VERSION "HNNBNNNYNNNNNNNNNNNNNNNNNNNNNNNNNNNNNNNNNN/4/%%%/4/'%**4NNN///"

NS_ :

BS_:

BU_: BAP_Tester CGS Gateway Gateway_PAG HUD Kombi Kombi_LB Kombi_PAG Waehlhebel_SB

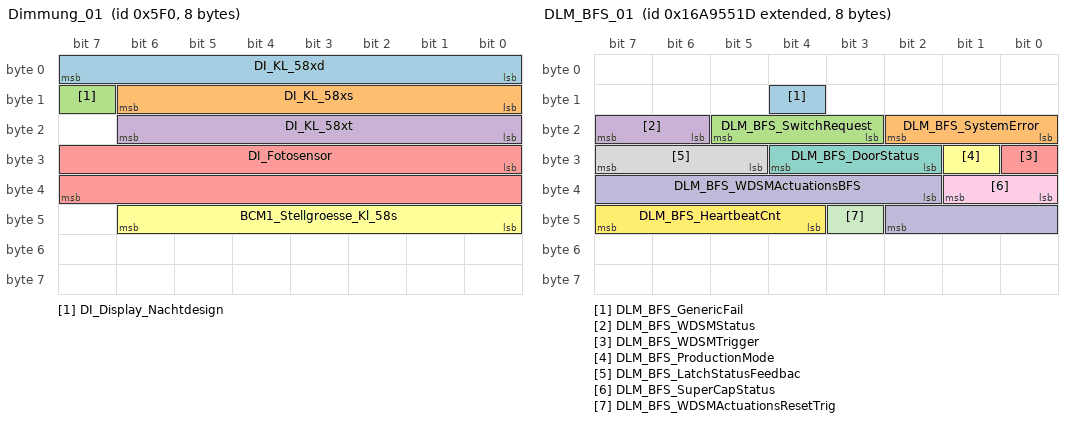
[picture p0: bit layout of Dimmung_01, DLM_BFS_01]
BO_ 1520 Dimmung_01: 8 Gateway
 SG_ DI_KL_58xd : 0|8@1+ (1,0) [0|253] ""  CGS,Kombi,Kombi_LB,Kombi_PAG,Waehlhebel_SB
 SG_ DI_KL_58xs : 8|7@1+ (1,0) [0|100] "Unit_PerCent"  Kombi,Kombi_LB,Kombi_PAG
 SG_ DI_Display_Nachtdesign : 15|1@1+ (1.0,0.0) [0.0|1] ""  HUD,Kombi,Kombi_LB
 SG_ DI_KL_58xt : 16|7@1+ (1,0) [0|100] "Unit_PerCent"  CGS,Kombi,Kombi_LB,Kombi_PAG,Waehlhebel_SB
 SG_ DI_Fotosensor : 24|16@1+ (1,0) [0|65535] ""  Kombi,Kombi_LB,Kombi_PAG
 SG_ BCM1_Stellgroesse_Kl_58s : 40|7@1+ (1,0) [0|100] ""  Vector__XXX

BO_ 2527679773 DLM_BFS_01: 8 Gateway
 SG_ DLM_BFS_GenericFail : 12|1@1+ (1.0,0.0) [0.0|1] ""  Kombi_LB
 SG_ DLM_BFS_SystemError : 16|3@1+ (1.0,0.0) [0.0|7] ""  Kombi_LB
 SG_ DLM_BFS_SwitchRequest : 19|3@1+ (1.0,0.0) [0.0|7] ""  Kombi_LB
 SG_ DLM_BFS_WDSMStatus : 22|2@1+ (1.0,0.0) [0.0|3] ""  Kombi_LB
 SG_ DLM_BFS_WDSMTrigger : 24|1@1+ (1.0,0.0) [0.0|1] ""  Kombi_LB
 SG_ DLM_BFS_ProductionMode : 25|1@1+ (1.0,0.0) [0.0|1] ""  Kombi_LB
 SG_ DLM_BFS_DoorStatus : 26|3@1+ (1.0,0.0) [0.0|7] ""  Kombi_LB
 SG_ DLM_BFS_LatchStatusFeedbac : 29|3@1+ (1.0,0.0) [0.0|7] ""  Kombi_LB
 SG_ DLM_BFS_SuperCapStatus : 32|2@1+ (1.0,0.0) [0.0|3] ""  Kombi_LB
 SG_ DLM_BFS_WDSMActuationsBFS : 34|9@1+ (1,0) [0|510] ""  Vector__XXX
 SG_ DLM_BFS_WDSMActuationsResetTrig : 43|1@1+ (1.0,0.0) [0.0|1] ""  Vector__XXX
 SG_ DLM_BFS_HeartbeatCnt : 44|4@1+ (1,0) [1|15] "Unit_None"  Vector__XXX

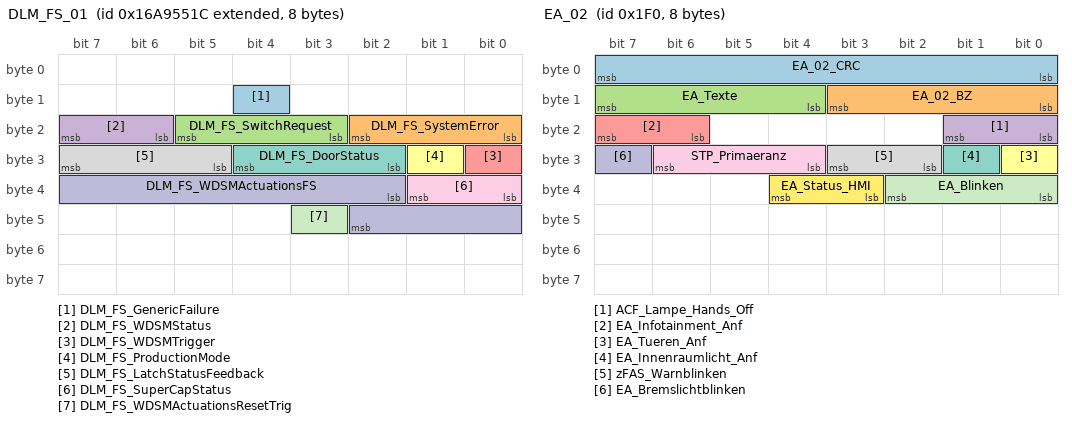
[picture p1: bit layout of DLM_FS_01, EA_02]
BO_ 2527679772 DLM_FS_01: 8 Gateway
 SG_ DLM_FS_GenericFailure : 12|1@1+ (1.0,0.0) [0.0|1] ""  Kombi_LB
 SG_ DLM_FS_SystemError : 16|3@1+ (1.0,0.0) [0.0|7] ""  Kombi_LB
 SG_ DLM_FS_SwitchRequest : 19|3@1+ (1.0,0.0) [0.0|7] ""  Kombi_LB
 SG_ DLM_FS_WDSMStatus : 22|2@1+ (1.0,0.0) [0.0|3] ""  Kombi_LB
 SG_ DLM_FS_WDSMTrigger : 24|1@1+ (1.0,0.0) [0.0|1] ""  Kombi_LB
 SG_ DLM_FS_ProductionMode : 25|1@1+ (1.0,0.0) [0.0|1] ""  Kombi_LB
 SG_ DLM_FS_DoorStatus : 26|3@1+ (1.0,0.0) [0.0|7] ""  Kombi_LB
 SG_ DLM_FS_LatchStatusFeedback : 29|3@1+ (1.0,0.0) [0.0|7] ""  Kombi_LB
 SG_ DLM_FS_SuperCapStatus : 32|2@1+ (1.0,0.0) [0.0|3] ""  Kombi_LB
 SG_ DLM_FS_WDSMActuationsFS : 34|9@1+ (1,0) [0|510] ""  Vector__XXX
 SG_ DLM_FS_WDSMActuationsResetTrig : 43|1@1+ (1.0,0.0) [0.0|1] ""  Vector__XXX

BO_ 496 EA_02: 8 Gateway
 SG_ EA_02_CRC : 0|8@1+ (1,0) [0|255] ""  Kombi,Kombi_LB,Kombi_PAG
 SG_ EA_02_BZ : 8|4@1+ (1,0) [0|15] ""  Kombi,Kombi_LB,Kombi_PAG
 SG_ EA_Texte : 12|4@1+ (1.0,0.0) [0.0|15] ""  HUD,Kombi,Kombi_LB,Kombi_PAG
 SG_ ACF_Lampe_Hands_Off : 16|2@1+ (1.0,0.0) [0.0|3] ""  HUD,Kombi,Kombi_LB,Kombi_PAG
 SG_ EA_Infotainment_Anf : 22|2@1+ (1.0,0.0) [0.0|3] ""  Vector__XXX
 SG_ EA_Tueren_Anf : 24|1@1+ (1.0,0.0) [0.0|1] ""  Vector__XXX
 SG_ EA_Innenraumlicht_Anf : 25|1@1+ (1.0,0.0) [0.0|1] ""  Vector__XXX
 SG_ zFAS_Warnblinken : 26|2@1+ (1.0,0.0) [0.0|3] ""  Vector__XXX
 SG_ STP_Primaeranz : 28|3@1+ (1.0,0.0) [0.0|7] ""  HUD,Kombi,Kombi_LB,Kombi_PAG
 SG_ EA_Bremslichtblinken : 31|1@1+ (1.0,0.0) [0.0|1] ""  Vector__XXX
 SG_ EA_Blinken : 32|3@1+ (1.0,0.0) [0.0|7] ""  Vector__XXX
 SG_ EA_Status_HMI : 35|2@1+ (1.0,0.0) [0.0|3] ""  Kombi

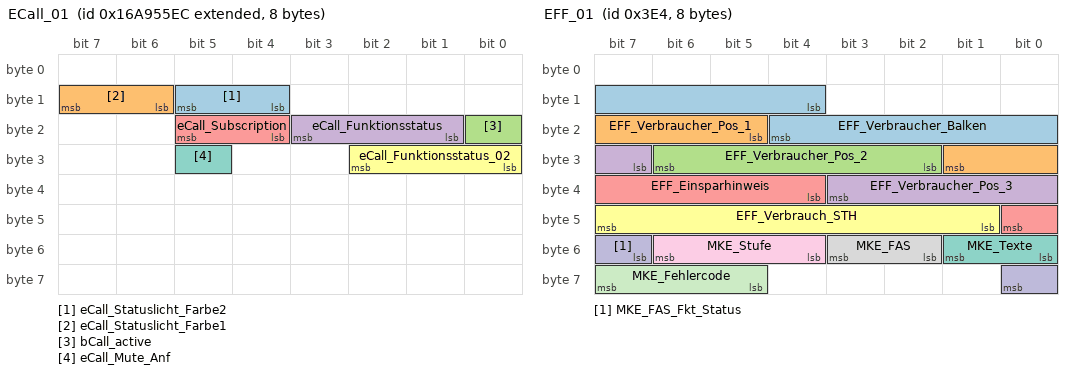
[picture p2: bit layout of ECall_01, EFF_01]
BO_ 2527679980 ECall_01: 8 Gateway
 SG_ eCall_Statuslicht_Farbe2 : 12|2@1+ (1.0,0.0) [0.0|3] ""  Vector__XXX
 SG_ eCall_Statuslicht_Farbe1 : 14|2@1+ (1.0,0.0) [0.0|3] ""  Vector__XXX
 SG_ bCall_active : 16|1@1+ (1.0,0.0) [0.0|1] ""  Vector__XXX
 SG_ eCall_Funktionsstatus : 17|3@1+ (1.0,0.0) [0.0|7] ""  Kombi,Kombi_LB,Kombi_PAG
 SG_ eCall_Subscription : 20|2@1+ (1.0,0.0) [0.0|3] ""  Kombi,Kombi_LB,Kombi_PAG
 SG_ eCall_Funktionsstatus_02 : 24|3@1+ (1.0,0.0) [0.0|7] ""  Kombi_PAG
 SG_ eCall_Mute_Anf : 29|1@1+ (1.0,0.0) [0.0|1] ""  Kombi,Kombi_LB

BO_ 996 EFF_01: 8 Gateway
 SG_ EFF_Verbraucher_Balken : 12|9@1+ (0.01,0) [0.00|5.09] "Unit_LiterPerHour"  Vector__XXX
 SG_ EFF_Verbraucher_Pos_1 : 21|5@1+ (1.0,0.0) [0.0|31] ""  Vector__XXX
 SG_ EFF_Verbraucher_Pos_2 : 26|5@1+ (1.0,0.0) [0.0|31] ""  Vector__XXX
 SG_ EFF_Verbraucher_Pos_3 : 31|5@1+ (1.0,0.0) [0.0|31] ""  Vector__XXX
 SG_ EFF_Einsparhinweis : 36|5@1+ (1.0,0.0) [0.0|31] ""  Vector__XXX
 SG_ EFF_Verbrauch_STH : 41|7@1+ (0.01,0) [0.00|1.26] "Unit_LiterPerHour"  Kombi,Kombi_LB,Kombi_PAG
 SG_ MKE_Texte : 48|2@1+ (1.0,0.0) [0.0|3] ""  Kombi,Kombi_LB,Kombi_PAG
 SG_ MKE_FAS : 50|2@1+ (1.0,0.0) [0.0|3] ""  Vector__XXX
 SG_ MKE_Stufe : 52|3@1+ (1.0,0.0) [0.0|7] ""  Vector__XXX
 SG_ MKE_FAS_Fkt_Status : 55|2@1+ (1.0,0.0) [0.0|3] ""  Vector__XXX
 SG_ MKE_Fehlercode : 61|3@1+ (1.0,0.0) [0.0|7] ""  Kombi,Kombi_LB,Kombi_PAG

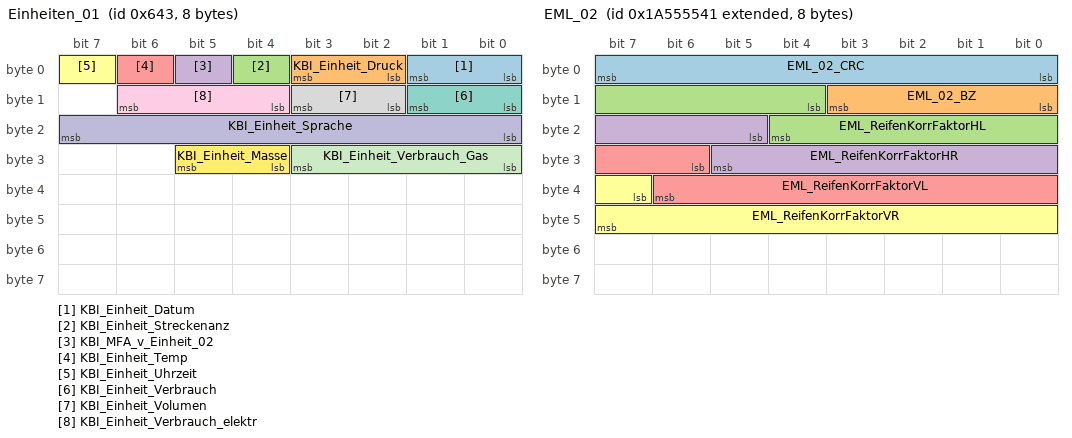
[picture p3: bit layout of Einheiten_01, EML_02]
BO_ 1603 Einheiten_01: 8 Kombi
 SG_ KBI_Einheit_Datum : 0|2@1+ (1.0,0.0) [0.0|3] ""  Gateway,Gateway_PAG
 SG_ KBI_Einheit_Druck : 2|2@1+ (1.0,0.0) [0.0|3] ""  Gateway,Gateway_PAG
 SG_ KBI_Einheit_Streckenanz : 4|1@1+ (1.0,0.0) [0.0|1] ""  Gateway,Gateway_PAG,HUD
 SG_ KBI_MFA_v_Einheit_02 : 5|1@1+ (1.0,0.0) [0.0|1] ""  Gateway,Gateway_PAG
 SG_ KBI_Einheit_Temp : 6|1@1+ (1.0,0.0) [0.0|1] ""  Gateway,Gateway_PAG,HUD
 SG_ KBI_Einheit_Uhrzeit : 7|1@1+ (1.0,0.0) [0.0|1] ""  Gateway,Gateway_PAG
 SG_ KBI_Einheit_Verbrauch : 8|2@1+ (1.0,0.0) [0.0|3] ""  Gateway,Gateway_PAG
 SG_ KBI_Einheit_Volumen : 10|2@1+ (1.0,0.0) [0.0|3] ""  Gateway,Gateway_PAG
 SG_ KBI_Einheit_Verbrauch_elektr : 12|3@1+ (1.0,0.0) [0.0|7] ""  Gateway,Gateway_PAG
 SG_ KBI_Einheit_Sprache : 16|8@1+ (1,0) [0|255] ""  Gateway,Gateway_PAG,HUD
 SG_ KBI_Einheit_Verbrauch_Gas : 24|4@1+ (1.0,0.0) [0.0|15] ""  Gateway,Gateway_PAG
 SG_ KBI_Einheit_Masse : 28|2@1+ (1.0,0.0) [0.0|3] ""  Gateway,Gateway_PAG

BO_ 1622 ELV_01: 8 Gateway
 SG_ ELV_01_CRC : 0|8@1+ (1,0) [0|255] ""  Vector__XXX
 SG_ ELV_01_BZ : 8|4@1+ (1,0) [0|15] ""  Vector__XXX
 SG_ ELV_Anf_Klemme_S : 12|1@1+ (1.0,0.0) [0.0|1] ""  Vector__XXX
 SG_ ELV_Anf_Klemme_15 : 13|1@1+ (1.0,0.0) [0.0|1] ""  Vector__XXX
 SG_ ELV_Anf_Klemme_50 : 14|1@1+ (1.0,0.0) [0.0|1] ""  Vector__XXX
 SG_ ELV_01_Sendestatus : 15|1@1+ (1.0,0.0) [0.0|1] ""  Vector__XXX
 SG_ ELV_Verriegelt : 16|1@1+ (1.0,0.0) [0.0|1] ""  Vector__XXX
 SG_ ELV_Entriegelt : 17|1@1+ (1.0,0.0) [0.0|1] ""  Vector__XXX
 SG_ ELV_ZAT_betaetigt : 18|1@1+ (1.0,0.0) [0.0|1] ""  Vector__XXX
 SG_ ELV_Lebenszustand : 19|1@1+ (1.0,0.0) [0.0|1] ""  Vector__XXX
 SG_ ELV_Anlernmodus : 20|1@1+ (1.0,0.0) [0.0|1] ""  Vector__XXX
 SG_ ELV_Klemmenfreigabe : 22|1@1+ (1.0,0.0) [0.0|1] ""  Vector__XXX
 SG_ ELV_Abbruch_Anf_Klemmenfreigabe : 23|1@1+ (1.0,0.0) [0.0|1] ""  Vector__XXX
 SG_ ELV_LED_Rot : 24|1@1+ (1.0,0.0) [0.0|1] ""  Kombi,Kombi_LB,Kombi_PAG
 SG_ ELV_LED_Gelb : 25|1@1+ (1.0,0.0) [0.0|1] ""  Vector__XXX
 SG_ ELV_Txt_Panikabschaltung : 27|1@1+ (1.0,0.0) [0.0|1] ""  Vector__XXX
 SG_ ELV_Txt_Lkg_Bewegen : 28|1@1+ (1.0,0.0) [0.0|1] ""  Kombi,Kombi_LB,Kombi_PAG
 SG_ ELV_Txt_Werkstatt : 29|1@1+ (1.0,0.0) [0.0|1] ""  Kombi,Kombi_LB,Kombi_PAG
 SG_ ELV_Txt_Defekt : 30|1@1+ (1.0,0.0) [0.0|1] ""  Kombi,Kombi_LB,Kombi_PAG
 SG_ ELV_Txt_P_Gang : 31|1@1+ (1.0,0.0) [0.0|1] ""  Vector__XXX
 SG_ ELV_Txt_PN_Gang : 32|1@1+ (1.0,0.0) [0.0|1] ""  Vector__XXX
 SG_ ELV_Txt_Kupplung : 33|1@1+ (1.0,0.0) [0.0|1] ""  Vector__XXX
 SG_ ELV_Txt_Bremse : 34|1@1+ (1.0,0.0) [0.0|1] ""  Vector__XXX
 SG_ ELV_P_verriegelt : 35|1@1+ (1.0,0.0) [0.0|1] ""  Vector__XXX

BO_ 2589283649 EML_02: 8 Gateway
 SG_ EML_02_CRC : 0|8@1+ (1,0) [0|255] ""  Vector__XXX
 SG_ EML_02_BZ : 8|4@1+ (1,0) [0|15] ""  Vector__XXX
 SG_ EML_ReifenKorrFaktorHL : 12|9@1+ (0.00048828125,0.85) [0.85000000000|1.09853515625] ""  Kombi,Kombi_LB,Kombi_PAG
 SG_ EML_ReifenKorrFaktorHR : 21|9@1+ (0.00048828125,0.85) [0.85000000000|1.09853515625] ""  Kombi,Kombi_LB,Kombi_PAG
 SG_ EML_ReifenKorrFaktorVL : 30|9@1+ (0.00048828125,0.85) [0.85000000000|1.09853515625] ""  Kombi,Kombi_LB,Kombi_PAG
 SG_ EML_ReifenKorrFaktorVR : 39|9@1+ (0.00048828125,0.85) [0.85000000000|1.09853515625] ""  Kombi,Kombi_LB,Kombi_PAG

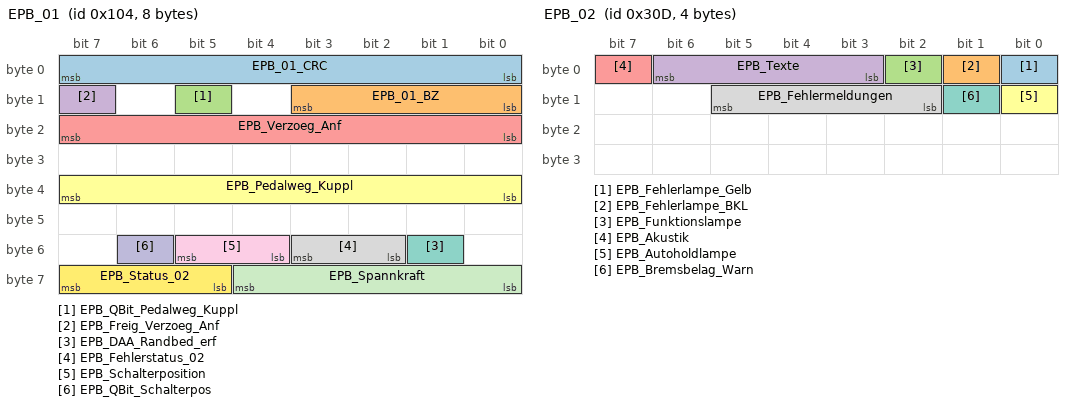
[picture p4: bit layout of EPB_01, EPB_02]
BO_ 260 EPB_01: 8 Gateway
 SG_ EPB_01_CRC : 0|8@1+ (1,0) [0|255] ""  Vector__XXX
 SG_ EPB_01_BZ : 8|4@1+ (1,0) [0|15] ""  Vector__XXX
 SG_ EPB_QBit_Pedalweg_Kuppl : 13|1@1+ (1.0,0.0) [0.0|1] ""  Vector__XXX
 SG_ EPB_Freig_Verzoeg_Anf : 15|1@1+ (1.0,0.0) [0.0|1] ""  Vector__XXX
 SG_ EPB_Verzoeg_Anf : 16|8@1+ (0.048,-7.968) [-7.968|4.224] "Unit_MeterPerSeconSquar"  Vector__XXX
 SG_ EPB_Pedalweg_Kuppl : 32|8@1+ (0.4,0) [8.0|92.0] "Unit_PerCent"  Vector__XXX
 SG_ EPB_DAA_Randbed_erf : 49|1@1+ (1.0,0.0) [0.0|1] ""  Vector__XXX
 SG_ EPB_Fehlerstatus_02 : 50|2@1+ (1.0,0.0) [0.0|3] ""  Kombi,Kombi_LB,Kombi_PAG
 SG_ EPB_Schalterposition : 52|2@1+ (1.0,0.0) [0.0|3] ""  Vector__XXX
 SG_ EPB_QBit_Schalterpos : 54|1@1+ (1.0,0.0) [0.0|1] ""  Vector__XXX
 SG_ EPB_Spannkraft : 56|5@1+ (1,0) [0|29] "Unit_KiloNewto"  Vector__XXX
 SG_ EPB_Status_02 : 61|3@1+ (1.0,0.0) [0.0|7] ""  Kombi,Kombi_LB,Kombi_PAG

BO_ 781 EPB_02: 4 Gateway
 SG_ EPB_Fehlerlampe_Gelb : 0|1@1+ (1.0,0.0) [0.0|1] ""  Vector__XXX
 SG_ EPB_Fehlerlampe_BKL : 1|1@1+ (1.0,0.0) [0.0|1] ""  Vector__XXX
 SG_ EPB_Funktionslampe : 2|1@1+ (1.0,0.0) [0.0|1] ""  Kombi,Kombi_LB,Kombi_PAG
 SG_ EPB_Texte : 3|4@1+ (1.0,0.0) [0.0|15] ""  Kombi,Kombi_LB,Kombi_PAG
 SG_ EPB_Akustik : 7|1@1+ (1.0,0.0) [0.0|1] ""  Vector__XXX
 SG_ EPB_Autoholdlampe : 8|1@1+ (1.0,0.0) [0.0|1] ""  Kombi,Kombi_LB,Kombi_PAG
 SG_ EPB_Bremsbelag_Warn : 9|1@1+ (1.0,0.0) [0.0|1] ""  Vector__XXX
 SG_ EPB_Fehlermeldungen : 10|4@1+ (1.0,0.0) [0.0|15] ""  Kombi,Kombi_LB,Kombi_PAG

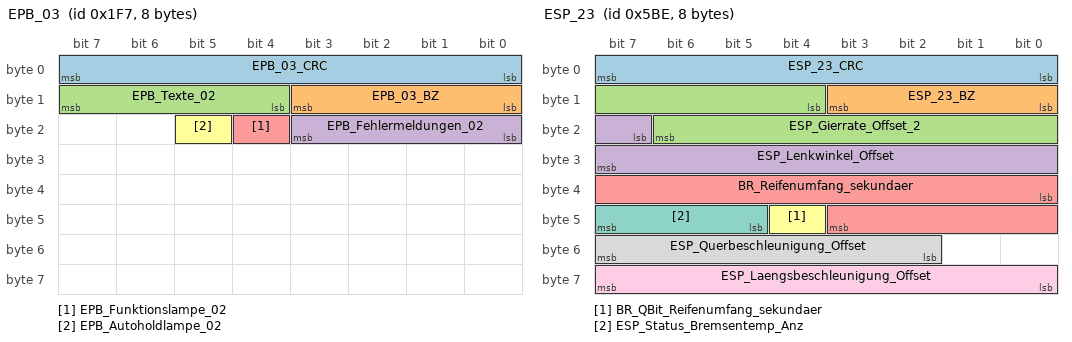
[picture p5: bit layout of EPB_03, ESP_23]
BO_ 503 EPB_03: 8 Gateway
 SG_ EPB_03_CRC : 0|8@1+ (1,0) [0|255] ""  Kombi,Kombi_LB,Kombi_PAG
 SG_ EPB_03_BZ : 8|4@1+ (1,0) [0|15] ""  Kombi,Kombi_LB,Kombi_PAG
 SG_ EPB_Texte_02 : 12|4@1+ (1.0,0.0) [0.0|15] ""  Kombi,Kombi_LB,Kombi_PAG
 SG_ EPB_Fehlermeldungen_02 : 16|4@1+ (1.0,0.0) [0.0|15] ""  Kombi,Kombi_LB,Kombi_PAG
 SG_ EPB_Funktionslampe_02 : 20|1@1+ (1.0,0.0) [0.0|1] ""  Kombi,Kombi_LB,Kombi_PAG
 SG_ EPB_Autoholdlampe_02 : 21|1@1+ (1.0,0.0) [0.0|1] ""  HUD,Kombi,Kombi_LB,Kombi_PAG

BO_ 262 ESP_05: 8 Gateway
 SG_ ESP_05_CRC : 0|8@1+ (1,0) [0|255] ""  Vector__XXX
 SG_ ESP_05_BZ : 8|4@1+ (1,0) [0|15] ""  Vector__XXX
 SG_ ESP_QBit_Bremsdruck : 12|1@1+ (1.0,0.0) [0.0|1] ""  Vector__XXX
 SG_ ESP_QBit_Fahrer_bremst : 13|1@1+ (1.0,0.0) [0.0|1] ""  Vector__XXX
 SG_ ESP_Schwelle_Unterdruck : 14|2@1+ (1.0,0.0) [0.0|3] ""  Vector__XXX
 SG_ ESP_Bremsdruck : 16|10@1+ (0.3,-30) [-30.0|276.6] "Unit_Bar"  Vector__XXX
 SG_ ESP_Fahrer_bremst : 26|1@1+ (1.0,0.0) [0.0|1] ""  Vector__XXX
 SG_ ESP_Lenkeingriff_ADS : 28|1@1+ (1.0,0.0) [0.0|1] ""  Vector__XXX
 SG_ ECD_Fehler : 32|1@1+ (1.0,0.0) [0.0|1] ""  Vector__XXX
 SG_ ECD_nicht_verfuegbar : 33|1@1+ (1.0,0.0) [0.0|1] ""  Vector__XXX
 SG_ ESP_Status_Bremsentemp : 34|1@1+ (1.0,0.0) [0.0|1] ""  Vector__XXX
 SG_ ESP_Autohold_Standby : 35|1@1+ (1.0,0.0) [0.0|1] ""  Vector__XXX
 SG_ ESP_HDC_Standby : 36|1@1+ (1.0,0.0) [0.0|1] ""  HUD,Kombi,Kombi_LB,Kombi_PAG
 SG_ ESP_HBA_aktiv : 37|1@1+ (1.0,0.0) [0.0|1] ""  Vector__XXX
 SG_ ESP_Prefill_ausgeloest : 38|1@1+ (1.0,0.0) [0.0|1] ""  Vector__XXX
 SG_ ESP_Rueckwaertsfahrt_erkannt : 39|1@1+ (1.0,0.0) [0.0|1] ""  Vector__XXX
 SG_ ESP_Status_Anfahrhilfe : 40|1@1+ (1.0,0.0) [0.0|1] ""  Vector__XXX
 SG_ ESP_HDC_aktiv : 41|1@1+ (1.0,0.0) [0.0|1] ""  HUD,Kombi,Kombi_LB,Kombi_PAG
 SG_ ESP_StartStopp_Info : 42|2@1+ (1.0,0.0) [0.0|3] ""  Vector__XXX
 SG_ ESP_Eingr_HL : 44|1@1+ (1.0,0.0) [0.0|1] ""  Kombi_LB
 SG_ ESP_Eingr_HR : 45|1@1+ (1.0,0.0) [0.0|1] ""  Kombi_LB
 SG_ ESP_Eingr_VL : 46|1@1+ (1.0,0.0) [0.0|1] ""  Kombi_LB
 SG_ ESP_Eingr_VR : 47|1@1+ (1.0,0.0) [0.0|1] ""  Kombi_LB
 SG_ ESP_BKV_Unterdruck : 48|8@1+ (4,0) [4|1012] "Unit_MilliBar"  Vector__XXX
 SG_ ESP_Autohold_aktiv : 56|1@1+ (1.0,0.0) [0.0|1] ""  Vector__XXX
 SG_ ESP_FStatus_Anfahrhilfe : 57|1@1+ (1.0,0.0) [0.0|1] ""  Vector__XXX
 SG_ ESP_Verz_EPB_aktiv : 58|1@1+ (1.0,0.0) [0.0|1] ""  Vector__XXX
 SG_ ESC_Bremslicht : 59|1@1+ (1.0,0.0) [0.0|1] ""  Vector__XXX
 SG_ ESP_Verzoeg_EPB_verf : 60|1@1+ (1.0,0.0) [0.0|1] ""  Vector__XXX
 SG_ ESP_Status_Bremsdruck : 61|1@1+ (1.0,0.0) [0.0|1] ""  Vector__XXX
 SG_ ESP_Anforderung_EPB : 62|2@1+ (1.0,0.0) [0.0|3] ""  Vector__XXX

BO_ 1629 ESP_20: 8 Gateway
 SG_ ESP_20_CRC : 0|8@1+ (1,0) [0|255] ""  Kombi_LB
 SG_ ESP_20_BZ : 8|4@1+ (1,0) [0|15] ""  Kombi_LB
 SG_ BR_Systemart : 12|2@1+ (1.0,0.0) [0.0|3] ""  Vector__XXX
 SG_ ESP_SpannungsAnf_02 : 14|2@1+ (1.0,0.0) [0.0|3] ""  Vector__XXX
 SG_ ESP_Zaehnezahl : 16|8@1+ (1,0) [0|255] ""  Kombi,Kombi_LB,Kombi_PAG
 SG_ ESP_Charisma_FahrPr : 24|4@1+ (1.0,0.0) [0.0|15] ""  Kombi_LB
 SG_ ESP_Charisma_Status : 28|2@1+ (1.0,0.0) [0.0|3] ""  Vector__XXX
 SG_ ESP_Wiederstart_Anz_01 : 30|1@1+ (1.0,0.0) [0.0|1] ""  Vector__XXX
 SG_ ESP_Wiederstart_Anz_02 : 31|1@1+ (1.0,0.0) [0.0|1] ""  Vector__XXX
 SG_ ESP_Wiederstart_Anz_03 : 32|1@1+ (1.0,0.0) [0.0|1] ""  Vector__XXX
 SG_ ESP_Wiederstart_Anz_04 : 33|1@1+ (1.0,0.0) [0.0|1] ""  Vector__XXX
 SG_ ESP_Stoppverbot_Anz_01 : 34|1@1+ (1.0,0.0) [0.0|1] ""  Vector__XXX
 SG_ ESP_Stoppverbot_Anz_02 : 35|1@1+ (1.0,0.0) [0.0|1] ""  Vector__XXX
 SG_ ESP_Stoppverbot_Anz_03 : 36|1@1+ (1.0,0.0) [0.0|1] ""  Vector__XXX
 SG_ ESP_Stoppverbot_Anz_04 : 37|1@1+ (1.0,0.0) [0.0|1] ""  Vector__XXX
 SG_ ESP_Stoppverbot_Anz_05 : 38|1@1+ (1.0,0.0) [0.0|1] ""  Kombi,Kombi_LB
 SG_ ESP_Stoppverbot_Anz_06 : 39|1@1+ (1.0,0.0) [0.0|1] ""  Vector__XXX
 SG_ ESP_Stoppverbot_Anz_07 : 40|1@1+ (1.0,0.0) [0.0|1] ""  Vector__XXX
 SG_ ESP_Stoppverbot_Anz_Std : 41|1@1+ (1.0,0.0) [0.0|1] ""  Vector__XXX
 SG_ ESP_Dachrelingsensor : 42|2@1+ (1.0,0.0) [0.0|3] ""  Vector__XXX
 SG_ ESP_Stoppverbot_Anz_08 : 44|1@1+ (1.0,0.0) [0.0|1] ""  Vector__XXX
 SG_ HDC_Charisma_FahrPr : 45|4@1+ (1.0,0.0) [0.0|15] ""  Vector__XXX
 SG_ HDC_Charisma_Status : 49|2@1+ (1.0,0.0) [0.0|3] ""  Vector__XXX
 SG_ BR_QBit_Reifenumfang : 51|1@1+ (1.0,0.0) [0.0|1] ""  Vector__XXX
 SG_ BR_Reifenumfang : 52|12@1+ (1,0) [0|4095] "Unit_MilliMeter"  Kombi_LB

BO_ 253 ESP_21: 8 Gateway
 SG_ ESP_21_CRC : 0|8@1+ (1,0) [0|255] ""  CGS,Kombi_PAG,Waehlhebel_SB
 SG_ ESP_21_BZ : 8|4@1+ (1,0) [0|15] ""  CGS,Kombi_PAG,Waehlhebel_SB
 SG_ BR_Eingriffsmoment : 12|10@1+ (1,-509) [-509|509] ""  Vector__XXX
 SG_ MSR_verfuegbar : 22|1@1+ (1.0,0.0) [0.0|1] ""  Vector__XXX
 SG_ ESP_Diagnose : 23|1@1+ (1.0,0.0) [0.0|1] ""  Kombi,Kombi_LB,Kombi_PAG
 SG_ ESC_v_Signal_Qualifier_High_Low : 24|3@1+ (1.0,0.0) [0.0|7] ""  CGS,Kombi_PAG
 SG_ ESP_Vorsteuerung : 28|1@1+ (1.0,0.0) [0.0|1] ""  Vector__XXX
 SG_ OBD_Schlechtweg : 30|1@1+ (1.0,0.0) [0.0|1] ""  Vector__XXX
 SG_ OBD_QBit_Schlechtweg : 31|1@1+ (1.0,0.0) [0.0|1] ""  Vector__XXX
 SG_ ESP_v_Signal : 32|16@1+ (0.01,0) [0.00|655.32] "Unit_KiloMeterPerHour"  CGS,Kombi,Kombi_LB,Kombi_PAG,Waehlhebel_SB
 SG_ ASR_Tastung_passiv : 48|1@1+ (1.0,0.0) [0.0|1] ""  Kombi_LB,Kombi_PAG
 SG_ ESP_Tastung_passiv : 49|1@1+ (1.0,0.0) [0.0|1] ""  Kombi_LB,Kombi_PAG
 SG_ ESP_Systemstatus : 50|1@1+ (1.0,0.0) [0.0|1] ""  Vector__XXX
 SG_ ASR_Schalteingriff : 51|2@1+ (1.0,0.0) [0.0|3] ""  Vector__XXX
 SG_ ESP_QBit_v_Signal : 55|1@1+ (1.0,0.0) [0.0|1] ""  CGS,Kombi,Kombi_LB,Kombi_PAG,Waehlhebel_SB
 SG_ ABS_Bremsung : 56|1@1+ (1.0,0.0) [0.0|1] ""  Vector__XXX
 SG_ ASR_Anf : 57|1@1+ (1.0,0.0) [0.0|1] ""  Kombi_LB
 SG_ MSR_Anf : 58|1@1+ (1.0,0.0) [0.0|1] ""  Vector__XXX
 SG_ EBV_Eingriff : 59|1@1+ (1.0,0.0) [0.0|1] ""  Vector__XXX
 SG_ EDS_Eingriff : 60|1@1+ (1.0,0.0) [0.0|1] ""  Vector__XXX
 SG_ ESP_Eingriff : 61|1@1+ (1.0,0.0) [0.0|1] ""  Vector__XXX
 SG_ ESP_ASP : 62|1@1+ (1.0,0.0) [0.0|1] ""  Vector__XXX
 SG_ ESC_Neutralschaltung : 63|1@1+ (1.0,0.0) [0.0|1] ""  Vector__XXX

BO_ 1470 ESP_23: 8 Gateway
 SG_ ESP_23_CRC : 0|8@1+ (1,0) [0|255] ""  Vector__XXX
 SG_ ESP_23_BZ : 8|4@1+ (1,0) [0|15] ""  Vector__XXX
 SG_ ESP_Gierrate_Offset_2 : 12|11@1+ (0.01,-10.23) [-10.23|10.22] "Unit_DegreOfArcPerSecon"  Vector__XXX
 SG_ ESP_Lenkwinkel_Offset : 23|9@1+ (0.1,-25.5) [-25.5|25.4] "Unit_DegreOfArc"  Vector__XXX
 SG_ BR_Reifenumfang_sekundaer : 32|12@1+ (1,0) [0|4095] "Unit_MilliMeter"  Kombi_LB
 SG_ BR_QBit_Reifenumfang_sekundaer : 44|1@1+ (1.0,0.0) [0.0|1] ""  Vector__XXX
 SG_ ESP_Status_Bremsentemp_Anz : 45|3@1+ (1.0,0.0) [0.0|7] ""  Vector__XXX
 SG_ ESP_Querbeschleunigung_Offset : 50|6@1+ (0.01,-0.3) [-0.30|0.31] "Unit_ForceOfGravi"  Vector__XXX
 SG_ ESP_Laengsbeschleunigung_Offset : 56|8@1+ (0.03125,-3.9375) [-3.93750|3.93750] "Unit_MeterPerSeconSquar"  Vector__XXX

BO_ 795 ESP_24: 8 Gateway
 SG_ ESP_24_CRC : 0|8@1+ (1,0) [0|255] ""  Kombi,Kombi_LB,Kombi_PAG
 SG_ ESP_24_BZ : 8|4@1+ (1,0) [0|15] ""  Kombi,Kombi_LB,Kombi_PAG
 SG_ ESP_Lampe : 12|1@1+ (1.0,0.0) [0.0|1] ""  Kombi,Kombi_LB,Kombi_PAG
 SG_ ABS_Lampe : 13|1@1+ (1.0,0.0) [0.0|1] ""  Kombi,Kombi_LB,Kombi_PAG
 SG_ BK_Lampe_02 : 14|2@1+ (1.0,0.0) [0.0|3] ""  Kombi,Kombi_LB,Kombi_PAG
 SG_ TC_Lampe : 16|1@1+ (1.0,0.0) [0.0|1] ""  Vector__XXX
 SG_ ESP_m_Raddrehz : 17|15@1+ (0.002,0) [0.000|65.278] "Unit_Hertz"  Kombi,Kombi_LB,Kombi_PAG
 SG_ ESP_Textanzeigen_03 : 32|5@1+ (1.0,0.0) [0.0|31] ""  Kombi,Kombi_LB,Kombi_PAG
 SG_ ESP_Meldungen : 37|3@1+ (1.0,0.0) [0.0|7] ""  Kombi,Kombi_LB,Kombi_PAG
 SG_ ESP_Wegimp_VA : 40|11@1+ (1,0) [0|2047] ""  Kombi,Kombi_LB,Kombi_PAG
 SG_ ESP_Fehlerstatus_Wegimp : 51|1@1+ (1.0,0.0) [0.0|1] ""  Kombi,Kombi_LB,Kombi_PAG
 SG_ ESP_Wegimp_Ueberlauf : 52|1@1+ (1.0,0.0) [0.0|1] ""  Kombi,Kombi_LB,Kombi_PAG
 SG_ ESP_QBit_Wegimp_VA : 53|1@1+ (1.0,0.0) [0.0|1] ""  Vector__XXX
 SG_ ESP_HDC_Geschw_Farbe : 54|1@1+ (1.0,0.0) [0.0|1] ""  HUD,Kombi,Kombi_LB,Kombi_PAG
 SG_ ESP_Off_Lampe : 55|1@1+ (1.0,0.0) [0.0|1] ""  Kombi,Kombi_LB,Kombi_PAG
 SG_ ESP_HDC_Regelgeschw : 56|7@1+ (0.32,0) [0.32|39.68] "Unit_KiloMeterPerHour"  HUD,Kombi,Kombi_LB,Kombi_PAG
 SG_ ESP_BKV_Warnung : 63|1@1+ (1.0,0.0) [0.0|1] ""  Kombi,Kombi_LB,Kombi_PAG

BO_ 508 ESP_32: 8 Gateway
 SG_ ESP_32_CRC : 0|8@1+ (1,0) [0|255] ""  Kombi_LB,Kombi_PAG
 SG_ ESP_32_BZ : 8|4@1+ (1,0) [0|15] ""  Kombi_LB,Kombi_PAG
 SG_ ESP_Status_Bremsentemp_02 : 12|2@1+ (1.0,0.0) [0.0|3] ""  Vector__XXX
 SG_ ESP_Aggregataktivitaet : 14|1@1+ (1.0,0.0) [0.0|1] ""  Vector__XXX
 SG_ ESP_Stillstandsflag : 15|1@1+ (1.0,0.0) [0.0|1] ""  Vector__XXX
 SG_ ESC_MBK_Meldungen : 16|2@1+ (1.0,0.0) [0.0|3] ""  Kombi,Kombi_LB
 SG_ ESP_EDS_Anzeige : 32|3@1+ (1.0,0.0) [0.0|7] ""  Kombi,Kombi_LB,Kombi_PAG
 SG_ RLE_Anzeigen : 35|3@1+ (1.0,0.0) [0.0|7] ""  Kombi,Kombi_LB,Kombi_PAG
 SG_ ESP_Wiederstart_Anz_Std : 38|1@1+ (1.0,0.0) [0.0|1] ""  Vector__XXX
 SG_ ESC_Anforderung_Airbrake : 39|1@1+ (1.0,0.0) [0.0|1] ""  Vector__XXX
 SG_ ESC_FBA_Meldungen : 40|2@1+ (1.0,0.0) [0.0|3] ""  Kombi,Kombi_LB,Kombi_PAG
 SG_ ESP_Rollover_Status_dyn : 42|2@1+ (1.0,0.0) [0.0|3] ""  Vector__XXX
 SG_ ESP_Rollover_Status_stat : 44|2@1+ (1.0,0.0) [0.0|3] ""  Vector__XXX
 SG_ ESP_AVH_LED : 46|3@1+ (1.0,0.0) [0.0|7] ""  Vector__XXX
 SG_ ESP_HDC_LED : 49|3@1+ (1.0,0.0) [0.0|7] ""  Kombi_LB,Kombi_PAG
 SG_ ESP_Off_LED : 52|3@1+ (1.0,0.0) [0.0|7] ""  Kombi_LB
 SG_ ESP_Notbremsanzeige : 55|1@1+ (1.0,0.0) [0.0|1] ""  Vector__XXX
 SG_ ESC_Motorstartverzoegerung : 56|1@1+ (1.0,0.0) [0.0|1] ""  Vector__XXX
 SG_ ESP_Offroad_Lampe : 57|1@1+ (1.0,0.0) [0.0|1] ""  Kombi,Kombi_LB,Kombi_PAG
 SG_ ESP_HDC_Textanzeigen : 58|5@1+ (1.0,0.0) [0.0|31] ""  Kombi,Kombi_LB,Kombi_PAG
 SG_ ESP_HOLD_verf : 63|1@1+ (1.0,0.0) [0.0|1] ""  Vector__XXX

BO_ 2589283470 ESP_35: 8 Gateway
 SG_ ESC_Kilometer : 0|20@1+ (1,0) [0|1048573] "Unit_KiloMeter"  Kombi,Kombi_LB,Kombi_PAG
 SG_ ESC_Kilometer_MUX M  : 20|1@1+ (1.0,0.0) [0.0|1] ""  Kombi,Kombi_LB,Kombi_PAG
 SG_ ESC_Signatur_Kilometer_GFA_01 m0  : 23|9@1+ (1.0,0.0) [0.0|511] ""  Kombi,Kombi_LB,Kombi_PAG
 SG_ ESC_Signatur_Kilometer_IKA_01 m1  : 23|9@1+ (1.0,0.0) [0.0|511] ""  Kombi,Kombi_LB,Kombi_PAG
 SG_ ESC_Signatur_Kilometer_GFA_02 m0  : 32|32@1+ (1.0,0.0) [0.0|4294967295] ""  Kombi,Kombi_LB,Kombi_PAG
 SG_ ESC_Signatur_Kilometer_IKA_02 m1  : 32|32@1+ (1.0,0.0) [0.0|4294967295] ""  Kombi,Kombi_LB,Kombi_PAG

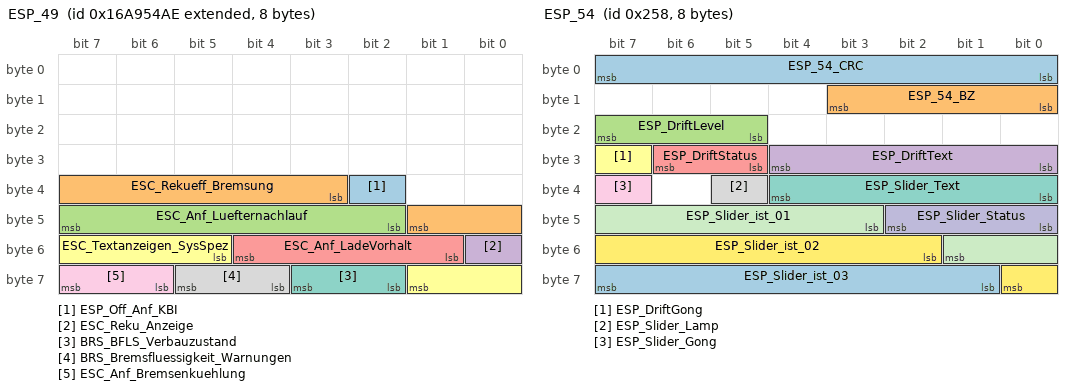
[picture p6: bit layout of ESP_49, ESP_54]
BO_ 2527679662 ESP_49: 8 Gateway
 SG_ ESP_Off_Anf_KBI : 34|1@1+ (1.0,0.0) [0.0|1] ""  Kombi
 SG_ ESC_Rekueff_Bremsung : 35|7@1+ (1,0) [0|100] "Unit_PerCent"  Vector__XXX
 SG_ ESC_Anf_Luefternachlauf : 42|6@1+ (15,0) [0|945] "Unit_Secon"  Vector__XXX
 SG_ ESC_Reku_Anzeige : 48|1@1+ (1.0,0.0) [0.0|1] ""  Kombi,Kombi_LB,Kombi_PAG
 SG_ ESC_Anf_LadeVorhalt : 49|4@1+ (1.0,0.0) [0.0|15] ""  Vector__XXX
 SG_ ESC_Textanzeigen_SysSpez : 53|5@1+ (1.0,0.0) [0.0|31] ""  Kombi,Kombi_LB,Kombi_PAG
 SG_ BRS_BFLS_Verbauzustand : 58|2@1+ (1.0,0.0) [0.0|3] ""  Kombi,Kombi_LB
 SG_ BRS_Bremsfluessigkeit_Warnungen : 60|2@1+ (1.0,0.0) [0.0|3] ""  Kombi,Kombi_LB
 SG_ ESC_Anf_Bremsenkuehlung : 62|2@1+ (1.0,0.0) [0.0|3] ""  Vector__XXX

BO_ 600 ESP_54: 8 Gateway
 SG_ ESP_54_CRC : 0|8@1+ (1,0) [0|255] ""  Kombi_LB
 SG_ ESP_54_BZ : 8|4@1+ (1,0) [0|15] ""  Kombi_LB
 SG_ ESP_DriftLevel : 21|3@1+ (1.0,0.0) [0.0|7] ""  Kombi_LB
 SG_ ESP_DriftText : 24|5@1+ (1.0,0.0) [0.0|31] ""  Kombi_LB
 SG_ ESP_DriftStatus : 29|2@1+ (1.0,0.0) [0.0|3] ""  Kombi_LB
 SG_ ESP_DriftGong : 31|1@1+ (1.0,0.0) [0.0|1] ""  Kombi_LB
 SG_ ESP_Slider_Text : 32|5@1+ (1.0,0.0) [0.0|31] ""  Kombi_LB
 SG_ ESP_Slider_Lamp : 37|1@1+ (1.0,0.0) [0.0|1] ""  Kombi_LB
 SG_ ESP_Slider_Gong : 39|1@1+ (1.0,0.0) [0.0|1] ""  Kombi_LB
 SG_ ESP_Slider_Status : 40|3@1+ (1.0,0.0) [0.0|7] ""  Kombi_LB
 SG_ ESP_Slider_ist_01 : 43|7@1+ (1,0) [0|126] ""  Kombi_LB
 SG_ ESP_Slider_ist_02 : 50|7@1+ (1,0) [0|126] ""  Kombi_LB
 SG_ ESP_Slider_ist_03 : 57|7@1+ (1,0) [0|126] ""  Kombi_LB

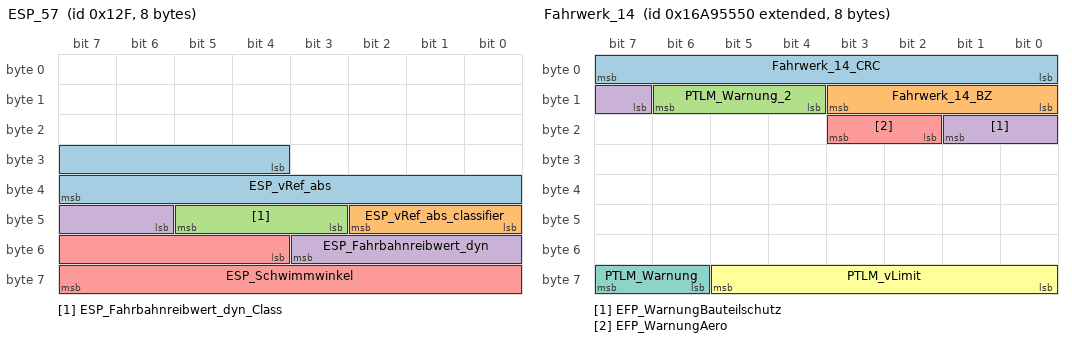
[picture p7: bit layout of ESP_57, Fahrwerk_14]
BO_ 303 ESP_57: 8 Gateway
 SG_ ESP_vRef_abs : 28|12@1+ (0.03125,0) [0.00000|127.78125] "Unit_MeterPerSecon"  Vector__XXX
 SG_ ESP_vRef_abs_classifier : 40|3@1+ (1.0,0.0) [0.0|7] ""  Vector__XXX
 SG_ ESP_Fahrbahnreibwert_dyn_Class : 43|3@1+ (1.0,0.0) [0.0|7] ""  Kombi_LB
 SG_ ESP_Fahrbahnreibwert_dyn : 46|6@1+ (0.03,0) [0.00|1.50] "Unit_None"  Kombi_LB
 SG_ ESP_Schwimmwinkel : 52|12@1+ (0.000872665,-1.78547259) [-1.785472590|1.786345255] "Unit_Radia"  Kombi_LB

BO_ 2527679824 Fahrwerk_14: 8 Gateway
 SG_ Fahrwerk_14_CRC : 0|8@1+ (1,0) [0|255] ""  Kombi,Kombi_PAG
 SG_ Fahrwerk_14_BZ : 8|4@1+ (1,0) [0|15] ""  Kombi,Kombi_PAG
 SG_ PTLM_Warnung_2 : 12|3@1+ (1.0,0.0) [0.0|7] ""  Kombi,Kombi_PAG
 SG_ EFP_WarnungBauteilschutz : 15|3@1+ (1.0,0.0) [0.0|7] ""  Kombi,Kombi_PAG
 SG_ EFP_WarnungAero : 18|2@1+ (1.0,0.0) [0.0|3] ""  Kombi_PAG
 SG_ PTLM_vLimit : 56|6@1+ (5,50) [50|355] "Unit_None"  Kombi,Kombi_PAG
 SG_ PTLM_Warnung : 62|2@1+ (1.0,0.0) [0.0|3] ""  Kombi,Kombi_PAG

BO_ 705 Fahrwerk_Anzeige_01: 8 Gateway
 SG_ Fahrwerk_Anzeige_01_CRC : 0|8@1+ (1,0) [0|255] ""  Kombi,Kombi_LB,Kombi_PAG
 SG_ Fahrwerk_Anzeige_01_BZ : 8|4@1+ (1,0) [0|15] ""  Kombi,Kombi_LB,Kombi_PAG
 SG_ EFP_Verbau_DR : 12|1@1+ (1.0,0.0) [0.0|1] ""  Kombi,Kombi_LB,Kombi_PAG
 SG_ EFP_Verbau_eAllrad : 13|1@1+ (1.0,0.0) [0.0|1] ""  Kombi,Kombi_LB,Kombi_PAG
 SG_ EFP_Verbau_LF : 14|1@1+ (1.0,0.0) [0.0|1] ""  Kombi,Kombi_LB,Kombi_PAG
 SG_ LF_Texte : 15|2@1+ (1.0,0.0) [0.0|3] ""  Kombi,Kombi_LB,Kombi_PAG
 SG_ EFP_Verbau_eAWS : 17|1@1+ (1.0,0.0) [0.0|1] ""  Kombi,Kombi_LB,Kombi_PAG
 SG_ eAWS_Warnmeldung_Prio1 : 18|1@1+ (1.0,0.0) [0.0|1] ""  Kombi,Kombi_PAG
 SG_ eAWS_Warnmeldung_Prio2 : 19|1@1+ (1.0,0.0) [0.0|1] ""  Kombi,Kombi_PAG
 SG_ LF_Texte_2 : 20|4@1+ (1.0,0.0) [0.0|15] ""  Kombi,Kombi_LB,Kombi_PAG
 SG_ EFP_Status_Taster_Lift : 24|2@1+ (1.0,0.0) [0.0|3] ""  Kombi_PAG
 SG_ EFP_Status_Taster_Fahrwerk : 26|2@1+ (1.0,0.0) [0.0|3] ""  Kombi_PAG
 SG_ FDR_Warnung_ALR : 28|2@1+ (1.0,0.0) [0.0|3] ""  Kombi,Kombi_LB,Kombi_PAG
 SG_ FDR_Warnung_TV : 30|2@1+ (1.0,0.0) [0.0|3] ""  Kombi,Kombi_LB
 SG_ EFP_Verbau_eABC : 32|1@1+ (1.0,0.0) [0.0|1] ""  Kombi,Kombi_LB
 SG_ LF_Warnung_Prio1_02 : 33|3@1+ (1.0,0.0) [0.0|7] ""  Kombi,Kombi_LB,Kombi_PAG
 SG_ LF_Warnung_Prio1 : 36|2@1+ (1.0,0.0) [0.0|3] ""  Vector__XXX
 SG_ LF_Warnung_Prio2 : 38|2@1+ (1.0,0.0) [0.0|3] ""  Kombi,Kombi_LB,Kombi_PAG
 SG_ eABC_Warnung_Prio2 : 40|2@1+ (1.0,0.0) [0.0|3] ""  Kombi
 SG_ eABC_Warnung_Prio1 : 42|3@1+ (1.0,0.0) [0.0|7] ""  Kombi
 SG_ eABC_Texte : 45|3@1+ (1.0,0.0) [0.0|7] ""  Kombi
 SG_ DR_Warnung : 48|2@1+ (1.0,0.0) [0.0|3] ""  Kombi,Kombi_LB,Kombi_PAG
 SG_ NR_LED_Offroadlevel : 50|2@1+ (1.0,0.0) [0.0|3] ""  Kombi
 SG_ NR_LED_Ladelevel : 52|2@1+ (1.0,0.0) [0.0|3] ""  Kombi
 SG_ NR_LED_Sync : 54|2@1+ (1.0,0.0) [0.0|3] ""  Kombi
 SG_ NR_LED_XtraLevel : 56|2@1+ (1.0,0.0) [0.0|3] ""  Kombi
 SG_ NR_LED_Strassenlevel : 58|2@1+ (1.0,0.0) [0.0|3] ""  Kombi
 SG_ EFP_Warnung_Naesse : 60|3@1+ (1.0,0.0) [0.0|7] ""  Kombi_PAG
 SG_ EFP_Warnung_Naesse_verf : 63|1@1+ (1.0,0.0) [0.0|1] ""  Kombi_PAG

BO_TX_BU_ 1520 :Gateway,Gateway_PAG;
BO_TX_BU_ 496 :Gateway,Gateway_PAG;
BO_TX_BU_ 2527679980 :Gateway,Gateway_PAG;
BO_TX_BU_ 996 :Gateway,Gateway_PAG;
BO_TX_BU_ 1603 :Kombi,Kombi_LB,Kombi_PAG;
BO_TX_BU_ 1622 :Gateway,Gateway_PAG;
BO_TX_BU_ 2589283649 :Gateway,Gateway_PAG;
BO_TX_BU_ 260 :Gateway,Gateway_PAG;
BO_TX_BU_ 781 :Gateway,Gateway_PAG;
BO_TX_BU_ 503 :Gateway,Gateway_PAG;
BO_TX_BU_ 262 :Gateway,Gateway_PAG;
BO_TX_BU_ 1629 :Gateway,Gateway_PAG;
BO_TX_BU_ 253 :Gateway,Gateway_PAG;
BO_TX_BU_ 1470 :Gateway,Gateway_PAG;
BO_TX_BU_ 795 :Gateway,Gateway_PAG;
BO_TX_BU_ 508 :Gateway,Gateway_PAG;
BO_TX_BU_ 2589283470 :Gateway,Gateway_PAG;
BO_TX_BU_ 2527679662 :Gateway,Gateway_PAG;
BO_TX_BU_ 2527679824 :Gateway,Gateway_PAG;
BO_TX_BU_ 705 :Gateway,Gateway_PAG;
CM_ BO_ 1520 "ab MQB nach abgestimmten FLH Dimmung";
CM_ BO_ 1603 "ab MQB mit 8 Byte";
CM_ BO_ 260 "ab MQB mit CRC-8";
CM_ BO_ 1629 "neu im MQB";
CM_ BO_ 253 "Neue Momente im MQB
Struktur ab MQB mit CRC8 entstanden aus ESP_01";
CM_ BO_ 1470 "MSS (AU724/5, LBxxx) Botschaft zur Offsetkompentation";
CM_ BO_ 795 "neu für MQB wg. Absicherung
Entstanden aus ESP_04";
CM_ BO_ 508 "CAN-Botschaft";

CM_ SG_ 1520 BCM1_Stellgroesse_Kl_58s "Rohwert Dimmpoti";
CM_ SG_ 1520 DI_Display_Nachtdesign "Für Displays sind oft  automatische Umschaltungen von Tag-/Nachtdesign vorgesehen.
Es gibt jedoch Zustände, an denen auch tagsüber das Abblendlicht eingeschaltet ist.
z.B. Dauerfahrlicht, Geschwindigkeitsabhängiges 'Licht-An-Bei-Autobahn', 'Regenlicht',";
CM_ SG_ 1520 DI_Fotosensor "Helligkeitswert Fotosensor
Für die Dimmung relevanter Wert zur Sensierung der Umgebungshelligkeit
Im Detail beschrieben im 'Funktionslastenheft Dimmung MQB'.";
CM_ SG_ 1520 DI_KL_58xd "Klemme 58xd Display- und Funktionsbeleuchtung
Mit der Klemme 58xd wird die Helligkeit der Display- und der Funktionsbeleuchtungen der Schalter gesteuert.
Im Detail beschrieben im 'Funktionslastenheft Dimmung MQB'.";
CM_ SG_ 1520 DI_KL_58xs "Suchbeleuchtung Schalter
EIN-AUS-Schaltalgorithmus der allgemeinen Schaltersuchbeleuchtung. 
Im Detail beschrieben im 'Funktionslastenheft Dimmung MQB'.
";
CM_ SG_ 1520 DI_KL_58xt "Timergesteuerte Suchbeleuchtung
Der EIN-AUS-Schaltalgorithmus für die vor- und nachlaufende Schaltersuchbeleuchtungen beim Ein- & Aussteigen; z.B.: Start/Stop-Taster.
Im Detail beschrieben im 'Funktionslastenheft Dimmung MQB'.";

CM_ SG_ 2527679773 DLM_BFS_DoorStatus "Door state from latch state sensoring reading, passenger side. Set to invalid when a fault to latch sensoring is detected";
CM_ SG_ 2527679773 DLM_BFS_GenericFail "It informs about SmartLatch error state, passenger side 
If DTCs are supported, this fault flag is basically informing that at least one DTC is set.";
CM_ SG_ 2527679773 DLM_BFS_HeartbeatCnt "This counter increments each 1s from 1 to 15 and then restart the counting. Value 0 is allowed only after electrical reset, passenger side Signal receivers can detect DLM communication issues thanks to this signal.";
CM_ SG_ 2527679773 DLM_BFS_LatchStatusFeedbac "Latch locking status feedback, passenger side";
CM_ SG_ 2527679773 DLM_BFS_ProductionMode "Set to 'Active' when production mode is Active, passenger side";
CM_ SG_ 2527679773 DLM_BFS_SuperCapStatus "It shall be set when a determined life time (first trial value: 15 years) has been elapsed. After that, supercap functionality is always guaranteed but with degraded performances, passenger side.
It is set to 'Discharged' when capacitors voltage is too l";
CM_ SG_ 2527679773 DLM_BFS_SwitchRequest "Indicates the internal unlatch request status from switch pression.
None (no unlatch request)
No Unlatch (unlatch requested but non foreseen by software)
Single Pull (when a unlatch with singel pull is performing)
Wait for second press (when a double ";
CM_ SG_ 2527679773 DLM_BFS_SystemError "It shall be set to:
No Fault (when no fault is detected)
Peripheral Fail(internal/external handle switch, CDL/DL/COM lines, WDSM Fail, Pydos fail)
SuperCap Supply (when super cap supply is switched on and CAN is running)
Internal Fault 
(microcontrol";
CM_ SG_ 2527679773 DLM_BFS_WDSMActuationsBFS "It carries the information of how many actuations (either from user or actuator test) have been made in the lifespan of the other (driver) side WDSM. In case of DLM replacement, this backup value will be read from the other DLM and written.";
CM_ SG_ 2527679773 DLM_BFS_WDSMActuationsResetTrig "Trigger sent by the replaced DLM in order to ask the other (driver) side DLM to send the backup value of WDSM actuations. Value is then internally restored";
CM_ SG_ 2527679773 DLM_BFS_WDSMStatus "Signal is set to 'Life Cycle Expired' when a prefixed time is elapsed from the WDSM installation with its basic setting.
It is set to 'Discharged' when capacitors voltage is too low.
'Life Cycle Expired' state has priority over 'Discharged'
WDSM replac";
CM_ SG_ 2527679773 DLM_BFS_WDSMTrigger "Signal is set to 1 when basic setting for WDSM installation date storing is called. Signal returns to 0 after a key cycle, passenger side";

CM_ SG_ 2527679772 DLM_FS_DoorStatus "Door state from latch state sensoring reading, driver side. Set to invalid when a fault to latch sensoring is detected";
CM_ SG_ 2527679772 DLM_FS_GenericFailure "It informs about SmartLatch error state, driver side 
If DTCs are supported, this fault flag is basically informing that at least one DTC is set.";
CM_ SG_ 2527679772 DLM_FS_LatchStatusFeedback "Latch locking status feedback, driver side";
CM_ SG_ 2527679772 DLM_FS_ProductionMode "Set to 'Active' when production mode is Active, driver side";
CM_ SG_ 2527679772 DLM_FS_SuperCapStatus "It shall be set when a determined life time (first trial value: 15 years) has been elapsed. After that, supercap functionality is always guaranteed but with degraded performances, driver side.
It is set to 'Discharged' when capacitors voltage is too low";
CM_ SG_ 2527679772 DLM_FS_SwitchRequest "Indicates the internal unlatch request status from switch pression.
None (no unlatch request)
No Unlatch (unlatch requested but non foreseen by software)
Single Pull (when a unlatch with singel pull is performing)
Wait for second press (when a double ";
CM_ SG_ 2527679772 DLM_FS_SystemError "It shall be set to:
No Fault (when no fault is detected)
Peripheral Fail(internal/external handle switch, CDL/DL/COM lines, WDSM Fail, Pydos fail)
SuperCap Supply (when super cap supply is switched on and CAN is running)
Internal Fault 
(microcontrol";
CM_ SG_ 2527679772 DLM_FS_WDSMActuationsFS "It carries the information of how many WDSM actuations (either from user or actuator test) have been made in the lifespan of the module. This info is sent to the other (passenger) side DLM to be stored as a backup. In case of DLM replacement, this backup ";
CM_ SG_ 2527679772 DLM_FS_WDSMActuationsResetTrig "Trigger sent by the replaced DLM in order to ask the other (passenger) side DLM to send the backup value of WDSM actuations. Value is then internally restored";
CM_ SG_ 2527679772 DLM_FS_WDSMStatus "Signal is set to 'Life Cycle Expired' when a prefixed time is elapsed from the WDSM installation with its basic setting.
It is set to 'Discharged' when capacitors voltage is too low.
'Life Cycle Expired' state has priority over 'Discharged'
WDSM replac";
CM_ SG_ 2527679772 DLM_FS_WDSMTrigger "Signal is set to 1 when basic setting for WDSM installation date storing is called. Signal returns to 0 after a key cycle, driver side";

CM_ SG_ 496 ACF_Lampe_Hands_Off "Anzeige, ob der Fahrer die Hände am Lenkrad hat.";
CM_ SG_ 496 EA_02_BZ "Botschaftszähler
Botschaft asynchron geroutet. Zählerwert kann springen.";
CM_ SG_ 496 EA_02_CRC "Für MLB:
'Berechnung siehe Lastenheft 'Kommunikationsabsicherung für Flexray und CAN''

Ab MQB und MLBevo:
'Berechnung siehe Lastenheft 'End-to-End Kommunikationsabsicherung'

Endwerte siehe Begleitdokument 'S-PDU Kennungsfolge'";
CM_ SG_ 496 EA_Blinken "Emergency Assist Anforderung Blinker";
CM_ SG_ 496 EA_Bremslichtblinken "Die Funktion Emergency Alert fordert ein Blinken der Bremsleuchten an.";
CM_ SG_ 496 EA_Infotainment_Anf "Emergency Assist Anforderung Absenkung Infotainment-Funktionen";
CM_ SG_ 496 EA_Innenraumlicht_Anf "Anforderung Innenraumbeleuchtung durch den Emergency Assist";
CM_ SG_ 496 EA_Status_HMI "Anzeige Emergency Assist-Statusleuchte im Fahrerinformationsdisplay";
CM_ SG_ 496 EA_Texte "Anzeige der EA Texte";
CM_ SG_ 496 EA_Tueren_Anf "Emergency Assist Anforderung Türen entriegeln";
CM_ SG_ 496 STP_Primaeranz "Primäranzeige des Staupiloten";
CM_ SG_ 496 zFAS_Warnblinken "Anforderung Warnblinken durch zFAS Funktionen.";

CM_ SG_ 2527679980 bCall_active "1: Breakdown call is active
0: BreakdownCall is inactive";
CM_ SG_ 2527679980 eCall_Funktionsstatus "HMI-Aufruf im Kombi (Broadcast)
Fehlerfälle die im Kombi angezeigt werden können";
CM_ SG_ 2527679980 eCall_Funktionsstatus_02 "Erweiterung des Funktionsstatus für andere Funktionen
ACN aktiv, MEC aktiv
MEC = manual emergency call = maueller Notruf
ACN = automatic emergency call = automatischer Notruf";
CM_ SG_ 2527679980 eCall_Mute_Anf "Signalisiert die Aufforderungen alle Soundquellen im Fahrzeug während eines aktiven Notrufs zu muten";
CM_ SG_ 2527679980 eCall_Statuslicht_Farbe1 "Steuerung Statuslicht (Farbe1) für Funktionsrückmeldungen Emergency Call / SOS Hilferuf,
z.B. LED-Anzeige im Dachmodul.";
CM_ SG_ 2527679980 eCall_Statuslicht_Farbe2 "Steuerung Statuslicht (Farbe2) für Funktionsrückmeldungen Emergency Call / SOS Hilferuf,
z.B. LED-Anzeige im Dachmodul.";
CM_ SG_ 2527679980 eCall_Subscription "Anzeige 'Service Unsubscribed' im Kombi - Aktualisierte Namensgebung";

CM_ SG_ 996 EFF_Einsparhinweis "Anforderung der Anzeige von veschiedenen Life-Tipps";
CM_ SG_ 996 EFF_Verbrauch_STH "Verbrauchsanteil der Standheizung im Komfortverbrauch (siehe EFF_Verbraucher_Balken)";
CM_ SG_ 996 EFF_Verbraucher_Balken "Anzeige der Zusatzverbraucher (Anzeige 0-5,09 l/h in 0,01 l/h - Schritten) für BCmE (Bordcomputer mit Effizienzprogramm)";
CM_ SG_ 996 EFF_Verbraucher_Pos_1 "Name des Zusatzverbraucher an Listenposition '1' der Top-Verbraucher für die Balkenanzeige 'Zusatzverbraucher'";
CM_ SG_ 996 EFF_Verbraucher_Pos_2 "Name des Zusatzverbraucher an Listenposition '2' der Top-Verbraucher für die Balkenanzeige 'Zusatzverbraucher'";
CM_ SG_ 996 EFF_Verbraucher_Pos_3 "Name des Zusatzverbraucher an Listenposition '3' der Top-Verbraucher für die Balkenanzeige 'Zusatzverbraucher'";
CM_ SG_ 996 MKE_FAS "Sicherheitshinweis für FAS.";
CM_ SG_ 996 MKE_FAS_Fkt_Status "Statussignal für FAS-Profilemaster.";
CM_ SG_ 996 MKE_Fehlercode "Fehlercode der Funktion Müdigkeitserkennung.";
CM_ SG_ 996 MKE_Stufe "Das Signal bildet die Müdigkeitsstufe im Kombi ab:
0 - deaktiviert
1 - nicht_verfügbar
2 - Stufe_1
3 - Stufe_2
4 - Stufe_3
5 - Stufe_4
6 - reserviert
7 - reserviert";
CM_ SG_ 996 MKE_Texte "Systemhinweis und Sicherheitshinweis für Anzeige im Kombi";

CM_ SG_ 1603 KBI_Einheit_Datum "Anzeigevariante des Datums";
CM_ SG_ 1603 KBI_Einheit_Druck "Einheit des Druckes";
CM_ SG_ 1603 KBI_Einheit_Masse "Einheit der Masse (Verwendung z.B. ASTA)";
CM_ SG_ 1603 KBI_Einheit_Sprache "Siehe BAP-Datenfestlegung UnitMaster";
CM_ SG_ 1603 KBI_Einheit_Streckenanz "Einheit der Streckenanzeige";
CM_ SG_ 1603 KBI_Einheit_Temp "Einheit der Temperatur";
CM_ SG_ 1603 KBI_Einheit_Uhrzeit "Anzeigevariante der Uhrzeit";
CM_ SG_ 1603 KBI_Einheit_Verbrauch "Einheit der Verbrauchs";
CM_ SG_ 1603 KBI_Einheit_Verbrauch_elektr "Einheit elektrischer Verbrauch";
CM_ SG_ 1603 KBI_Einheit_Verbrauch_Gas "Unterscheidung zwischen M3/h und kg/h für Komfortverbrauchsberechnung.";
CM_ SG_ 1603 KBI_Einheit_Volumen "Einheit des Volumens";
CM_ SG_ 1603 KBI_MFA_v_Einheit_02 "Einheit der Geschwindigkeit, die vom Fahrer im Car-Menü gewählt wurde. Veränderliche Grösse, im Gegensatz zur Einheit des Tachokranzes.

Redundant in der Einheiten_01 Botschaft definiert, um Konsistenz zur BAP-Festlegung zu haben.";

CM_ SG_ 1622 ELV_01_BZ "4bit Botschaftszaehler, wird mit jeder Sendebotschaft inkrementiert";
CM_ SG_ 1622 ELV_01_CRC "Ab MQB und MLBevo:
'Berechnung siehe Lastenheft 'End-to-End Kommunikationsabsicherung''

Endwerte siehe Begleitdokument 'S-PDU Kennungsfolgen'";
CM_ SG_ 1622 ELV_01_Sendestatus "Zeigt an, ob die ELV für einen begrenzten Zeitraum mit verkürzter Zykluszeit (50ms) sendet. Das ist bis zur KL15ein notwendig, um eine Motorstartverzögerung zu vermeiden.";
CM_ SG_ 1622 ELV_Abbruch_Anf_Klemmenfreigabe "Klemmenanforderung des Kessy-SG wird von der ELV verworfen und muss vom Kessy zurückgenommen werden.";
CM_ SG_ 1622 ELV_Anf_Klemme_15 "Signal wird zur Plausibilisierung parrallel zum Klemmensignal auf dem CAN übertragen
Anforderung Klemme_15";
CM_ SG_ 1622 ELV_Anf_Klemme_50 "Signal wird zur Plausibilisierung parrallel zum Klemmensignal auf dem CAN übertragen
Anforderung Klemme_50";
CM_ SG_ 1622 ELV_Anf_Klemme_S "Signal wird zur Plausibilisierung parallel zum Klemmensignal auf dem CAN übertragen
Anforderung Klemme_S";
CM_ SG_ 1622 ELV_Anlernmodus "Im Anlernmodus (1) ist zum Einschalten der KLS u.KL15 keine Authentifizierung der WFS notwendig. KL50 ist nicht einschaltbar.
Auslieferungszustand ist (1)";
CM_ SG_ 1622 ELV_Entriegelt "ELV im Zustand entriegelt
";
CM_ SG_ 1622 ELV_Klemmenfreigabe "Freigabe/Quittierung der ELV für das Einschalten der Klemme 15 und Klemme S";
CM_ SG_ 1622 ELV_Lebenszustand "Auslieferungszustand ist (0)
Lebenszustand";
CM_ SG_ 1622 ELV_LED_Gelb "Warnlampe Gelb";
CM_ SG_ 1622 ELV_LED_Rot "Warnlampe Rot";
CM_ SG_ 1622 ELV_P_verriegelt "Position P-verriegelt vom Gangwahlhebel";
CM_ SG_ 1622 ELV_Txt_Bremse "Text: 'Bremspedal betätigen!'";
CM_ SG_ 1622 ELV_Txt_Defekt "Text: 'Lenkungsverriegelung defekt!'";
CM_ SG_ 1622 ELV_Txt_Kupplung "Text: 'Kupplungspedal betätigen!'";
CM_ SG_ 1622 ELV_Txt_Lkg_Bewegen "Text: 'Lenkrad bewegen!'";
CM_ SG_ 1622 ELV_Txt_P_Gang "Text: 'Wählhebel in Position P bringen!'";
CM_ SG_ 1622 ELV_Txt_Panikabschaltung "Text: 'Notabschaltung''";
CM_ SG_ 1622 ELV_Txt_PN_Gang "Text: 'Wählhebel in Position P/N bringen!'";
CM_ SG_ 1622 ELV_Txt_Werkstatt "Text: 'Lenkungsverriegelung! Werkstatt!'";
CM_ SG_ 1622 ELV_Verriegelt "ELV im Zustand verriegelt
";
CM_ SG_ 1622 ELV_ZAT_betaetigt "Zündanlass-Taster (ZAT) betätigt";

CM_ SG_ 2589283649 EML_02_BZ "4bit Botschaftszähler, wird mit jeder Sendebotschaft inkrementiert";
CM_ SG_ 2589283649 EML_02_CRC "Für MLB:
Berechnung siehe Lastenheft 'Kommunikationsabsicherung für FlexRay und CAN'
Ab MQB und MLBevo:
Berechnung siehe Lastenheft 'End-to-End Kommunikationsabsicherung'

Endwerte siehe Begleitdokument 'S-PDU Kennungsfolgen'";
CM_ SG_ 2589283649 EML_ReifenKorrFaktorHL "Korrekturfaktor Reifenumfang Hinten Links";
CM_ SG_ 2589283649 EML_ReifenKorrFaktorHR "Korrekturfaktor Reifenumfang Hinten Rechts";
CM_ SG_ 2589283649 EML_ReifenKorrFaktorVL "Korrekturfaktor Reifenumfang Vorne Links";
CM_ SG_ 2589283649 EML_ReifenKorrFaktorVR "Korrekturfaktor Reifenumfang Vorne Rechts";

CM_ SG_ 260 EPB_01_BZ "Botschaft asynchron geroutet. Zählerwert kann springen.";
CM_ SG_ 260 EPB_01_CRC "Für MLB:
'Berechnung siehe Lastenheft 'Kommunikationsabsicherung für FlexRay und CAN''

Ab MQB und MLBevo:
'Berechnung siehe Lastenheft 'End-to-End Kommunikationsabsicherung''

Endwerte siehe Begleitdokument 'S-PDU Kennungsfolgen'";
CM_ SG_ 260 EPB_DAA_Randbed_erf "Die Randbedingungen zum automatischen Öffnen der EPB (Funktion DAA) sind erfüllt und ein Betätigen des Fahrpedals führt zum Öffnen der EPB.";
CM_ SG_ 260 EPB_Fehlerstatus_02 "Anpassung der Texte an die  aktuellen Zustände für weitergehende Funktionen (Stillstandsmanager)";
CM_ SG_ 260 EPB_Freig_Verzoeg_Anf "Verzögerungsanforderung	";
CM_ SG_ 260 EPB_Pedalweg_Kuppl "Signal entspricht Tastverhältnis des PWM. Gesamtweg Kupplungspedal 10% bis 90%, damit zu erwartende Werte 25 bis 225. 25 bei Kupplungspedal nicht getreten, 225 bei Kupplungspedal voll durchgetreten.
2% Toleranz wird im Wertebereich ermöglicht (8%-92%).
";
CM_ SG_ 260 EPB_Schalterposition "Spiegelt die Schalterstellung wieder.

0x3 = Schalterfehler ";
CM_ SG_ 260 EPB_Spannkraft "Erzeugte Spannkraft. Bezieht sich auf die Aktuatoren.

MQB: Spannkraftwerte entsprechen nicht den tatsächlichen Spannkräften. Genauere Informationen bitte in der Fachabteilung erfragen! ";
CM_ SG_ 260 EPB_Status_02 "Erweiterung der Zustände um ein genaueres Bild des aktuellen Zustandes zu erhalten für weitergehende Funktionen ( Stillstandsmanager)
";
CM_ SG_ 260 EPB_Verzoeg_Anf "Steuerungsanforderung an andere Systeme (z.B. ESP), um während der Fahrt, durch den Handbremsschalter ausgelöst, zu bremsen (ECD-Funktion)";

CM_ SG_ 781 EPB_Akustik "Bit wird gesetzt, wenn bei v > 0 eine Fahreran-forderung schließen vorhanden ist (ECD angefordert). PQ46-Kombi sendet Warnton (600Hz) solange dieses Bit gesetzt ist.
Anzeige eines Warntextes
";
CM_ SG_ 781 EPB_Autoholdlampe "Autoholdlampe im Kombi, grünes P
";
CM_ SG_ 781 EPB_Bremsbelag_Warn "Mindestens ein Bremsbelag an der Hinterachse am Fahrzeug ist unter Minimum";
CM_ SG_ 781 EPB_Fehlerlampe_BKL "Die BKL dient als rote Fehlerlampe für die EPB. Sie wird vom EPB-SG aktiv ausgeschaltet.";
CM_ SG_ 781 EPB_Fehlerlampe_Gelb "Fehlerlampe für nicht liegenbleiberreleavante Fehler";
CM_ SG_ 781 EPB_Fehlermeldungen "Über das Signal werden bestimmte Fehlertexte und -lampen im Kombi angefordert.";
CM_ SG_ 781 EPB_Funktionslampe "Bit wird nur gesetzt, wenn volle Spannkraft auf beiden Seiten erreicht. PQ46: Bit wird gesetzt, wenn BKL direkt vom EPB-SG als Funktionslampe angesteuert wird.

Bei Audi: Rote Lampe (rotes P) im Kombiinstrument
";
CM_ SG_ 781 EPB_Texte "EPB-Texte für Kombi
9 bei Audi aktuell nicht bedient.
10 bei Audi hinzugefügt für RSe
11 bei PAG Duo Servo Parkbremse aktuell nicht bedient 
12 bei PAG Duo Servo Parkbremse aktuell nicht bedient 
13 nur bei ParkPilot/IPA verwendet";

CM_ SG_ 503 EPB_03_BZ "Botschaftszähler
Botschaft asynchron geroutet. Zählerwert kann springen.";
CM_ SG_ 503 EPB_03_CRC "Für MLB:
'Berechnung siehe Lastenheft 'Kommunikationsabsicherung für FlexRay und CAN''

Ab MQB und MLBevo:
'Berechnung siehe Lastenheft 'End-to-End Kommunikationsabsicherung''

Endwerte siehe Begleitdokument 'S-PDU Kennungsfolgen'
";
CM_ SG_ 503 EPB_Autoholdlampe_02 "Autoholdlampe im Kombi, grünes P";
CM_ SG_ 503 EPB_Fehlermeldungen_02 "Über das Signal werden bestimmte Fehlertexte und -lampen im Kombi angefordert.";
CM_ SG_ 503 EPB_Funktionslampe_02 "Bit wird nur gesetzt, wenn volle Spannkraft auf beiden Seiten erreicht. Rote Lampe (rotes P) im Kombiinstrument";
CM_ SG_ 503 EPB_Texte_02 "EPB-Texte für Kombi
9 bei Audi aktuell nicht bedient.
10 bei Audi hinzugefügt für RSe
11 bei PAG Duo Servo Parkbremse aktuell nicht bedient 
12 bei PAG Duo Servo Parkbremse aktuell nicht bedient";

CM_ SG_ 262 ECD_Fehler "ESP kann die Verzögerungsregelung/Bremsenregelung aufgrund eines internen Fehlers nicht ausführen, mit Fehlereintrag im ESP.
";
CM_ SG_ 262 ECD_nicht_verfuegbar "ESP kann die Verzögerungsregelung/Bremsenregelung temporär nicht ausführen (z.B. Netzwerkmanagement-Betriebe - KL15 Aus; v<18km/h; ESP in Diagnose, ...), ohne Fehlereintrag im ESP.

";
CM_ SG_ 262 ESC_Bremslicht "Die Bremslichtansteuerung erfolgt, wenn die Ist_Verzögerung für eine Dauer von  (ca.100 ms) die bewertete Verzögerungsschwelle unterschreitet (Einschaltschwelle Bremslicht),  Bremsdruck vorhanden aufgrund ECD , EMP, HMS oder HDC. Bei AWV2 wird von Beginn ";
CM_ SG_ 262 ESP_05_BZ "Botschaft asynchron geroutet. Zählerwert kann springen.";
CM_ SG_ 262 ESP_05_CRC "Für MLB:
'Berechnung siehe Lastenheft 'Kommunikationsabsicherung für FlexRay und CAN''

Ab MQB und MLBevo:
'Berechnung siehe Lastenheft 'End-to-End Kommunikationsabsicherung''

Endwerte siehe Begleitdokument 'S-PDU Kennungsfolgen'";
CM_ SG_ 262 ESP_Anforderung_EPB "ESP fordert von der EPB Öffnen bzw. Schliessen an. Notwendig wegen Autohold-Funktion.";
CM_ SG_ 262 ESP_Autohold_aktiv "Rückmeldung an EPB, dass Autohold aktiv ist.";
CM_ SG_ 262 ESP_Autohold_Standby "Rückmeldung an EPB, dass der Fahrer die Funktion Autohold mindestens einmal angefordert hat. Im Fall eines ESP-Ausfalles oder einer Übernahmeaufforderung erfolgt die EPB-Zuschaltung nur nach Setzen dieses Bits. Bit wird gesetzt nach Betätigung des Autohol";
CM_ SG_ 262 ESP_BKV_Unterdruck "Der maximale Wert wird auf 1012 mbar begrenzt.
Dieses Signal wird im AU64x nicht unterstützt.

Hinweis: Auch bei nicht verbautem BKV-Unterdrucksensor könnte während der Initialisierung der Initialisierungswert gesendet werden.";
CM_ SG_ 262 ESP_Bremsdruck "Rohwert des Bremsdrucks
Für Fahrzeuge mit elektrischem Bremskraftverstärker gilt: Aus dem Signal ESP_Bremsdruck lässt sich kein Fahrerbremswunsch ableiten. Das Signal bildet lediglich den hydraulischen Anteil der Fahrzeugverzögerung ab. Der Rohwert des S";
CM_ SG_ 262 ESP_Eingr_HL "wird von QSP und Neigungsanzeige verwendet

Flag wird vom ESP gesetzt, sobald aufgrund eines ESP-Eingriffs am Rad aktiv Druck aufgebaut wird.
Frühestens mit öffnen des Ventils und spätestens bei einem Bremsmoment von 100Nm. Flag bleibt solange gesetzt ";
CM_ SG_ 262 ESP_Eingr_HR "wird von QSP und Neigungsanzeige verwendet

Flag wird vom ESP gesetzt, sobald aufgrund eines ESP-Eingriffs am Rad aktiv Druck aufgebaut wird.
Frühestens mit öffnen des Ventils und spätestens bei einem Bremsmoment von 100Nm. Flag bleibt solange gesetzt ";
CM_ SG_ 262 ESP_Eingr_VL "wird von QSP und Neigungsanzeige verwendet

Flag wird vom ESP gesetzt, sobald aufgrund eines ESP-Eingriffs am Rad aktiv Druck aufgebaut wird.
Frühestens mit öffnen des Ventils und spätestens bei einem Bremsmoment von 100Nm. Flag bleibt solange gesetzt ";
CM_ SG_ 262 ESP_Eingr_VR "wird von QSP und Neigungsanzeige verwendet

Flag wird vom ESP gesetzt, sobald aufgrund eines ESP-Eingriffs am Rad aktiv Druck aufgebaut wird.
Frühestens mit öffnen des Ventils und spätestens bei einem Bremsmoment von 100Nm. Flag bleibt solange gesetzt ";
CM_ SG_ 262 ESP_Fahrer_bremst "Bit wird gesetzt beim Überschreiten der Bremsdruckschwelle

Weiterführende Informationen im Lastenheft spezifiziert und in der entsprechenden Fachabteilung zu erfragen.
";
CM_ SG_ 262 ESP_FStatus_Anfahrhilfe "Bei gesetztem Bit steht die Funktion Berganfahrassistent (Hillhold) nicht zur Verfügung";
CM_ SG_ 262 ESP_HBA_aktiv "Verwendung/Bedienung ab D4
Signal gibt an, ob der hydraulische Bremsassistent im Regler aktiviert wurde

Im MQB wird das Signal nicht unterstützt!

";
CM_ SG_ 262 ESP_HDC_aktiv "MQB und AU57x Allroad: Mit diesem Statusbit wird eine gerade aktive Regelung des Bergabfahrassistenten (Hill Descent Control) signalisiert.";
CM_ SG_ 262 ESP_HDC_Standby "Verwendung/Bedienung im MQB und AU57x Allroad:
Flag wird vom ESP gesetzt, wenn über den HDC-Taster die HDC-Funktion eingeschalten wurde";
CM_ SG_ 262 ESP_Lenkeingriff_ADS "Im Falle eines fahrzeugstabilisierenden Lenkeingriffs des ADS-Systems soll ACC/GRA deaktiviert werden.

Im MQB wird dieses Signal nicht unterstützt!";
CM_ SG_ 262 ESP_Prefill_ausgeloest "MLB: Verwendung/Bedienung ab D4
zeigt, ob die Funktion Prefill (aufgrund Fahrpedalgradient) ausgelöst wird; zeigt keinen Funktionszustand bezüglich Fehlerstilllegung

MQB: Wird gesetzt bei jeder Art von aktivem Prefill";
CM_ SG_ 262 ESP_QBit_Bremsdruck "QBit des Bremsdrucks. Gesetzt bei Ersatzwert, Init oder Fehler.";
CM_ SG_ 262 ESP_QBit_Fahrer_bremst "Gültigkeit der Bremsdruckschwelleninformation des Signals ESP_Fahrer_bremst vom ESP SG
0x1 = Druckschwelleninformation kann noch nicht oder aufgrund eines Fehlers nicht ausgegeben werden
";
CM_ SG_ 262 ESP_Rueckwaertsfahrt_erkannt "nur bei AU57x und AU416 sowie Audi B8PA
Info, ob Rückwärtsfahrt über internen Algorithmus sicher erkannt

Im MQB wird das Signal nicht unterstützt!";
CM_ SG_ 262 ESP_Schwelle_Unterdruck "Verwendung im MQB für HBV-Projekte oder wenn für St/St ein Unterdrucksensor verbaut ist";
CM_ SG_ 262 ESP_StartStopp_Info "Stopp-Freigabe und Start-Anforderung an den Start-Stopp-Koordinator";
CM_ SG_ 262 ESP_Status_Anfahrhilfe "Funktionsstatus des Berganfahrassistenten
MQB: Auswertung im Getriebe zwecks Standabkopplung";
CM_ SG_ 262 ESP_Status_Bremsdruck "MLB: Bei gesetztem Bit liegt p > ca. 2 bar an, hervorgerufen durch Fahrer, ASR, FZR, ECD, Bremsregler ... bei Abfall des Bits ist p < X bar, bei aktivem ECD-Eingriff Ende des Eingriffs 

Weiterführende Informationen im Lastenheft spezifiziert und in der";
CM_ SG_ 262 ESP_Status_Bremsentemp "ECD-Bremsscheibentemperaturmodell. Rückmeldung für Sender einer ECD Verzögerungsanforderung, ohne Fehlereintrag im ESP";
CM_ SG_ 262 ESP_Verz_EPB_aktiv "Bei gesetztem Bit wird die Verzögerungsanforderung von EPB umgesetzt.";
CM_ SG_ 262 ESP_Verzoeg_EPB_verf "Bei gesetztem Bit ist der Verzögerungsregeler für EPB verfügbar.";

CM_ SG_ 1629 BR_QBit_Reifenumfang "Gesetzt bei Ersatzwert, Init oder Fehler.";
CM_ SG_ 1629 BR_Reifenumfang "Mittlerer Radumfang gerechnet in Millimeter.
Von der Bremse plausibilisierter Wert (Kopie von KBI_Reifenumfang wenn dieser plausibel) oder Ersatzwert aus Bremse wenn KBI_Reifenumfang unplausibel. Bitte das QBit beachten!

Im MEB wird das Signal KBI_Rei";
CM_ SG_ 1629 BR_Systemart "Identifikation des verbauten Bremssystems

Dient dem Kombi zur Plausibilisierung";
CM_ SG_ 1629 ESP_20_BZ "Botschaft asynchron geroutet. Zählerwert kann springen.";
CM_ SG_ 1629 ESP_20_CRC "Für MLB:
'Berechnung siehe Lastenheft 'Kommunikationsabsicherung für FlexRay und CAN''

Ab MQB und MLBevo:
'Berechnung siehe Lastenheft 'End-to-End Kommunikationsabsicherung''

Endwerte siehe Begleitdokument 'S-PDU Kennungsfolgen'";
CM_ SG_ 1629 ESP_Charisma_FahrPr "MLBevo: Aktuelles Fahrprogramm des Charisma-Teilnehmers (siehe Systemlastenheft Drive Select)
MQB: Istwert der Kennlinie (siehe Systemlastenheft MQB FPA)";
CM_ SG_ 1629 ESP_Charisma_Status "Systemstatus des Charismateilnehmers

Wert 0x3 ist nur für Fahrzeuge ab MQB relevant";
CM_ SG_ 1629 ESP_Dachrelingsensor "Erkennung auf Verbau des Dachrelingsensors und Dachquerträger.";
CM_ SG_ 1629 ESP_SpannungsAnf_02 "Forderung des ESP-SG's zur Spannungsanhebung.";
CM_ SG_ 1629 ESP_Stoppverbot_Anz_01 "Dieses Signal gibt die detaillierte Begründung für ein Stoppverbot vom Bremsensteuergerät an.";
CM_ SG_ 1629 ESP_Stoppverbot_Anz_02 "Dieses Signal gibt die detaillierte Begründung für ein Stoppverbot vom Bremsensteuergerät an.";
CM_ SG_ 1629 ESP_Stoppverbot_Anz_03 "Dieses Signal gibt die detaillierte Begründung für ein Stoppverbot vom Bremsensteuergerät an.";
CM_ SG_ 1629 ESP_Stoppverbot_Anz_04 "Dieses Signal gibt die detaillierte Begründung für ein Stoppverbot vom Bremsensteuergerät an.";
CM_ SG_ 1629 ESP_Stoppverbot_Anz_05 "Dieses Signal gibt die detaillierte Begründung für ein Stoppverbot vom Bremsensteuergerät an.";
CM_ SG_ 1629 ESP_Stoppverbot_Anz_06 "Dieses Signal gibt die detaillierte Begründung für ein Stoppverbot vom Bremsensteuergerät an.";
CM_ SG_ 1629 ESP_Stoppverbot_Anz_07 "Dieses Signal gibt die detaillierte Begründung für ein Stoppverbot vom Bremsensteuergerät an.";
CM_ SG_ 1629 ESP_Stoppverbot_Anz_08 "Dieses Signal gibt die detaillierte Begründung für ein Stoppverbot vom Bremsensteuergerät an.";
CM_ SG_ 1629 ESP_Stoppverbot_Anz_Std "Dieses Signal gibt die detaillierte Begründung für ein Stoppverbot vom Bremsensteuergerät an.";
CM_ SG_ 1629 ESP_Wiederstart_Anz_01 "Dieses Signal gibt die detaillierte Begründung für einen Wiederstart vom Bremsensteuergerät an. ";
CM_ SG_ 1629 ESP_Wiederstart_Anz_02 "Dieses Signal gibt die detaillierte Begründung für einen Wiederstart vom Bremsensteuergerät an. ";
CM_ SG_ 1629 ESP_Wiederstart_Anz_03 "Dieses Signal gibt die detaillierte Begründung für einen Wiederstart vom Bremsensteuergerät an. ";
CM_ SG_ 1629 ESP_Wiederstart_Anz_04 "Dieses Signal gibt die detaillierte Begründung für einen Wiederstart vom Bremsensteuergerät an.";
CM_ SG_ 1629 ESP_Zaehnezahl "Konstanter Wert der Zähnezahl des verwendeten Impulsrades wird ausgegeben, jeder Empfänger der Wegimpulse muss die Zähnezahl einlesen, um eine volle Umdrehung des Rades zu erkennen. 

Weiterführende Informationen im Lastenheft spezifiziert und in der en";
CM_ SG_ 1629 HDC_Charisma_FahrPr "MLBevo: Aktuelles Fahrprogramm des Charisma-Teilnehmers (siehe Systemlastenheft Drive Select)
MQB: Istwert der Kennlinie (siehe Systemlastenheft MQB FPA)";
CM_ SG_ 1629 HDC_Charisma_Status "Systemstatus des Charismateilnehmers

Wert 0x3 ist nur für Fahrzeuge ab MQB relevant";

CM_ SG_ 253 ABS_Bremsung "Antiblockiersystem, Bit zeigt auch Druckabbau an (z.B. ESP hat zuviel Druck aufgebaut oder ungebremste Regelung auf Bahnübergang)
Weiterführende Informationen im Lastenheft spezifiziert und in der entsprechenden Fachabteilung zu erfragen.";
CM_ SG_ 253 ASR_Anf "MLB: Die Momentenanforderung 'ASR_MSR_Moment_schnell' und 'ASR_Moment_langsam' sind auszuführen
MQB: Die Momentenanforderung 'BR_Eingriffsmoment' ist auszuführen";
CM_ SG_ 253 ASR_Schalteingriff "Wunsch an das Getriebe während einer ASR Regelung

MLB: Es wird nur 0x0 und 0x1 genutzt

";
CM_ SG_ 253 ASR_Tastung_passiv "ASR deaktiviert oder Schwellen geändert (projektabhängig)
Weiterführende Informationen im Lastenheft spezifiziert und in der entsprechenden Fachabteilung zu erfragen.
";
CM_ SG_ 253 BR_Eingriffsmoment "Einheitenloser Wert! Faktor in MO_Faktor_Momente_02 in Motor_Code_01 beachten!
Schnelle reduzierende (ASR) oder erhöhende (MSR) Momentanforderung an den Motor.";
CM_ SG_ 253 EBV_Eingriff "Elektronische Bremskraftverteilung, aktueller Eingriff (Druckhalten, Druckabbau)

Im MLB: kein ABS / ESP-Eingriff ???";
CM_ SG_ 253 EDS_Eingriff "Elektronische Differentialsperre";
CM_ SG_ 253 ESC_Neutralschaltung "Aufforderung seitens ABS an das Getriebe die Momentenübertragung zu unterbrechen";
CM_ SG_ 253 ESC_v_Signal_Qualifier_High_Low "Das Qualifizerungssignal ESC_v_Signal_Qualifier_High_Low gibt eine Information über die Güte der vom Bremsregelsystem ausgegebenen Geschwindigkeitsinformation 'mittlere Geschwindigkeit', wobei Vertrauensbereiche für das ausgegebene Geschwindigkeitssignal ";
CM_ SG_ 253 ESP_21_BZ "Botschaft asynchron geroutet. Zählerwert kann springen.";
CM_ SG_ 253 ESP_21_CRC "Für MLB:
'Berechnung siehe Lastenheft 'Kommunikationsabsicherung für FlexRay und CAN''

Ab MQB und MLBevo:
'Berechnung siehe Lastenheft 'End-to-End Kommunikationsabsicherung''

Endwerte siehe Begleitdokument 'S-PDU Kennungsfolgen'";
CM_ SG_ 253 ESP_ASP "MLB: Anhaenger-Stabilisierungs-Programm
MQB: Gespannstabilisierung";
CM_ SG_ 253 ESP_Diagnose "MLB: Nach Diagnoseende wird ein SW-Reset ausgelöst welcher einen Kommunikatiosausfall für max. 150ms verursacht. Dies ist bei SG mit verschärfter Timeoutüberwachung (nicht nach Konzern-LH) zu beachten.

MQB: Weiterführende Informationen im Lastenheft sp";
CM_ SG_ 253 ESP_Eingriff "Eingriff des Fahrdynamikreglers";
CM_ SG_ 253 ESP_QBit_v_Signal "Geschwindigkeit wird vom ABS/ASR oder ESP aus Ersatzwerten errechnet, wenn Bit gesetzt ist. Güte des Signals ist verändert.";
CM_ SG_ 253 ESP_Systemstatus "Fehler steht für Stillegung ESP mit Fehlereintrag.

MLB: Flag wird bei Unterspannung im Stand bis einmalig 6km/h (AU48x) oder 10 km/h (AU641, AU57x) überschritten nicht gesetzt (Ausblendung Startvorgang)
Im AU64x, AU57x gilt ESP D4 Funktionsanforderung";
CM_ SG_ 253 ESP_Tastung_passiv "ESP deaktiviert oder Schwellen geändert (projektabhängig)
Weiterführende Informationen im Lastenheft spezifiziert und in der entsprechenden Fachabteilung zu erfragen.";
CM_ SG_ 253 ESP_v_Signal "Geschwindigkeitssignal vom ABS/ASR oder ESP. Mittelwert der angetriebenen Räder.
Bei MSR oder ABS Eingriffen wird die ABS-Referenzgeschwindigkeit für >= 200ms eingespiegelt (Zeit wird mit Aktiv-Flanke der Funktionsbits getriggert)

MQB: Bei Frontantrie";
CM_ SG_ 253 ESP_Vorsteuerung "zur Unterscheidung zwischen ESP-Vorsteuermaßnahmen und ESP-Regeleingriffen";
CM_ SG_ 253 MSR_Anf "MLB: Die Momentenanforderung 'ASR_MSR_Moment_schnell' ist auszuführen.
MQB: Die Momentenanforderung 'BR_Eingriffsmoment' ist auszuführen";
CM_ SG_ 253 MSR_verfuegbar "Anzeige Verfügbarkeit der MSR Funktion 
0 = verfuegbar (MSR_Vollsystem oder MSR_Backup)
1 = nicht_verfuegbar (Init und Fehler)";
CM_ SG_ 253 OBD_Schlechtweg "Für Ausblendung der Zündaussetzererkennung im Motorsteuergerät (Otto). Bit wird gesetzt, wenn Rad-Drehbeschleunigung im ESP > Grenzwert ist. Vorteil gegenüber Radgeschwindigkeiten, dass ESP alle 2 ms dynamisch die Rad-Drehbeschleunigung errechnet und dem ";

CM_ SG_ 1470 BR_QBit_Reifenumfang_sekundaer "QBit des Signals BR_Reifenumfang_sekundaer. 
Gesetzt bei Ersatzwert, Init oder Fehler.";
CM_ SG_ 1470 BR_Reifenumfang_sekundaer "Radumfang der Sekundärchse gerechnet in Millimeter.
Von der Bremse plausibilisierter Wert (Kopie von KBI_Reifenumfang_sekundaer wenn dieser plausibel) 
oder Ersatzwert aus Bremse wenn KBI_Reifenumfang_sekundaer unplausibel. Bitte das QBit beachten!
";
CM_ SG_ 1470 ESP_23_CRC "Für MLB:
'Berechnung siehe Lastenheft 'Kommunikationsabsicherung für FlexRay und CAN''

Ab MQB und MLBevo:
'Berechnung siehe Lastenheft 'End-to-End Kommunikationsabsicherung''

Endwerte siehe Begleitdokument 'S-PDU Kennungsfolgen'";
CM_ SG_ 1470 ESP_Gierrate_Offset_2 "Gierratenoffset berechnet durch ESP-Modell. 

nur für MLBevo gilt:
Der Offsetwert entspricht der Abweichung nach Anti-DIN-Vorzeichenlogik.
Gierrate_korrigiert = Gierrate_Rohwert + Gierratenoffset";
CM_ SG_ 1470 ESP_Laengsbeschleunigung_Offset "Offset der Längsbeschleunigung
Längsbeschleunigung = Rohwert - Offset

nur für MLBevo gilt:
Laengsbeschleunigungsoffset berechnet durch ESP-Modell. 
Laengsbeschleunigung_korrigiert = Laengsbeschleunigung_Rohwert - Laengsbeschleunigungsoffset";
CM_ SG_ 1470 ESP_Lenkwinkel_Offset "Lenkwinkelsoffset berechnet durch ESP-Modell!

nur für MLBevo gilt:
Der Offsetwert entspricht der Abweichung nach Anti-DIN-Vorzeichenlogik.
Lenkwinkel_korrigiert = Lenkwinkel_Rohwert + Lenkwinkeloffset";
CM_ SG_ 1470 ESP_Querbeschleunigung_Offset "Offset der Querbeschleunigung
Querbeschleunigung = Rohwert - Offset

nur für MLBevo gilt:
Querbeschleunigungsoffset berechnet durch ESP-Modell. 
Der Offsetwert entspricht der Abweichung nach Anti-DIN-Vorzeichenlogik.
Querbeschleunigung_korrigiert = ";
CM_ SG_ 1470 ESP_Status_Bremsentemp_Anz "Anzeigesignal für Bremsentemperatur";

CM_ SG_ 795 ABS_Lampe "Sicherheitswarnlampe

Weiterführende Informationen im Lastenheft spezifiziert und in der entsprechenden Fachabteilung zu erfragen.";
CM_ SG_ 795 BK_Lampe_02 "Typ1_ein_statisch signalisiert EBV-Ausfall
MQB: wird auch bei HBV-Ausfall verwendet.

Typ1_ein_statisch: wird bei AUDI für Aktivierung der roten BKL ohne Text und Akustik verwendet (z.B. Lampenaufprüfung).
Typ2_ein_statisch: signalisiert elektrischen ";
CM_ SG_ 795 ESP_24_CRC "Für MLB:
'Berechnung siehe Lastenheft 'Kommunikationsabsicherung für FlexRay und CAN''

Ab MQB und MLBevo:
'Berechnung siehe Lastenheft 'End-to-End Kommunikationsabsicherung''

Endwerte siehe Begleitdokument 'S-PDU Kennungsfolgen'";
CM_ SG_ 795 ESP_BKV_Warnung "ESP sendet im Hinweis- /Störungsfall an das Kombi Informationen zum Anzeigen (Text + Akustik)

Im MQB wird dieses Signal nicht unterstützt!
";
CM_ SG_ 795 ESP_Fehlerstatus_Wegimp "Weiterführende Informationen im Lastenheft spezifiziert und in der entsprechenden Fachabteilung zu erfragen.

MLB: Fehler wird gesetzt, wenn beide ESP-Drehzahlfühler an der Vorderachse defekt sind.

MQB: Fehler wird gesetzt, wenn beide Raddrehzahlfühl";
CM_ SG_ 795 ESP_HDC_Geschw_Farbe "Farbdarstellung der angezeigten HDC-Geschwindigkeit";
CM_ SG_ 795 ESP_HDC_Regelgeschw "Verwendung/Bedienung nur im AU57x Allroad:
HDC-Geschwindigkeit
Dient der Anzeige der HDC-Geschwindigkeit und eines Bergabfahrsymbols im Kombi.
HDC-Standby wird gesetzt sobald der Fahrer den HDC-Taster aktiviert hat.
Bei HDC-Off oder während der Initia";
CM_ SG_ 795 ESP_Lampe "Zustand der Fahrdynamikregelungslampe (MLB: ASR und/oder ESP, MQB: nur ESP)

Weiterführende Informationen im Lastenheft spezifiziert und in der entsprechenden Fachabteilung zu erfragen.";
CM_ SG_ 795 ESP_m_Raddrehz "Radumdrehungen pro Sekunde sind Eingangsgröße für die Geschwindigkeitsberechnung im Kombi. Aus dieser Raddrehzahl und dem Radumfang wird die Fahrzeuggeschwindigkeit errechnet.

MLB: Exklusiver Empfänger ist das Kombiinstrument!
MQB: Bei Frontantrieb un";
CM_ SG_ 795 ESP_Meldungen "ESP sendet im Hinweis- /Störungsfall an das Kombi Informationen zum Anzeigen

Weiterführende Informationen im Lastenheft spezifiziert und in der entsprechenden Fachabteilung zu erfragen.
Ergänzender Hinweis:
1 = Autohold_Hinweis_1 (Anfahrassistent: nu";
CM_ SG_ 795 ESP_Off_Lampe "Bit zur Ansteuerung der separaten ESP-off-Lampe im Kombi (Gesetzesforderung USA)

MLB:
Verwendung/Bedienung ab D4";
CM_ SG_ 795 ESP_QBit_Wegimp_VA "Gesetzt bei Ersatzwert, Init oder Fehler.";
CM_ SG_ 795 ESP_Textanzeigen_03 "Textanzeigen der Fahrdynamikregelung im Kombiinstrument

Weiterführende Informationen im Lastenheft spezifiziert und in der entsprechenden Fachabteilung zu erfragen.

Der Signalwert 24 wird nur im BY736 verwendet.";
CM_ SG_ 795 ESP_Wegimp_Ueberlauf "Der Wegimpulszähler ist pro Zündungslauf mindestens einmal übergelaufen

Weiterführende Informationen im Lastenheft spezifiziert und in der entsprechenden Fachabteilung zu erfragen.";
CM_ SG_ 795 ESP_Wegimp_VA "Weiterführende Informationen im Lastenheft spezifiziert und in der entsprechenden Fachabteilung zu erfragen.

MLB: Die Wegimpulse Vorderachse sind die gemittelten Werte (reine mathematische Operation: Addition und Division durch zwei, keine Filterung) d";
CM_ SG_ 795 TC_Lampe "M-ABS Lampe (separate Lampe für M-ABS-Systeme Markt Brasilien)

Weiterführende Informationen im Lastenheft spezifiziert und in der entsprechenden Fachabteilung zu erfragen.";

CM_ SG_ 508 ESC_Anforderung_Airbrake "ESC fordert die Bremsperformancestellung der aktiven Aerodynamik";
CM_ SG_ 508 ESC_FBA_Meldungen "Hinweis an den Fahrer über das Kombi, bei dauerhafter Bergabfahrt einen Gang einzulegen um die Motorbremse zu nutzen.
Unterscheidung zwischen: 
Handschalterfahrzeugen (FBA_Warnung_aktiv_MT)
Automatikfahrzeugen (FBA_Warnung_aktiv_AT)";
CM_ SG_ 508 ESC_MBK_Meldungen "Das Signal steuert die Schaltempfehlung im Kombi, die bei Bergabfahrt den Fahrer darauf hinweist in eine geeignete Fahrstufe zu schalten um eine Rekuperation zu ermöglichen.";
CM_ SG_ 508 ESC_Motorstartverzoegerung "Mit dem Signal 'Motorstartverzögerung' wird den aktiven Teilnehmern ermöglicht, einen Motorstart durch die Start-Stop-Funktion zu verzögern.";
CM_ SG_ 508 ESP_32_BZ "Botschaft asynchron geroutet. Zählerwert kann springen.";
CM_ SG_ 508 ESP_32_CRC "Für MLB:
'Berechnung siehe Lastenheft 'Kommunikationsabsicherung für FlexRay und CAN''

Ab MQB und MLBevo:
'Berechnung siehe Lastenheft 'End-to-End Kommunikationsabsicherung''

Endwerte siehe Begleitdokument 'S-PDU Kennungsfolgen'";
CM_ SG_ 508 ESP_Aggregataktivitaet "Info über die Aktivität des ESP Aggregats bei aktivem Druckaufbau oder Ventilaktivität";
CM_ SG_ 508 ESP_AVH_LED "Ansteuerung der AVH Funktions-LED durch das BCM.
0 = LED aus
1 = LED ein
2 = LED blinken
3 = Funktion gesperrt, LED aus
4 = frei
5 = frei
6 = Init
7 = frei";
CM_ SG_ 508 ESP_EDS_Anzeige "Grafische Anzeige der EDS-Funktion im Kombiinstrument und MMI für Bentley";
CM_ SG_ 508 ESP_HDC_LED "Ansteuerung der HDC LED in der Schalterleiste durch BCM
0 = LED aus
1 = LED ein
2 = LED blinken
3 = Funktion gesperrt, LED aus
4 = frei
5 = frei
6 = Init
7 = frei";
CM_ SG_ 508 ESP_HDC_Textanzeigen "Textanzeigen der HDC im Kombiinstrument
Zustände 16,17,18 nur für Porsche";
CM_ SG_ 508 ESP_HOLD_verf "Das Signal ESP_HOLD_verf = 1 signalisiert dem Empfänger, dass die Aktivierungsbedingungen für die autonome HOLD-Funktion erfüllt sind (Steigung > parametrierbare Grenzsteigung mit Wunschfahrtrichtung bergauf) und die autonome HOLD-Funktion aktivierbar ist";
CM_ SG_ 508 ESP_Notbremsanzeige "ABS/ASR oder ESP hat Notbremssituation erkannt.
Weiterführende Informationen im Lastenheft spezifiziert und in der entsprechenden Fachabteilung zu erfragen.

";
CM_ SG_ 508 ESP_Off_LED "Ansteuerung der ESP-Off LED in der Schalterleiste durch BCM
0 = LED aus
1 = LED ein
2 = LED blinken
3 = Funktion gesperrt, LED aus
4 = frei
5 = frei
6 = Init
7 = frei";
CM_ SG_ 508 ESP_Offroad_Lampe "Anzeige der ESC-Offroad-Lampe im Kombiinstrument für Bentley";
CM_ SG_ 508 ESP_Rollover_Status_dyn "Information vom ESP an die Dämpferregelung über den dynamischen Rolloverstatus";
CM_ SG_ 508 ESP_Rollover_Status_stat "Information vom ESP an die Dämpferregelung über den statischen Rolloverstatus";
CM_ SG_ 508 ESP_Status_Bremsentemp_02 "Bremsscheibentemperaturmodell. Rückmeldung für Sender einer Verzögerungsanforderung";
CM_ SG_ 508 ESP_Stillstandsflag "Bei RB-Projekten wird das Stillstandsflag gesetzt, wenn der absolute Stillstand der Raddrehzahlsensoren erkannt wurde, d.h. kein Zahn bewegt sich mehr. Dieses Bit wird bspw. im MOST für TV-Tuner-Abschaltung Australien verwendet, d.h. leichte Erschütterung";
CM_ SG_ 508 ESP_Wiederstart_Anz_Std "Dieses Signal gibt die detaillierte Begründung für einen Wiederstart vom Bremsensteuergerät ausgelöst durch die HBC Funktion an.";
CM_ SG_ 508 RLE_Anzeigen "Anzeigen für die Radlöseerkennung";

CM_ SG_ 2589283470 ESC_Kilometer "Kilometerstand aus dem ESC ";
CM_ SG_ 2589283470 ESC_Kilometer_MUX "Zeigt an ob ein GFA oder IKA signierter Kilometerstand übertragen wird";
CM_ SG_ 2589283470 ESC_Signatur_Kilometer_GFA_01 "GFA Signatur des Kilometerstandes";
CM_ SG_ 2589283470 ESC_Signatur_Kilometer_GFA_02 "GFA Signatur des Kilometerstandes";
CM_ SG_ 2589283470 ESC_Signatur_Kilometer_IKA_01 "IKA Signatur des Kilometerstandes";
CM_ SG_ 2589283470 ESC_Signatur_Kilometer_IKA_02 "IKA Signatur des Kilometerstandes";

CM_ SG_ 2527679662 BRS_BFLS_Verbauzustand "Verbauzustand Bremsfluessigkeitsstand-Sensor (BFLS).

0: Init
1: Sensor nicht am BRS verbaut (MLBevo-Standard: BCM1)
2: Sensor am BRS verbaut

ESP & ESP_PAG: Dauerhafte Bedienung Init.";
CM_ SG_ 2527679662 BRS_Bremsfluessigkeit_Warnungen "Ansteuerung Bewarnung Bremsflüssigkeitsmangel.

0: Init
1: Fuellstand i.O.
2: Warnstufe 1 (gelbe Lampe)
3: Warnstufe 2 (rote Lampe)";
CM_ SG_ 2527679662 ESC_Anf_Bremsenkuehlung "Signal steuert das Oeffnen des Bremsenkuehlkanals und ggf. das Aktivieren eines unterstützenden Lüfters.";
CM_ SG_ 2527679662 ESC_Anf_LadeVorhalt "Steuert den Ladevorhalt, um Rekuperation bei langer Bergabfahrt sicherzustellen.";
CM_ SG_ 2527679662 ESC_Anf_Luefternachlauf "Steuert den Nachlauf des Kühlerlüfters zur Bremsenkühlung nach Klemme 15 aus.";
CM_ SG_ 2527679662 ESC_Reku_Anzeige "Mit der Reku Anzeige wird eine durch einen Fehler verursachte nicht verfügbare Rekuperationsfunktion
im Kombi angezeigt";
CM_ SG_ 2527679662 ESC_Rekueff_Bremsung "Verhältnis aus Systemdruck zu Fahrerbremswunsch für die letzte Bremsung in %";
CM_ SG_ 2527679662 ESC_Textanzeigen_SysSpez "Textanzeigen des Bremsregelsystems zur Anzeige von systemspezifischen Textmeldungen";
CM_ SG_ 2527679662 ESP_Off_Anf_KBI "Anzeige ESP Off Bestätigungsaufforderung";

CM_ SG_ 600 ESP_54_BZ "4bit Botschaftszähler, wird mit jeder Sendebotschaft inkrementiert";
CM_ SG_ 600 ESP_54_CRC "Für MLB:
Berechnung siehe Lastenheft 'Kommunikationsabsicherung für FlexRay und CAN'
Ab MQB und MLBevo:
Berechnung siehe Lastenheft 'End-to-End Kommunikationsabsicherung'

Endwerte siehe Begleitdokument 'S-PDU Kennungsfolgen'";
CM_ SG_ 600 ESP_DriftGong "Drift gong for kombi";
CM_ SG_ 600 ESP_DriftLevel "Drift level current position in ESC";
CM_ SG_ 600 ESP_DriftStatus "Status of drift controller in ESC";
CM_ SG_ 600 ESP_DriftText "Drift text for kombi";
CM_ SG_ 600 ESP_Slider_Gong "Slider gong  for kombi";
CM_ SG_ 600 ESP_Slider_ist_01 "Slider 1 current position in ESC";
CM_ SG_ 600 ESP_Slider_ist_02 "Slider 2 current position in ESC";
CM_ SG_ 600 ESP_Slider_ist_03 "Slider 3 current position in ESC";
CM_ SG_ 600 ESP_Slider_Lamp "Slider lamp  for kombi";
CM_ SG_ 600 ESP_Slider_Status "Status of Slider controller in ESC";
CM_ SG_ 600 ESP_Slider_Text "Slider text message for kombi";

CM_ SG_ 303 ESP_Fahrbahnreibwert_dyn "Dynamisch geschätzter Reibwert zwischen Reifen und Straße (ESP)";
CM_ SG_ 303 ESP_Fahrbahnreibwert_dyn_Class "Klassifizierungssignal für dynamische Reibwertinformation";
CM_ SG_ 303 ESP_Schwimmwinkel "Schwimmwinkel aus der ESP LB";
CM_ SG_ 303 ESP_vRef_abs "Fahrzeuggeschwindigkeit in Bewegungsrichtung aus der ESP LB";
CM_ SG_ 303 ESP_vRef_abs_classifier "Klassifizierungssignal für geschätzte Fahrgeschwindigkeit der ESP LB:
Level 1 (i.O.)
Level 2 (partiell i.O.)
Level 3 (Rückfallebene 0) 
Level 4 (Rückfallebene 1)
Level 5 (Rückfallebene 2)
Level 6 (Nicht bedatet)
Level 7 (Init)
Level 8 (Fehler)";

CM_ SG_ 2527679824 EFP_WarnungAero "Signal steuert die Warnmeldung der Überwachungsfunktion zur aktiven Aerodynamik";
CM_ SG_ 2527679824 EFP_WarnungBauteilschutz "Signal steuert die Warnmeldungen der Bauteilschutzfunktion Fahrwerk";
CM_ SG_ 2527679824 PTLM_vLimit "Geschwindigkeitssignal für die dynamische Geschwindigkeitsanzeige der PTLM Warnmeldungen";
CM_ SG_ 2527679824 PTLM_Warnung "Steuert die Anzeige des PTLM Icon Top Speed Mode";
CM_ SG_ 2527679824 PTLM_Warnung_2 "Steuert die Anzeige der PTLM Warnmeldungen und Hinweismeldungen";

CM_ SG_ 705 DR_Warnung "Signal zur Ansteuerung von Dämpferregler-Warnungen im Kombiinstrument.";
CM_ SG_ 705 eABC_Texte "Signal zur Ansteuerung von Fahrerhinweisen im Kombi seitens eABC.";
CM_ SG_ 705 eABC_Warnung_Prio1 "Signal zur Ansteuerung von Prio1 Warnmeldungein im Kombi seitens eABC.";
CM_ SG_ 705 eABC_Warnung_Prio2 "Signal zur Ansteuerung von Prio2 Warnmeldungein im Kombi seitens eABC.";
CM_ SG_ 705 eAWS_Warnmeldung_Prio1 "Signal zur Ansteuerung der Prio1 Warnmeldung für das eAWS im Kombi ";
CM_ SG_ 705 eAWS_Warnmeldung_Prio2 "Signal zur Ansteuerung der Prio2 Warnmeldung für das eAWS im Kombi";
CM_ SG_ 705 EFP_Status_Taster_Fahrwerk "Status des EFP PAG Fahrwerkmodus";
CM_ SG_ 705 EFP_Status_Taster_Lift "Status des EFP Liftmodus";
CM_ SG_ 705 EFP_Verbau_DR "Verbauinfo Dämpferfunktion im EFP";
CM_ SG_ 705 EFP_Verbau_eABC "Verbauinfo eABC";
CM_ SG_ 705 EFP_Verbau_eAllrad "Verbauinfo eAllrad-Funktion im EFP";
CM_ SG_ 705 EFP_Verbau_eAWS "Verbauinfo eAWS";
CM_ SG_ 705 EFP_Verbau_LF "Verbauinfo Luftfederfunktion im EFP";
CM_ SG_ 705 EFP_Warnung_Naesse "Signal zur Ansteuerung von Naesse-Erkennung-Warnungen im Kombiinstrument";
CM_ SG_ 705 EFP_Warnung_Naesse_verf "Signal zur Ansteuerung von Fahrerhinweisen im Kombi";
CM_ SG_ 705 Fahrwerk_Anzeige_01_CRC "Für MLB:
'Berechnung siehe Lastenheft 'Kommunikationsabsicherung für FlexRay und CAN''

Ab MQB und MLBevo:
'Berechnung siehe Lastenheft 'End-to-End Kommunikationsabsicherung''

Endwerte siehe Begleitdokument 'S-PDU Kennungsfolgen'";
CM_ SG_ 705 FDR_Warnung_ALR "Warnmeldungen der Allradverteilung";
CM_ SG_ 705 FDR_Warnung_TV "Signal zur Ansteuerung von Warnungen im Kombi";
CM_ SG_ 705 LF_Texte "Signal zur Ansteuerung von Fahrerhinweisen im Kombi";
CM_ SG_ 705 LF_Texte_2 "Signal zur Ansteuerung von Fahrerhinweisen im Kombi";
CM_ SG_ 705 LF_Warnung_Prio1 "Signal zur Ansteuerung von Prio1-Warnungen im Kombi";
CM_ SG_ 705 LF_Warnung_Prio1_02 "Signal zur Ansteuerung von Prio1-Warnungen seitens Niveau im Kombi";
CM_ SG_ 705 LF_Warnung_Prio2 "Signal zur Ansteuerung von Prio2-Warnungen im Kombi";
CM_ SG_ 705 NR_LED_Ladelevel "Statusrückmeldung der eingestelten Fahrzeughöhe Ladelevel";
CM_ SG_ 705 NR_LED_Offroadlevel "Statusrückmeldung der eingestelten Fahrzeughöhe Offroadlevel";
CM_ SG_ 705 NR_LED_Strassenlevel "Statusrückmeldung der eingestelten Fahrzeughöhe Strassenlevel";
CM_ SG_ 705 NR_LED_Sync "Statusrückmeldung der Synchronität zwischen Luftfedersystem und Fahrprofilauswahl";
CM_ SG_ 705 NR_LED_XtraLevel "Statusrückmeldung der eingestelten Fahrzeughöhe XtraLevel";
BA_DEF_REL_ BU_SG_REL_  "GenSigTimeoutTime" INT 0 65535;
BA_DEF_ BO_  "DiagRequest" ENUM "No", "Yes";
BA_DEF_ BO_  "DiagResponse" ENUM "No", "Yes";
BA_DEF_ BO_  "DiagState" ENUM "No", "Yes";
BA_DEF_ BO_  "GenMsgChkConstant" HEX 0 4095;
BA_DEF_ BO_  "GenMsgCycleTime" INT 0 65535;
BA_DEF_ BO_  "GenMsgCycleTimeFast" INT 0 65535;
BA_DEF_ BO_  "GenMsgDelayTime" INT 0 100000;
BA_DEF_ BO_  "GenMsgILSupport" ENUM "No", "Yes";
BA_DEF_ BO_  "GenMsgNrOfRepetition" INT 0 100;
BA_DEF_ BO_  "GenMsgPDUConstants" STRING;
BA_DEF_ BO_  "GenMsgSendType" ENUM "Cyclic", "not_used", "not_used", "not_used", "not_used", "not_used", "not_used", "IfActive", "NoMsgSendType";
BA_DEF_ BO_  "GenMsgStartDelayTime" INT 0 100000;
BA_DEF_ BO_  "NmMessage" ENUM "No", "Yes";
BA_DEF_ BO_  "NmhMessage" ENUM "No", "Yes";
BA_DEF_ BO_  "MsgType" ENUM "Application", "NM ", "NMH", "TP2.0", "ISO-TP ", "BAP", "EID", "KS", "XCP_PRE_CONFIGURED", "XCP_RUNTIME_CONFIGURED";
BA_DEF_ BO_  "VAGTP20_API" HEX 0 255;
BA_DEF_ BO_  "VAGTP20_DynConnection" ENUM "No", "Yes";
BA_DEF_ BO_  "VAGTP20_DynSetup" ENUM "No", "Yes";
BA_DEF_ BO_  "VAGTP20_StatConnection" ENUM "No", "Yes";
BA_DEF_ SG_  "GenSigActiveRepetitions" INT -2147483648 2147483647;
BA_DEF_ SG_  "GenSigInactiveValue" INT -2147483648 2147483647;
BA_DEF_ SG_  "GenSigSendType" ENUM "Cyclic", "OnWrite", "OnWriteWithRepetition", "OnChange", "OnChangeWithRepetition", "IfActive", "IfActiveWithRepetition", "NoSigSendType", "OnChangeAndIfActive", "OnChangeAndIfActiveWithRepetition";
BA_DEF_ SG_  "GenSigStartValue" INT -2147483648 2147483647;
BA_DEF_ SG_  "NWM-WakeupAllowed" ENUM "No", "Yes";
BA_DEF_ SG_  "GenSigFuncType" ENUM "NoFunction", "MsgCounter", "CRC-8", "XOR", "XOR-2", "DatedBit", "SW-Kl15", "CHK", "Constant", "Protocol", "CRC-8-SAE_J1850", "CRC-32", "DataLength", "DataID", "MsgCounter16", "SOK-Signatur", "Cluster";
BA_DEF_ SG_  "GenSigSwitchedByIgnition" ENUM "No", "Yes";
BA_DEF_ SG_  "Fehlerwert" HEX 0 2147483647;
BA_DEF_ SG_  "GenSigMissingSourceValue" HEX 0 2147483647;
BA_DEF_DEF_REL_  "GenSigTimeoutTime" 0;
BA_DEF_DEF_  "DiagRequest" "No";
BA_DEF_DEF_  "DiagResponse" "No";
BA_DEF_DEF_  "DiagState" "No";
BA_DEF_DEF_  "GenMsgChkConstant" 0;
BA_DEF_DEF_  "GenMsgCycleTime" 0;
BA_DEF_DEF_  "GenMsgCycleTimeFast" 0;
BA_DEF_DEF_  "GenMsgDelayTime" 0;
BA_DEF_DEF_  "GenMsgILSupport" "No";
BA_DEF_DEF_  "GenMsgNrOfRepetition" 0;
BA_DEF_DEF_  "GenMsgPDUConstants" "";
BA_DEF_DEF_  "GenMsgSendType" "NoMsgSendType";
BA_DEF_DEF_  "GenMsgStartDelayTime" 0;
BA_DEF_DEF_  "NmMessage" "No";
BA_DEF_DEF_  "NmhMessage" "No";
BA_DEF_DEF_  "MsgType" "Application";
BA_DEF_DEF_  "VAGTP20_API" 0;
BA_DEF_DEF_  "VAGTP20_DynConnection" "No";
BA_DEF_DEF_  "VAGTP20_DynSetup" "No";
BA_DEF_DEF_  "VAGTP20_StatConnection" "No";
BA_DEF_DEF_  "GenSigActiveRepetitions" 0;
BA_DEF_DEF_  "GenSigInactiveValue" 0;
BA_DEF_DEF_  "GenSigSendType" "NoSigSendType";
BA_DEF_DEF_  "GenSigStartValue" 0;
BA_DEF_DEF_  "NWM-WakeupAllowed" "No";
BA_DEF_DEF_  "GenSigFuncType" "NoFunction";
BA_DEF_DEF_  "GenSigSwitchedByIgnition" "Yes";
BA_DEF_DEF_  "Fehlerwert" 0;
BA_DEF_DEF_  "GenSigMissingSourceValue" 0;
BA_ "GenMsgCycleTime" BO_ 1520 200;
BA_ "GenMsgDelayTime" BO_ 1520 50;
BA_ "GenMsgILSupport" BO_ 1520 1;
BA_ "GenMsgSendType" BO_ 1520 0;
BA_ "GenMsgCycleTime" BO_ 2527679773 1000;
BA_ "GenMsgCycleTimeFast" BO_ 2527679773 100;
BA_ "GenMsgDelayTime" BO_ 2527679773 50;
BA_ "GenMsgILSupport" BO_ 2527679773 1;
BA_ "GenMsgNrOfRepetition" BO_ 2527679773 5;
BA_ "GenMsgSendType" BO_ 2527679773 0;
BA_ "GenMsgCycleTime" BO_ 2527679772 1000;
BA_ "GenMsgCycleTimeFast" BO_ 2527679772 100;
BA_ "GenMsgDelayTime" BO_ 2527679772 50;
BA_ "GenMsgILSupport" BO_ 2527679772 1;
BA_ "GenMsgNrOfRepetition" BO_ 2527679772 5;
BA_ "GenMsgSendType" BO_ 2527679772 0;
BA_ "GenMsgCycleTime" BO_ 496 50;
BA_ "GenMsgDelayTime" BO_ 496 20;
BA_ "GenMsgILSupport" BO_ 496 1;
BA_ "GenMsgPDUConstants" BO_ 496 "0x2f,0x3c,0x22,0x60,0x18,0xeb,0x63,0x76,0xc5,0x91,0x0f,0x27,0x34,0x04,0x7f,0x02";
BA_ "GenMsgSendType" BO_ 496 0;
BA_ "GenMsgCycleTime" BO_ 2527679980 500;
BA_ "GenMsgDelayTime" BO_ 2527679980 50;
BA_ "GenMsgILSupport" BO_ 2527679980 1;
BA_ "GenMsgSendType" BO_ 2527679980 0;
BA_ "GenMsgStartDelayTime" BO_ 2527679980 50;
BA_ "GenMsgCycleTime" BO_ 996 1000;
BA_ "GenMsgDelayTime" BO_ 996 50;
BA_ "GenMsgILSupport" BO_ 996 1;
BA_ "GenMsgSendType" BO_ 996 0;
BA_ "GenMsgStartDelayTime" BO_ 996 80;
BA_ "GenMsgCycleTime" BO_ 1603 1000;
BA_ "GenMsgDelayTime" BO_ 1603 100;
BA_ "GenMsgILSupport" BO_ 1603 1;
BA_ "GenMsgSendType" BO_ 1603 0;
BA_ "GenMsgCycleTime" BO_ 1622 1000;
BA_ "GenMsgCycleTimeFast" BO_ 1622 50;
BA_ "GenMsgDelayTime" BO_ 1622 50;
BA_ "GenMsgILSupport" BO_ 1622 1;
BA_ "GenMsgPDUConstants" BO_ 1622 "0xab,0x2f,0xd3,0x39,0x6f,0x37,0xfa,0x59,0xa4,0x70,0xce,0x11,0x54,0x82,0x62,0x56";
BA_ "GenMsgSendType" BO_ 1622 0;
BA_ "GenMsgCycleTime" BO_ 2589283649 960;
BA_ "GenMsgILSupport" BO_ 2589283649 1;
BA_ "GenMsgPDUConstants" BO_ 2589283649 "0x3e,0xb4,0x25,0xc1,0x31,0x1f,0xf1,0xd7,0xb1,0xbe,0xcc,0xe0,0x0f,0x46,0x51,0xb2";
BA_ "GenMsgSendType" BO_ 2589283649 0;
BA_ "GenMsgChkConstant" BO_ 260 5;
BA_ "GenMsgCycleTime" BO_ 260 500;
BA_ "GenMsgDelayTime" BO_ 260 40;
BA_ "GenMsgILSupport" BO_ 260 1;
BA_ "GenMsgPDUConstants" BO_ 260 "0x05,0x05,0x05,0x05,0x05,0x05,0x05,0x05,0x05,0x05,0x05,0x05,0x05,0x05,0x05,0x05";
BA_ "GenMsgSendType" BO_ 260 0;
BA_ "GenMsgCycleTime" BO_ 781 200;
BA_ "GenMsgDelayTime" BO_ 781 20;
BA_ "GenMsgILSupport" BO_ 781 1;
BA_ "GenMsgSendType" BO_ 781 0;
BA_ "GenMsgCycleTime" BO_ 503 200;
BA_ "GenMsgDelayTime" BO_ 503 20;
BA_ "GenMsgILSupport" BO_ 503 1;
BA_ "GenMsgPDUConstants" BO_ 503 "0xe7,0x1f,0xa2,0xc2,0x76,0x25,0x1a,0x30,0xb7,0xc8,0xe8,0xe9,0x15,0x28,0x08,0x75";
BA_ "GenMsgSendType" BO_ 503 0;
BA_ "GenMsgChkConstant" BO_ 262 7;
BA_ "GenMsgCycleTime" BO_ 262 200;
BA_ "GenMsgDelayTime" BO_ 262 20;
BA_ "GenMsgILSupport" BO_ 262 1;
BA_ "GenMsgPDUConstants" BO_ 262 "0x07,0x07,0x07,0x07,0x07,0x07,0x07,0x07,0x07,0x07,0x07,0x07,0x07,0x07,0x07,0x07";
BA_ "GenMsgSendType" BO_ 262 0;
BA_ "GenMsgCycleTime" BO_ 1629 160;
BA_ "GenMsgILSupport" BO_ 1629 1;
BA_ "GenMsgPDUConstants" BO_ 1629 "0xac,0xb3,0xab,0xeb,0x7a,0xe1,0x3b,0xf7,0x73,0xba,0x7c,0x9e,0x06,0x5f,0x02,0xd9";
BA_ "GenMsgSendType" BO_ 1629 0;
BA_ "GenMsgCycleTime" BO_ 253 100;
BA_ "GenMsgILSupport" BO_ 253 1;
BA_ "GenMsgPDUConstants" BO_ 253 "0xb4,0xef,0xf8,0x49,0x1e,0xe5,0xc2,0xc0,0x97,0x19,0x3c,0xc9,0xf1,0x98,0xd6,0x61";
BA_ "GenMsgSendType" BO_ 253 0;
BA_ "GenMsgCycleTime" BO_ 1470 320;
BA_ "GenMsgILSupport" BO_ 1470 1;
BA_ "GenMsgPDUConstants" BO_ 1470 "0xc9,0x21,0x6f,0x63,0xd2,0x42,0x6a,0x77,0x4a,0x3d,0xb0,0x62,0x9f,0x38,0xcd,0x5c";
BA_ "GenMsgSendType" BO_ 1470 0;
BA_ "GenMsgCycleTime" BO_ 795 40;
BA_ "GenMsgILSupport" BO_ 795 1;
BA_ "GenMsgPDUConstants" BO_ 795 "0x67,0x8a,0xae,0x22,0x4d,0xd0,0x51,0x80,0x5c,0xb9,0xce,0x1e,0xdf,0x02,0x2d,0xd4";
BA_ "GenMsgSendType" BO_ 795 0;
BA_ "GenMsgCycleTime" BO_ 508 200;
BA_ "GenMsgDelayTime" BO_ 508 20;
BA_ "GenMsgILSupport" BO_ 508 1;
BA_ "GenMsgPDUConstants" BO_ 508 "0x01,0x10,0x05,0xde,0xe0,0xdc,0x34,0xc4,0x8a,0xb1,0x6d,0x7b,0x62,0xef,0x1f,0x95";
BA_ "GenMsgSendType" BO_ 508 0;
BA_ "GenMsgCycleTime" BO_ 2589283470 960;
BA_ "GenMsgILSupport" BO_ 2589283470 1;
BA_ "GenMsgSendType" BO_ 2589283470 0;
BA_ "GenMsgCycleTime" BO_ 2527679662 160;
BA_ "GenMsgILSupport" BO_ 2527679662 1;
BA_ "GenMsgSendType" BO_ 2527679662 0;
BA_ "GenMsgCycleTime" BO_ 600 400;
BA_ "GenMsgDelayTime" BO_ 600 40;
BA_ "GenMsgILSupport" BO_ 600 1;
BA_ "GenMsgPDUConstants" BO_ 600 "0xe0,0x57,0x49,0xc3,0x18,0xac,0xa6,0x0b,0x5c,0xc1,0x84,0x7b,0x04,0x98,0x73,0x20";
BA_ "GenMsgSendType" BO_ 600 0;
BA_ "GenMsgCycleTime" BO_ 303 20;
BA_ "GenMsgILSupport" BO_ 303 1;
BA_ "GenMsgSendType" BO_ 303 0;
BA_ "GenMsgCycleTime" BO_ 2527679824 320;
BA_ "GenMsgILSupport" BO_ 2527679824 1;
BA_ "GenMsgPDUConstants" BO_ 2527679824 "0x78,0x2d,0x4d,0x4e,0x99,0x75,0x70,0xa3,0xb7,0xec,0x96,0x1f,0x8e,0x06,0xa8,0x0f";
BA_ "GenMsgSendType" BO_ 2527679824 0;
BA_ "GenMsgCycleTime" BO_ 705 80;
BA_ "GenMsgILSupport" BO_ 705 1;
BA_ "GenMsgPDUConstants" BO_ 705 "0x96,0x12,0x1e,0xcd,0x2f,0x45,0xec,0xcb,0xd1,0x39,0x04,0x7c,0xb7,0x29,0x37,0x47";
BA_ "GenMsgSendType" BO_ 705 0;
BA_ "GenSigSendType" SG_ 1520 BCM1_Stellgroesse_Kl_58s 3;
BA_ "GenSigStartValue" SG_ 1520 BCM1_Stellgroesse_Kl_58s 126;
BA_ "GenSigSwitchedByIgnition" SG_ 1520 BCM1_Stellgroesse_Kl_58s 0;
BA_ "Fehlerwert" SG_ 1520 BCM1_Stellgroesse_Kl_58s 127;
BA_ "GenSigSendType" SG_ 1520 DI_Display_Nachtdesign 3;
BA_ "GenSigSwitchedByIgnition" SG_ 1520 DI_Display_Nachtdesign 0;
BA_ "GenSigSendType" SG_ 1520 DI_Fotosensor 3;
BA_ "GenSigSwitchedByIgnition" SG_ 1520 DI_Fotosensor 0;
BA_ "GenSigSendType" SG_ 1520 DI_KL_58xd 3;
BA_ "GenSigStartValue" SG_ 1520 DI_KL_58xd 254;
BA_ "GenSigSwitchedByIgnition" SG_ 1520 DI_KL_58xd 0;
BA_ "Fehlerwert" SG_ 1520 DI_KL_58xd 255;
BA_ "GenSigSendType" SG_ 1520 DI_KL_58xs 3;
BA_ "GenSigStartValue" SG_ 1520 DI_KL_58xs 126;
BA_ "GenSigSwitchedByIgnition" SG_ 1520 DI_KL_58xs 0;
BA_ "Fehlerwert" SG_ 1520 DI_KL_58xs 127;
BA_ "GenSigSendType" SG_ 1520 DI_KL_58xt 3;
BA_ "GenSigStartValue" SG_ 1520 DI_KL_58xt 126;
BA_ "GenSigSwitchedByIgnition" SG_ 1520 DI_KL_58xt 0;
BA_ "Fehlerwert" SG_ 1520 DI_KL_58xt 127;
BA_ "GenSigSendType" SG_ 2527679773 DLM_BFS_DoorStatus 3;
BA_ "GenSigSwitchedByIgnition" SG_ 2527679773 DLM_BFS_DoorStatus 0;
BA_ "Fehlerwert" SG_ 2527679773 DLM_BFS_DoorStatus 7;
BA_ "GenSigSendType" SG_ 2527679773 DLM_BFS_GenericFail 0;
BA_ "GenSigSwitchedByIgnition" SG_ 2527679773 DLM_BFS_GenericFail 0;
BA_ "GenSigSendType" SG_ 2527679773 DLM_BFS_HeartbeatCnt 0;
BA_ "GenSigSwitchedByIgnition" SG_ 2527679773 DLM_BFS_HeartbeatCnt 0;
BA_ "GenSigSendType" SG_ 2527679773 DLM_BFS_LatchStatusFeedbac 3;
BA_ "GenSigSwitchedByIgnition" SG_ 2527679773 DLM_BFS_LatchStatusFeedbac 0;
BA_ "Fehlerwert" SG_ 2527679773 DLM_BFS_LatchStatusFeedbac 7;
BA_ "GenSigActiveRepetitions" SG_ 2527679773 DLM_BFS_ProductionMode 5;
BA_ "GenSigSendType" SG_ 2527679773 DLM_BFS_ProductionMode 4;
BA_ "GenSigSwitchedByIgnition" SG_ 2527679773 DLM_BFS_ProductionMode 0;
BA_ "GenSigSendType" SG_ 2527679773 DLM_BFS_SuperCapStatus 0;
BA_ "GenSigSwitchedByIgnition" SG_ 2527679773 DLM_BFS_SuperCapStatus 0;
BA_ "Fehlerwert" SG_ 2527679773 DLM_BFS_SuperCapStatus 3;
BA_ "GenSigActiveRepetitions" SG_ 2527679773 DLM_BFS_SwitchRequest 5;
BA_ "GenSigSendType" SG_ 2527679773 DLM_BFS_SwitchRequest 4;
BA_ "GenSigSwitchedByIgnition" SG_ 2527679773 DLM_BFS_SwitchRequest 0;
BA_ "Fehlerwert" SG_ 2527679773 DLM_BFS_SwitchRequest 7;
BA_ "GenSigSendType" SG_ 2527679773 DLM_BFS_SystemError 0;
BA_ "GenSigSwitchedByIgnition" SG_ 2527679773 DLM_BFS_SystemError 0;
BA_ "Fehlerwert" SG_ 2527679773 DLM_BFS_SystemError 7;
BA_ "GenSigSendType" SG_ 2527679773 DLM_BFS_WDSMActuationsBFS 3;
BA_ "GenSigStartValue" SG_ 2527679773 DLM_BFS_WDSMActuationsBFS 511;
BA_ "GenSigSwitchedByIgnition" SG_ 2527679773 DLM_BFS_WDSMActuationsBFS 0;
BA_ "GenSigSendType" SG_ 2527679773 DLM_BFS_WDSMActuationsResetTrig 3;
BA_ "GenSigSwitchedByIgnition" SG_ 2527679773 DLM_BFS_WDSMActuationsResetTrig 0;
BA_ "GenSigSendType" SG_ 2527679773 DLM_BFS_WDSMStatus 0;
BA_ "GenSigSwitchedByIgnition" SG_ 2527679773 DLM_BFS_WDSMStatus 0;
BA_ "Fehlerwert" SG_ 2527679773 DLM_BFS_WDSMStatus 3;
BA_ "GenSigSendType" SG_ 2527679773 DLM_BFS_WDSMTrigger 0;
BA_ "GenSigSwitchedByIgnition" SG_ 2527679773 DLM_BFS_WDSMTrigger 0;
BA_ "GenSigSendType" SG_ 2527679772 DLM_FS_DoorStatus 3;
BA_ "GenSigSwitchedByIgnition" SG_ 2527679772 DLM_FS_DoorStatus 0;
BA_ "Fehlerwert" SG_ 2527679772 DLM_FS_DoorStatus 7;
BA_ "GenSigSendType" SG_ 2527679772 DLM_FS_GenericFailure 0;
BA_ "GenSigSwitchedByIgnition" SG_ 2527679772 DLM_FS_GenericFailure 0;
BA_ "GenSigSendType" SG_ 2527679772 DLM_FS_LatchStatusFeedback 3;
BA_ "GenSigSwitchedByIgnition" SG_ 2527679772 DLM_FS_LatchStatusFeedback 0;
BA_ "Fehlerwert" SG_ 2527679772 DLM_FS_LatchStatusFeedback 7;
BA_ "GenSigActiveRepetitions" SG_ 2527679772 DLM_FS_ProductionMode 5;
BA_ "GenSigSendType" SG_ 2527679772 DLM_FS_ProductionMode 4;
BA_ "GenSigSwitchedByIgnition" SG_ 2527679772 DLM_FS_ProductionMode 0;
BA_ "GenSigSendType" SG_ 2527679772 DLM_FS_SuperCapStatus 0;
BA_ "GenSigSwitchedByIgnition" SG_ 2527679772 DLM_FS_SuperCapStatus 0;
BA_ "Fehlerwert" SG_ 2527679772 DLM_FS_SuperCapStatus 3;
BA_ "GenSigActiveRepetitions" SG_ 2527679772 DLM_FS_SwitchRequest 5;
BA_ "GenSigSendType" SG_ 2527679772 DLM_FS_SwitchRequest 4;
BA_ "GenSigSwitchedByIgnition" SG_ 2527679772 DLM_FS_SwitchRequest 0;
BA_ "Fehlerwert" SG_ 2527679772 DLM_FS_SwitchRequest 7;
BA_ "GenSigSendType" SG_ 2527679772 DLM_FS_SystemError 0;
BA_ "GenSigSwitchedByIgnition" SG_ 2527679772 DLM_FS_SystemError 0;
BA_ "Fehlerwert" SG_ 2527679772 DLM_FS_SystemError 7;
BA_ "GenSigSendType" SG_ 2527679772 DLM_FS_WDSMActuationsFS 3;
BA_ "GenSigStartValue" SG_ 2527679772 DLM_FS_WDSMActuationsFS 511;
BA_ "GenSigSwitchedByIgnition" SG_ 2527679772 DLM_FS_WDSMActuationsFS 0;
BA_ "GenSigSendType" SG_ 2527679772 DLM_FS_WDSMActuationsResetTrig 3;
BA_ "GenSigSwitchedByIgnition" SG_ 2527679772 DLM_FS_WDSMActuationsResetTrig 0;
BA_ "GenSigSendType" SG_ 2527679772 DLM_FS_WDSMStatus 0;
BA_ "GenSigSwitchedByIgnition" SG_ 2527679772 DLM_FS_WDSMStatus 0;
BA_ "Fehlerwert" SG_ 2527679772 DLM_FS_WDSMStatus 3;
BA_ "GenSigSendType" SG_ 2527679772 DLM_FS_WDSMTrigger 0;
BA_ "GenSigSwitchedByIgnition" SG_ 2527679772 DLM_FS_WDSMTrigger 0;
BA_ "GenSigSendType" SG_ 496 ACF_Lampe_Hands_Off 3;
BA_ "GenSigSwitchedByIgnition" SG_ 496 ACF_Lampe_Hands_Off 0;
BA_ "GenSigSendType" SG_ 496 EA_02_BZ 0;
BA_ "GenSigFuncType" SG_ 496 EA_02_BZ 1;
BA_ "GenSigSendType" SG_ 496 EA_02_CRC 0;
BA_ "GenSigFuncType" SG_ 496 EA_02_CRC 2;
BA_ "GenSigSendType" SG_ 496 EA_Blinken 3;
BA_ "GenSigSendType" SG_ 496 EA_Bremslichtblinken 3;
BA_ "GenSigSendType" SG_ 496 EA_Infotainment_Anf 3;
BA_ "GenSigSendType" SG_ 496 EA_Innenraumlicht_Anf 3;
BA_ "GenSigSendType" SG_ 496 EA_Status_HMI 3;
BA_ "GenSigSendType" SG_ 496 EA_Texte 3;
BA_ "GenSigSendType" SG_ 496 EA_Tueren_Anf 3;
BA_ "GenSigSendType" SG_ 496 STP_Primaeranz 3;
BA_ "GenSigSendType" SG_ 496 zFAS_Warnblinken 3;
BA_ "GenSigSendType" SG_ 2527679980 bCall_active 3;
BA_ "GenSigSwitchedByIgnition" SG_ 2527679980 bCall_active 0;
BA_ "GenSigSendType" SG_ 2527679980 eCall_Funktionsstatus 3;
BA_ "GenSigSwitchedByIgnition" SG_ 2527679980 eCall_Funktionsstatus 0;
BA_ "GenSigSendType" SG_ 2527679980 eCall_Funktionsstatus_02 3;
BA_ "GenSigStartValue" SG_ 2527679980 eCall_Funktionsstatus_02 7;
BA_ "GenSigSwitchedByIgnition" SG_ 2527679980 eCall_Funktionsstatus_02 0;
BA_ "GenSigSendType" SG_ 2527679980 eCall_Mute_Anf 3;
BA_ "GenSigSwitchedByIgnition" SG_ 2527679980 eCall_Mute_Anf 0;
BA_ "GenSigSendType" SG_ 2527679980 eCall_Statuslicht_Farbe1 3;
BA_ "GenSigSwitchedByIgnition" SG_ 2527679980 eCall_Statuslicht_Farbe1 0;
BA_ "GenSigSendType" SG_ 2527679980 eCall_Statuslicht_Farbe2 3;
BA_ "GenSigSwitchedByIgnition" SG_ 2527679980 eCall_Statuslicht_Farbe2 0;
BA_ "GenSigSendType" SG_ 2527679980 eCall_Subscription 3;
BA_ "GenSigSwitchedByIgnition" SG_ 2527679980 eCall_Subscription 0;
BA_ "GenSigSendType" SG_ 996 EFF_Einsparhinweis 3;
BA_ "GenSigSwitchedByIgnition" SG_ 996 EFF_Einsparhinweis 0;
BA_ "GenSigSendType" SG_ 996 EFF_Verbrauch_STH 3;
BA_ "GenSigSwitchedByIgnition" SG_ 996 EFF_Verbrauch_STH 0;
BA_ "Fehlerwert" SG_ 996 EFF_Verbrauch_STH 127;
BA_ "GenSigSendType" SG_ 996 EFF_Verbraucher_Balken 3;
BA_ "GenSigStartValue" SG_ 996 EFF_Verbraucher_Balken 510;
BA_ "GenSigSwitchedByIgnition" SG_ 996 EFF_Verbraucher_Balken 0;
BA_ "Fehlerwert" SG_ 996 EFF_Verbraucher_Balken 511;
BA_ "GenSigSendType" SG_ 996 EFF_Verbraucher_Pos_1 3;
BA_ "GenSigSwitchedByIgnition" SG_ 996 EFF_Verbraucher_Pos_1 0;
BA_ "GenSigSendType" SG_ 996 EFF_Verbraucher_Pos_2 3;
BA_ "GenSigSwitchedByIgnition" SG_ 996 EFF_Verbraucher_Pos_2 0;
BA_ "GenSigSendType" SG_ 996 EFF_Verbraucher_Pos_3 3;
BA_ "GenSigSwitchedByIgnition" SG_ 996 EFF_Verbraucher_Pos_3 0;
BA_ "GenSigSendType" SG_ 996 MKE_FAS 3;
BA_ "GenSigSwitchedByIgnition" SG_ 996 MKE_FAS 0;
BA_ "GenSigSendType" SG_ 996 MKE_FAS_Fkt_Status 3;
BA_ "GenSigSwitchedByIgnition" SG_ 996 MKE_FAS_Fkt_Status 0;
BA_ "Fehlerwert" SG_ 996 MKE_FAS_Fkt_Status 3;
BA_ "GenSigSendType" SG_ 996 MKE_Fehlercode 3;
BA_ "GenSigSwitchedByIgnition" SG_ 996 MKE_Fehlercode 0;
BA_ "GenSigSendType" SG_ 996 MKE_Stufe 0;
BA_ "GenSigSwitchedByIgnition" SG_ 996 MKE_Stufe 0;
BA_ "GenSigSendType" SG_ 996 MKE_Texte 0;
BA_ "GenSigSwitchedByIgnition" SG_ 996 MKE_Texte 0;
BA_ "GenSigSendType" SG_ 1603 KBI_Einheit_Datum 3;
BA_ "GenSigSwitchedByIgnition" SG_ 1603 KBI_Einheit_Datum 0;
BA_ "GenSigSendType" SG_ 1603 KBI_Einheit_Druck 3;
BA_ "GenSigSwitchedByIgnition" SG_ 1603 KBI_Einheit_Druck 0;
BA_ "GenSigSendType" SG_ 1603 KBI_Einheit_Masse 3;
BA_ "GenSigSwitchedByIgnition" SG_ 1603 KBI_Einheit_Masse 0;
BA_ "GenSigSendType" SG_ 1603 KBI_Einheit_Sprache 3;
BA_ "GenSigSwitchedByIgnition" SG_ 1603 KBI_Einheit_Sprache 0;
BA_ "GenSigSendType" SG_ 1603 KBI_Einheit_Streckenanz 3;
BA_ "GenSigSwitchedByIgnition" SG_ 1603 KBI_Einheit_Streckenanz 0;
BA_ "GenSigSendType" SG_ 1603 KBI_Einheit_Temp 3;
BA_ "GenSigSwitchedByIgnition" SG_ 1603 KBI_Einheit_Temp 0;
BA_ "GenSigSendType" SG_ 1603 KBI_Einheit_Uhrzeit 3;
BA_ "GenSigSwitchedByIgnition" SG_ 1603 KBI_Einheit_Uhrzeit 0;
BA_ "GenSigSendType" SG_ 1603 KBI_Einheit_Verbrauch 3;
BA_ "GenSigSwitchedByIgnition" SG_ 1603 KBI_Einheit_Verbrauch 0;
BA_ "GenSigSendType" SG_ 1603 KBI_Einheit_Verbrauch_elektr 3;
BA_ "GenSigSwitchedByIgnition" SG_ 1603 KBI_Einheit_Verbrauch_elektr 0;
BA_ "GenSigSendType" SG_ 1603 KBI_Einheit_Verbrauch_Gas 3;
BA_ "GenSigSwitchedByIgnition" SG_ 1603 KBI_Einheit_Verbrauch_Gas 0;
BA_ "GenSigSendType" SG_ 1603 KBI_Einheit_Volumen 3;
BA_ "GenSigSwitchedByIgnition" SG_ 1603 KBI_Einheit_Volumen 0;
BA_ "GenSigSendType" SG_ 1603 KBI_MFA_v_Einheit_02 3;
BA_ "GenSigSwitchedByIgnition" SG_ 1603 KBI_MFA_v_Einheit_02 0;
BA_ "GenSigSendType" SG_ 1622 ELV_01_BZ 0;
BA_ "GenSigFuncType" SG_ 1622 ELV_01_BZ 1;
BA_ "GenSigSwitchedByIgnition" SG_ 1622 ELV_01_BZ 0;
BA_ "GenSigSendType" SG_ 1622 ELV_01_CRC 0;
BA_ "GenSigFuncType" SG_ 1622 ELV_01_CRC 2;
BA_ "GenSigSwitchedByIgnition" SG_ 1622 ELV_01_CRC 0;
BA_ "GenSigSendType" SG_ 1622 ELV_01_Sendestatus 5;
BA_ "GenSigSwitchedByIgnition" SG_ 1622 ELV_01_Sendestatus 0;
BA_ "GenSigSendType" SG_ 1622 ELV_Abbruch_Anf_Klemmenfreigabe 3;
BA_ "GenSigSwitchedByIgnition" SG_ 1622 ELV_Abbruch_Anf_Klemmenfreigabe 0;
BA_ "GenSigSendType" SG_ 1622 ELV_Anf_Klemme_15 3;
BA_ "GenSigSwitchedByIgnition" SG_ 1622 ELV_Anf_Klemme_15 0;
BA_ "GenSigSendType" SG_ 1622 ELV_Anf_Klemme_50 3;
BA_ "GenSigSwitchedByIgnition" SG_ 1622 ELV_Anf_Klemme_50 0;
BA_ "GenSigSendType" SG_ 1622 ELV_Anf_Klemme_S 3;
BA_ "GenSigSwitchedByIgnition" SG_ 1622 ELV_Anf_Klemme_S 0;
BA_ "GenSigSendType" SG_ 1622 ELV_Anlernmodus 3;
BA_ "GenSigSwitchedByIgnition" SG_ 1622 ELV_Anlernmodus 0;
BA_ "GenSigSendType" SG_ 1622 ELV_Entriegelt 3;
BA_ "GenSigSwitchedByIgnition" SG_ 1622 ELV_Entriegelt 0;
BA_ "GenSigSendType" SG_ 1622 ELV_Klemmenfreigabe 3;
BA_ "GenSigSwitchedByIgnition" SG_ 1622 ELV_Klemmenfreigabe 0;
BA_ "GenSigSendType" SG_ 1622 ELV_Lebenszustand 3;
BA_ "GenSigSwitchedByIgnition" SG_ 1622 ELV_Lebenszustand 0;
BA_ "GenSigSendType" SG_ 1622 ELV_LED_Gelb 3;
BA_ "GenSigSwitchedByIgnition" SG_ 1622 ELV_LED_Gelb 0;
BA_ "GenSigSendType" SG_ 1622 ELV_LED_Rot 3;
BA_ "GenSigSwitchedByIgnition" SG_ 1622 ELV_LED_Rot 0;
BA_ "GenSigSendType" SG_ 1622 ELV_P_verriegelt 3;
BA_ "GenSigSwitchedByIgnition" SG_ 1622 ELV_P_verriegelt 0;
BA_ "GenSigSendType" SG_ 1622 ELV_Txt_Bremse 3;
BA_ "GenSigSwitchedByIgnition" SG_ 1622 ELV_Txt_Bremse 0;
BA_ "GenSigSendType" SG_ 1622 ELV_Txt_Defekt 3;
BA_ "GenSigSwitchedByIgnition" SG_ 1622 ELV_Txt_Defekt 0;
BA_ "GenSigSendType" SG_ 1622 ELV_Txt_Kupplung 3;
BA_ "GenSigSwitchedByIgnition" SG_ 1622 ELV_Txt_Kupplung 0;
BA_ "GenSigSendType" SG_ 1622 ELV_Txt_Lkg_Bewegen 3;
BA_ "GenSigSwitchedByIgnition" SG_ 1622 ELV_Txt_Lkg_Bewegen 0;
BA_ "GenSigSendType" SG_ 1622 ELV_Txt_P_Gang 3;
BA_ "GenSigSwitchedByIgnition" SG_ 1622 ELV_Txt_P_Gang 0;
BA_ "GenSigSendType" SG_ 1622 ELV_Txt_Panikabschaltung 3;
BA_ "GenSigSwitchedByIgnition" SG_ 1622 ELV_Txt_Panikabschaltung 0;
BA_ "GenSigSendType" SG_ 1622 ELV_Txt_PN_Gang 3;
BA_ "GenSigSwitchedByIgnition" SG_ 1622 ELV_Txt_PN_Gang 0;
BA_ "GenSigSendType" SG_ 1622 ELV_Txt_Werkstatt 3;
BA_ "GenSigSwitchedByIgnition" SG_ 1622 ELV_Txt_Werkstatt 0;
BA_ "GenSigSendType" SG_ 1622 ELV_Verriegelt 3;
BA_ "GenSigSwitchedByIgnition" SG_ 1622 ELV_Verriegelt 0;
BA_ "GenSigSendType" SG_ 1622 ELV_ZAT_betaetigt 3;
BA_ "GenSigSwitchedByIgnition" SG_ 1622 ELV_ZAT_betaetigt 0;
BA_ "GenSigSendType" SG_ 2589283649 EML_02_BZ 0;
BA_ "GenSigFuncType" SG_ 2589283649 EML_02_BZ 1;
BA_ "GenSigSendType" SG_ 2589283649 EML_02_CRC 0;
BA_ "GenSigFuncType" SG_ 2589283649 EML_02_CRC 2;
BA_ "GenSigSendType" SG_ 2589283649 EML_ReifenKorrFaktorHL 0;
BA_ "GenSigStartValue" SG_ 2589283649 EML_ReifenKorrFaktorHL 510;
BA_ "Fehlerwert" SG_ 2589283649 EML_ReifenKorrFaktorHL 511;
BA_ "GenSigSendType" SG_ 2589283649 EML_ReifenKorrFaktorHR 0;
BA_ "GenSigStartValue" SG_ 2589283649 EML_ReifenKorrFaktorHR 510;
BA_ "Fehlerwert" SG_ 2589283649 EML_ReifenKorrFaktorHR 511;
BA_ "GenSigSendType" SG_ 2589283649 EML_ReifenKorrFaktorVL 0;
BA_ "GenSigStartValue" SG_ 2589283649 EML_ReifenKorrFaktorVL 510;
BA_ "Fehlerwert" SG_ 2589283649 EML_ReifenKorrFaktorVL 511;
BA_ "GenSigSendType" SG_ 2589283649 EML_ReifenKorrFaktorVR 0;
BA_ "GenSigStartValue" SG_ 2589283649 EML_ReifenKorrFaktorVR 510;
BA_ "Fehlerwert" SG_ 2589283649 EML_ReifenKorrFaktorVR 511;
BA_ "GenSigSendType" SG_ 260 EPB_01_BZ 0;
BA_ "GenSigFuncType" SG_ 260 EPB_01_BZ 1;
BA_ "GenSigSwitchedByIgnition" SG_ 260 EPB_01_BZ 0;
BA_ "GenSigSendType" SG_ 260 EPB_01_CRC 0;
BA_ "GenSigFuncType" SG_ 260 EPB_01_CRC 2;
BA_ "GenSigSwitchedByIgnition" SG_ 260 EPB_01_CRC 0;
BA_ "GenSigSendType" SG_ 260 EPB_DAA_Randbed_erf 0;
BA_ "GenSigSwitchedByIgnition" SG_ 260 EPB_DAA_Randbed_erf 0;
BA_ "GenSigSendType" SG_ 260 EPB_Fehlerstatus_02 3;
BA_ "GenSigSwitchedByIgnition" SG_ 260 EPB_Fehlerstatus_02 0;
BA_ "GenSigSendType" SG_ 260 EPB_Freig_Verzoeg_Anf 0;
BA_ "GenSigSwitchedByIgnition" SG_ 260 EPB_Freig_Verzoeg_Anf 0;
BA_ "GenSigSendType" SG_ 260 EPB_Pedalweg_Kuppl 3;
BA_ "GenSigSwitchedByIgnition" SG_ 260 EPB_Pedalweg_Kuppl 0;
BA_ "Fehlerwert" SG_ 260 EPB_Pedalweg_Kuppl 255;
BA_ "GenSigSendType" SG_ 260 EPB_QBit_Pedalweg_Kuppl 3;
BA_ "GenSigStartValue" SG_ 260 EPB_QBit_Pedalweg_Kuppl 1;
BA_ "GenSigSwitchedByIgnition" SG_ 260 EPB_QBit_Pedalweg_Kuppl 0;
BA_ "GenSigSendType" SG_ 260 EPB_QBit_Schalterpos 0;
BA_ "GenSigStartValue" SG_ 260 EPB_QBit_Schalterpos 1;
BA_ "GenSigSwitchedByIgnition" SG_ 260 EPB_QBit_Schalterpos 0;
BA_ "GenSigSendType" SG_ 260 EPB_Schalterposition 0;
BA_ "GenSigSwitchedByIgnition" SG_ 260 EPB_Schalterposition 0;
BA_ "Fehlerwert" SG_ 260 EPB_Schalterposition 3;
BA_ "GenSigSendType" SG_ 260 EPB_Spannkraft 0;
BA_ "GenSigStartValue" SG_ 260 EPB_Spannkraft 30;
BA_ "GenSigSwitchedByIgnition" SG_ 260 EPB_Spannkraft 0;
BA_ "Fehlerwert" SG_ 260 EPB_Spannkraft 31;
BA_ "GenSigSendType" SG_ 260 EPB_Status_02 3;
BA_ "GenSigStartValue" SG_ 260 EPB_Status_02 6;
BA_ "GenSigSwitchedByIgnition" SG_ 260 EPB_Status_02 0;
BA_ "GenSigSendType" SG_ 260 EPB_Verzoeg_Anf 0;
BA_ "GenSigStartValue" SG_ 260 EPB_Verzoeg_Anf 166;
BA_ "GenSigSwitchedByIgnition" SG_ 260 EPB_Verzoeg_Anf 0;
BA_ "GenSigSendType" SG_ 781 EPB_Akustik 0;
BA_ "GenSigSwitchedByIgnition" SG_ 781 EPB_Akustik 0;
BA_ "GenSigSendType" SG_ 781 EPB_Autoholdlampe 3;
BA_ "GenSigSwitchedByIgnition" SG_ 781 EPB_Autoholdlampe 0;
BA_ "GenSigSendType" SG_ 781 EPB_Bremsbelag_Warn 0;
BA_ "GenSigSwitchedByIgnition" SG_ 781 EPB_Bremsbelag_Warn 0;
BA_ "GenSigSendType" SG_ 781 EPB_Fehlerlampe_BKL 0;
BA_ "GenSigSwitchedByIgnition" SG_ 781 EPB_Fehlerlampe_BKL 0;
BA_ "GenSigSendType" SG_ 781 EPB_Fehlerlampe_Gelb 0;
BA_ "GenSigSwitchedByIgnition" SG_ 781 EPB_Fehlerlampe_Gelb 0;
BA_ "GenSigSendType" SG_ 781 EPB_Fehlermeldungen 3;
BA_ "GenSigSwitchedByIgnition" SG_ 781 EPB_Fehlermeldungen 0;
BA_ "GenSigSendType" SG_ 781 EPB_Funktionslampe 3;
BA_ "GenSigSwitchedByIgnition" SG_ 781 EPB_Funktionslampe 0;
BA_ "GenSigSendType" SG_ 781 EPB_Texte 3;
BA_ "GenSigSwitchedByIgnition" SG_ 781 EPB_Texte 0;
BA_ "GenSigSendType" SG_ 503 EPB_03_BZ 0;
BA_ "GenSigFuncType" SG_ 503 EPB_03_BZ 1;
BA_ "GenSigSwitchedByIgnition" SG_ 503 EPB_03_BZ 0;
BA_ "GenSigSendType" SG_ 503 EPB_03_CRC 0;
BA_ "GenSigFuncType" SG_ 503 EPB_03_CRC 2;
BA_ "GenSigSwitchedByIgnition" SG_ 503 EPB_03_CRC 0;
BA_ "GenSigSendType" SG_ 503 EPB_Autoholdlampe_02 3;
BA_ "GenSigSwitchedByIgnition" SG_ 503 EPB_Autoholdlampe_02 0;
BA_ "GenSigSendType" SG_ 503 EPB_Fehlermeldungen_02 3;
BA_ "GenSigSwitchedByIgnition" SG_ 503 EPB_Fehlermeldungen_02 0;
BA_ "GenSigSendType" SG_ 503 EPB_Funktionslampe_02 3;
BA_ "GenSigSwitchedByIgnition" SG_ 503 EPB_Funktionslampe_02 0;
BA_ "GenSigSendType" SG_ 503 EPB_Texte_02 3;
BA_ "GenSigSwitchedByIgnition" SG_ 503 EPB_Texte_02 0;
BA_ "GenSigSendType" SG_ 262 ECD_Fehler 0;
BA_ "GenSigSwitchedByIgnition" SG_ 262 ECD_Fehler 0;
BA_ "GenSigSendType" SG_ 262 ECD_nicht_verfuegbar 0;
BA_ "GenSigStartValue" SG_ 262 ECD_nicht_verfuegbar 1;
BA_ "GenSigSwitchedByIgnition" SG_ 262 ECD_nicht_verfuegbar 0;
BA_ "GenSigSendType" SG_ 262 ESC_Bremslicht 0;
BA_ "GenSigSwitchedByIgnition" SG_ 262 ESC_Bremslicht 0;
BA_ "GenSigSendType" SG_ 262 ESP_05_BZ 0;
BA_ "GenSigFuncType" SG_ 262 ESP_05_BZ 1;
BA_ "GenSigSwitchedByIgnition" SG_ 262 ESP_05_BZ 0;
BA_ "GenSigSendType" SG_ 262 ESP_05_CRC 0;
BA_ "GenSigFuncType" SG_ 262 ESP_05_CRC 2;
BA_ "GenSigSwitchedByIgnition" SG_ 262 ESP_05_CRC 0;
BA_ "GenSigSendType" SG_ 262 ESP_Anforderung_EPB 0;
BA_ "GenSigSwitchedByIgnition" SG_ 262 ESP_Anforderung_EPB 0;
BA_ "GenSigSendType" SG_ 262 ESP_Autohold_aktiv 0;
BA_ "GenSigSwitchedByIgnition" SG_ 262 ESP_Autohold_aktiv 0;
BA_ "GenSigSendType" SG_ 262 ESP_Autohold_Standby 0;
BA_ "GenSigSwitchedByIgnition" SG_ 262 ESP_Autohold_Standby 0;
BA_ "GenSigSendType" SG_ 262 ESP_BKV_Unterdruck 0;
BA_ "GenSigStartValue" SG_ 262 ESP_BKV_Unterdruck 254;
BA_ "GenSigSwitchedByIgnition" SG_ 262 ESP_BKV_Unterdruck 0;
BA_ "Fehlerwert" SG_ 262 ESP_BKV_Unterdruck 255;
BA_ "GenSigSendType" SG_ 262 ESP_Bremsdruck 0;
BA_ "GenSigStartValue" SG_ 262 ESP_Bremsdruck 100;
BA_ "GenSigSwitchedByIgnition" SG_ 262 ESP_Bremsdruck 0;
BA_ "Fehlerwert" SG_ 262 ESP_Bremsdruck 1023;
BA_ "GenSigSendType" SG_ 262 ESP_Eingr_HL 0;
BA_ "GenSigSwitchedByIgnition" SG_ 262 ESP_Eingr_HL 0;
BA_ "GenSigSendType" SG_ 262 ESP_Eingr_HR 0;
BA_ "GenSigSwitchedByIgnition" SG_ 262 ESP_Eingr_HR 0;
BA_ "GenSigSendType" SG_ 262 ESP_Eingr_VL 0;
BA_ "GenSigSwitchedByIgnition" SG_ 262 ESP_Eingr_VL 0;
BA_ "GenSigSendType" SG_ 262 ESP_Eingr_VR 0;
BA_ "GenSigSwitchedByIgnition" SG_ 262 ESP_Eingr_VR 0;
BA_ "GenSigSendType" SG_ 262 ESP_Fahrer_bremst 0;
BA_ "GenSigSwitchedByIgnition" SG_ 262 ESP_Fahrer_bremst 0;
BA_ "GenSigSendType" SG_ 262 ESP_FStatus_Anfahrhilfe 0;
BA_ "GenSigSwitchedByIgnition" SG_ 262 ESP_FStatus_Anfahrhilfe 0;
BA_ "Fehlerwert" SG_ 262 ESP_FStatus_Anfahrhilfe 1;
BA_ "GenSigSendType" SG_ 262 ESP_HBA_aktiv 0;
BA_ "GenSigSwitchedByIgnition" SG_ 262 ESP_HBA_aktiv 0;
BA_ "GenSigSendType" SG_ 262 ESP_HDC_aktiv 0;
BA_ "GenSigSwitchedByIgnition" SG_ 262 ESP_HDC_aktiv 0;
BA_ "GenSigSendType" SG_ 262 ESP_HDC_Standby 3;
BA_ "GenSigSwitchedByIgnition" SG_ 262 ESP_HDC_Standby 0;
BA_ "GenSigSendType" SG_ 262 ESP_Lenkeingriff_ADS 0;
BA_ "GenSigSwitchedByIgnition" SG_ 262 ESP_Lenkeingriff_ADS 0;
BA_ "GenSigSendType" SG_ 262 ESP_Prefill_ausgeloest 0;
BA_ "GenSigSwitchedByIgnition" SG_ 262 ESP_Prefill_ausgeloest 0;
BA_ "GenSigSendType" SG_ 262 ESP_QBit_Bremsdruck 0;
BA_ "GenSigStartValue" SG_ 262 ESP_QBit_Bremsdruck 1;
BA_ "GenSigSwitchedByIgnition" SG_ 262 ESP_QBit_Bremsdruck 0;
BA_ "GenSigSendType" SG_ 262 ESP_QBit_Fahrer_bremst 0;
BA_ "GenSigStartValue" SG_ 262 ESP_QBit_Fahrer_bremst 1;
BA_ "GenSigSwitchedByIgnition" SG_ 262 ESP_QBit_Fahrer_bremst 0;
BA_ "GenSigSendType" SG_ 262 ESP_Rueckwaertsfahrt_erkannt 0;
BA_ "GenSigSwitchedByIgnition" SG_ 262 ESP_Rueckwaertsfahrt_erkannt 0;
BA_ "GenSigSendType" SG_ 262 ESP_Schwelle_Unterdruck 0;
BA_ "GenSigSwitchedByIgnition" SG_ 262 ESP_Schwelle_Unterdruck 0;
BA_ "GenSigSendType" SG_ 262 ESP_StartStopp_Info 0;
BA_ "GenSigSwitchedByIgnition" SG_ 262 ESP_StartStopp_Info 0;
BA_ "GenSigSendType" SG_ 262 ESP_Status_Anfahrhilfe 0;
BA_ "GenSigSwitchedByIgnition" SG_ 262 ESP_Status_Anfahrhilfe 0;
BA_ "GenSigSendType" SG_ 262 ESP_Status_Bremsdruck 0;
BA_ "GenSigSwitchedByIgnition" SG_ 262 ESP_Status_Bremsdruck 0;
BA_ "GenSigSendType" SG_ 262 ESP_Status_Bremsentemp 0;
BA_ "GenSigSwitchedByIgnition" SG_ 262 ESP_Status_Bremsentemp 0;
BA_ "GenSigSendType" SG_ 262 ESP_Verz_EPB_aktiv 0;
BA_ "GenSigSwitchedByIgnition" SG_ 262 ESP_Verz_EPB_aktiv 0;
BA_ "GenSigSendType" SG_ 262 ESP_Verzoeg_EPB_verf 0;
BA_ "GenSigSwitchedByIgnition" SG_ 262 ESP_Verzoeg_EPB_verf 0;
BA_ "GenSigSendType" SG_ 1629 BR_QBit_Reifenumfang 0;
BA_ "GenSigStartValue" SG_ 1629 BR_QBit_Reifenumfang 1;
BA_ "GenSigSwitchedByIgnition" SG_ 1629 BR_QBit_Reifenumfang 0;
BA_ "GenSigSendType" SG_ 1629 BR_Reifenumfang 0;
BA_ "GenSigSwitchedByIgnition" SG_ 1629 BR_Reifenumfang 0;
BA_ "GenSigSendType" SG_ 1629 BR_Systemart 0;
BA_ "GenSigFuncType" SG_ 1629 BR_Systemart 8;
BA_ "GenSigSwitchedByIgnition" SG_ 1629 BR_Systemart 0;
BA_ "GenSigSendType" SG_ 1629 ESP_20_BZ 0;
BA_ "GenSigFuncType" SG_ 1629 ESP_20_BZ 1;
BA_ "GenSigSwitchedByIgnition" SG_ 1629 ESP_20_BZ 0;
BA_ "GenSigSendType" SG_ 1629 ESP_20_CRC 0;
BA_ "GenSigFuncType" SG_ 1629 ESP_20_CRC 2;
BA_ "GenSigSwitchedByIgnition" SG_ 1629 ESP_20_CRC 0;
BA_ "GenSigSendType" SG_ 1629 ESP_Charisma_FahrPr 0;
BA_ "GenSigSwitchedByIgnition" SG_ 1629 ESP_Charisma_FahrPr 0;
BA_ "GenSigSendType" SG_ 1629 ESP_Charisma_Status 0;
BA_ "GenSigSwitchedByIgnition" SG_ 1629 ESP_Charisma_Status 0;
BA_ "GenSigSendType" SG_ 1629 ESP_Dachrelingsensor 0;
BA_ "GenSigSwitchedByIgnition" SG_ 1629 ESP_Dachrelingsensor 0;
BA_ "Fehlerwert" SG_ 1629 ESP_Dachrelingsensor 3;
BA_ "GenSigSendType" SG_ 1629 ESP_SpannungsAnf_02 0;
BA_ "GenSigSwitchedByIgnition" SG_ 1629 ESP_SpannungsAnf_02 0;
BA_ "GenSigSendType" SG_ 1629 ESP_Stoppverbot_Anz_01 0;
BA_ "GenSigSwitchedByIgnition" SG_ 1629 ESP_Stoppverbot_Anz_01 0;
BA_ "GenSigSendType" SG_ 1629 ESP_Stoppverbot_Anz_02 0;
BA_ "GenSigSwitchedByIgnition" SG_ 1629 ESP_Stoppverbot_Anz_02 0;
BA_ "GenSigSendType" SG_ 1629 ESP_Stoppverbot_Anz_03 0;
BA_ "GenSigSwitchedByIgnition" SG_ 1629 ESP_Stoppverbot_Anz_03 0;
BA_ "GenSigSendType" SG_ 1629 ESP_Stoppverbot_Anz_04 0;
BA_ "GenSigSwitchedByIgnition" SG_ 1629 ESP_Stoppverbot_Anz_04 0;
BA_ "GenSigSendType" SG_ 1629 ESP_Stoppverbot_Anz_05 0;
BA_ "GenSigSwitchedByIgnition" SG_ 1629 ESP_Stoppverbot_Anz_05 0;
BA_ "GenSigSendType" SG_ 1629 ESP_Stoppverbot_Anz_06 0;
BA_ "GenSigSwitchedByIgnition" SG_ 1629 ESP_Stoppverbot_Anz_06 0;
BA_ "GenSigSendType" SG_ 1629 ESP_Stoppverbot_Anz_07 0;
BA_ "GenSigSwitchedByIgnition" SG_ 1629 ESP_Stoppverbot_Anz_07 0;
BA_ "GenSigSendType" SG_ 1629 ESP_Stoppverbot_Anz_08 0;
BA_ "GenSigSwitchedByIgnition" SG_ 1629 ESP_Stoppverbot_Anz_08 0;
BA_ "GenSigSendType" SG_ 1629 ESP_Stoppverbot_Anz_Std 0;
BA_ "GenSigSwitchedByIgnition" SG_ 1629 ESP_Stoppverbot_Anz_Std 0;
BA_ "GenSigSendType" SG_ 1629 ESP_Wiederstart_Anz_01 0;
BA_ "GenSigSwitchedByIgnition" SG_ 1629 ESP_Wiederstart_Anz_01 0;
BA_ "GenSigSendType" SG_ 1629 ESP_Wiederstart_Anz_02 0;
BA_ "GenSigSwitchedByIgnition" SG_ 1629 ESP_Wiederstart_Anz_02 0;
BA_ "GenSigSendType" SG_ 1629 ESP_Wiederstart_Anz_03 0;
BA_ "GenSigSwitchedByIgnition" SG_ 1629 ESP_Wiederstart_Anz_03 0;
BA_ "GenSigSendType" SG_ 1629 ESP_Wiederstart_Anz_04 0;
BA_ "GenSigSwitchedByIgnition" SG_ 1629 ESP_Wiederstart_Anz_04 0;
BA_ "GenSigSendType" SG_ 1629 ESP_Zaehnezahl 0;
BA_ "GenSigFuncType" SG_ 1629 ESP_Zaehnezahl 8;
BA_ "GenSigSwitchedByIgnition" SG_ 1629 ESP_Zaehnezahl 0;
BA_ "GenSigSendType" SG_ 1629 HDC_Charisma_FahrPr 0;
BA_ "GenSigSwitchedByIgnition" SG_ 1629 HDC_Charisma_FahrPr 0;
BA_ "GenSigSendType" SG_ 1629 HDC_Charisma_Status 0;
BA_ "GenSigSwitchedByIgnition" SG_ 1629 HDC_Charisma_Status 0;
BA_ "GenSigSendType" SG_ 253 ABS_Bremsung 0;
BA_ "GenSigSwitchedByIgnition" SG_ 253 ABS_Bremsung 0;
BA_ "GenSigSendType" SG_ 253 ASR_Anf 0;
BA_ "GenSigSwitchedByIgnition" SG_ 253 ASR_Anf 0;
BA_ "GenSigSendType" SG_ 253 ASR_Schalteingriff 0;
BA_ "GenSigSwitchedByIgnition" SG_ 253 ASR_Schalteingriff 0;
BA_ "GenSigSendType" SG_ 253 ASR_Tastung_passiv 0;
BA_ "GenSigSwitchedByIgnition" SG_ 253 ASR_Tastung_passiv 0;
BA_ "GenSigSendType" SG_ 253 BR_Eingriffsmoment 0;
BA_ "GenSigStartValue" SG_ 253 BR_Eingriffsmoment 1022;
BA_ "GenSigSwitchedByIgnition" SG_ 253 BR_Eingriffsmoment 0;
BA_ "Fehlerwert" SG_ 253 BR_Eingriffsmoment 1023;
BA_ "GenSigSendType" SG_ 253 EBV_Eingriff 0;
BA_ "GenSigSwitchedByIgnition" SG_ 253 EBV_Eingriff 0;
BA_ "GenSigSendType" SG_ 253 EDS_Eingriff 0;
BA_ "GenSigSwitchedByIgnition" SG_ 253 EDS_Eingriff 0;
BA_ "GenSigSendType" SG_ 253 ESC_Neutralschaltung 0;
BA_ "GenSigSwitchedByIgnition" SG_ 253 ESC_Neutralschaltung 0;
BA_ "GenSigSendType" SG_ 253 ESC_v_Signal_Qualifier_High_Low 0;
BA_ "GenSigStartValue" SG_ 253 ESC_v_Signal_Qualifier_High_Low 6;
BA_ "GenSigSwitchedByIgnition" SG_ 253 ESC_v_Signal_Qualifier_High_Low 0;
BA_ "Fehlerwert" SG_ 253 ESC_v_Signal_Qualifier_High_Low 7;
BA_ "GenSigSendType" SG_ 253 ESP_21_BZ 0;
BA_ "GenSigFuncType" SG_ 253 ESP_21_BZ 1;
BA_ "GenSigSwitchedByIgnition" SG_ 253 ESP_21_BZ 0;
BA_ "GenSigSendType" SG_ 253 ESP_21_CRC 0;
BA_ "GenSigFuncType" SG_ 253 ESP_21_CRC 2;
BA_ "GenSigSwitchedByIgnition" SG_ 253 ESP_21_CRC 0;
BA_ "GenSigSendType" SG_ 253 ESP_ASP 0;
BA_ "GenSigSwitchedByIgnition" SG_ 253 ESP_ASP 0;
BA_ "GenSigSendType" SG_ 253 ESP_Diagnose 0;
BA_ "GenSigSwitchedByIgnition" SG_ 253 ESP_Diagnose 0;
BA_ "GenSigSendType" SG_ 253 ESP_Eingriff 0;
BA_ "GenSigSwitchedByIgnition" SG_ 253 ESP_Eingriff 0;
BA_ "GenSigSendType" SG_ 253 ESP_QBit_v_Signal 0;
BA_ "GenSigStartValue" SG_ 253 ESP_QBit_v_Signal 1;
BA_ "GenSigSwitchedByIgnition" SG_ 253 ESP_QBit_v_Signal 0;
BA_ "GenSigSendType" SG_ 253 ESP_Systemstatus 0;
BA_ "GenSigSwitchedByIgnition" SG_ 253 ESP_Systemstatus 0;
BA_ "GenSigSendType" SG_ 253 ESP_Tastung_passiv 0;
BA_ "GenSigSwitchedByIgnition" SG_ 253 ESP_Tastung_passiv 0;
BA_ "GenSigSendType" SG_ 253 ESP_v_Signal 0;
BA_ "GenSigStartValue" SG_ 253 ESP_v_Signal 65534;
BA_ "GenSigSwitchedByIgnition" SG_ 253 ESP_v_Signal 0;
BA_ "Fehlerwert" SG_ 253 ESP_v_Signal 65535;
BA_ "GenSigMissingSourceValue" SG_ 253 ESP_v_Signal 65534;
BA_ "GenSigSendType" SG_ 253 ESP_Vorsteuerung 0;
BA_ "GenSigSwitchedByIgnition" SG_ 253 ESP_Vorsteuerung 0;
BA_ "GenSigSendType" SG_ 253 MSR_Anf 0;
BA_ "GenSigSwitchedByIgnition" SG_ 253 MSR_Anf 0;
BA_ "GenSigSendType" SG_ 253 MSR_verfuegbar 0;
BA_ "GenSigStartValue" SG_ 253 MSR_verfuegbar 1;
BA_ "GenSigSwitchedByIgnition" SG_ 253 MSR_verfuegbar 0;
BA_ "GenSigSendType" SG_ 253 OBD_QBit_Schlechtweg 0;
BA_ "GenSigStartValue" SG_ 253 OBD_QBit_Schlechtweg 1;
BA_ "GenSigSwitchedByIgnition" SG_ 253 OBD_QBit_Schlechtweg 0;
BA_ "GenSigSendType" SG_ 253 OBD_Schlechtweg 0;
BA_ "GenSigSwitchedByIgnition" SG_ 253 OBD_Schlechtweg 0;
BA_ "GenSigSendType" SG_ 1470 BR_QBit_Reifenumfang_sekundaer 0;
BA_ "GenSigStartValue" SG_ 1470 BR_QBit_Reifenumfang_sekundaer 1;
BA_ "GenSigSwitchedByIgnition" SG_ 1470 BR_QBit_Reifenumfang_sekundaer 0;
BA_ "GenSigSendType" SG_ 1470 BR_Reifenumfang_sekundaer 0;
BA_ "GenSigSwitchedByIgnition" SG_ 1470 BR_Reifenumfang_sekundaer 0;
BA_ "GenSigSendType" SG_ 1470 ESP_23_BZ 0;
BA_ "GenSigFuncType" SG_ 1470 ESP_23_BZ 1;
BA_ "GenSigSwitchedByIgnition" SG_ 1470 ESP_23_BZ 0;
BA_ "GenSigSendType" SG_ 1470 ESP_23_CRC 0;
BA_ "GenSigFuncType" SG_ 1470 ESP_23_CRC 2;
BA_ "GenSigSwitchedByIgnition" SG_ 1470 ESP_23_CRC 0;
BA_ "GenSigSendType" SG_ 1470 ESP_Gierrate_Offset_2 0;
BA_ "GenSigStartValue" SG_ 1470 ESP_Gierrate_Offset_2 2046;
BA_ "GenSigSwitchedByIgnition" SG_ 1470 ESP_Gierrate_Offset_2 0;
BA_ "Fehlerwert" SG_ 1470 ESP_Gierrate_Offset_2 2047;
BA_ "GenSigSendType" SG_ 1470 ESP_Laengsbeschleunigung_Offset 0;
BA_ "GenSigStartValue" SG_ 1470 ESP_Laengsbeschleunigung_Offset 254;
BA_ "GenSigSwitchedByIgnition" SG_ 1470 ESP_Laengsbeschleunigung_Offset 0;
BA_ "Fehlerwert" SG_ 1470 ESP_Laengsbeschleunigung_Offset 255;
BA_ "GenSigSendType" SG_ 1470 ESP_Lenkwinkel_Offset 0;
BA_ "GenSigStartValue" SG_ 1470 ESP_Lenkwinkel_Offset 510;
BA_ "GenSigSwitchedByIgnition" SG_ 1470 ESP_Lenkwinkel_Offset 0;
BA_ "Fehlerwert" SG_ 1470 ESP_Lenkwinkel_Offset 511;
BA_ "GenSigSendType" SG_ 1470 ESP_Querbeschleunigung_Offset 0;
BA_ "GenSigStartValue" SG_ 1470 ESP_Querbeschleunigung_Offset 62;
BA_ "GenSigSwitchedByIgnition" SG_ 1470 ESP_Querbeschleunigung_Offset 0;
BA_ "Fehlerwert" SG_ 1470 ESP_Querbeschleunigung_Offset 63;
BA_ "GenSigSendType" SG_ 1470 ESP_Status_Bremsentemp_Anz 0;
BA_ "GenSigSwitchedByIgnition" SG_ 1470 ESP_Status_Bremsentemp_Anz 0;
BA_ "Fehlerwert" SG_ 1470 ESP_Status_Bremsentemp_Anz 7;
BA_ "GenSigSendType" SG_ 795 ABS_Lampe 0;
BA_ "GenSigStartValue" SG_ 795 ABS_Lampe 1;
BA_ "GenSigSwitchedByIgnition" SG_ 795 ABS_Lampe 0;
BA_ "GenSigSendType" SG_ 795 BK_Lampe_02 0;
BA_ "GenSigStartValue" SG_ 795 BK_Lampe_02 1;
BA_ "GenSigSwitchedByIgnition" SG_ 795 BK_Lampe_02 0;
BA_ "GenSigSendType" SG_ 795 ESP_24_BZ 0;
BA_ "GenSigFuncType" SG_ 795 ESP_24_BZ 1;
BA_ "GenSigSwitchedByIgnition" SG_ 795 ESP_24_BZ 0;
BA_ "GenSigSendType" SG_ 795 ESP_24_CRC 0;
BA_ "GenSigFuncType" SG_ 795 ESP_24_CRC 2;
BA_ "GenSigSwitchedByIgnition" SG_ 795 ESP_24_CRC 0;
BA_ "GenSigSendType" SG_ 795 ESP_BKV_Warnung 0;
BA_ "GenSigSwitchedByIgnition" SG_ 795 ESP_BKV_Warnung 0;
BA_ "GenSigSendType" SG_ 795 ESP_Fehlerstatus_Wegimp 0;
BA_ "GenSigSwitchedByIgnition" SG_ 795 ESP_Fehlerstatus_Wegimp 0;
BA_ "GenSigSendType" SG_ 795 ESP_HDC_Geschw_Farbe 0;
BA_ "GenSigSwitchedByIgnition" SG_ 795 ESP_HDC_Geschw_Farbe 0;
BA_ "GenSigSendType" SG_ 795 ESP_HDC_Regelgeschw 0;
BA_ "GenSigStartValue" SG_ 795 ESP_HDC_Regelgeschw 126;
BA_ "GenSigSwitchedByIgnition" SG_ 795 ESP_HDC_Regelgeschw 0;
BA_ "Fehlerwert" SG_ 795 ESP_HDC_Regelgeschw 127;
BA_ "GenSigSendType" SG_ 795 ESP_Lampe 0;
BA_ "GenSigStartValue" SG_ 795 ESP_Lampe 1;
BA_ "GenSigSwitchedByIgnition" SG_ 795 ESP_Lampe 0;
BA_ "GenSigSendType" SG_ 795 ESP_m_Raddrehz 0;
BA_ "GenSigStartValue" SG_ 795 ESP_m_Raddrehz 32766;
BA_ "GenSigSwitchedByIgnition" SG_ 795 ESP_m_Raddrehz 0;
BA_ "Fehlerwert" SG_ 795 ESP_m_Raddrehz 32767;
BA_ "GenSigSendType" SG_ 795 ESP_Meldungen 0;
BA_ "GenSigSwitchedByIgnition" SG_ 795 ESP_Meldungen 0;
BA_ "GenSigSendType" SG_ 795 ESP_Off_Lampe 0;
BA_ "GenSigSwitchedByIgnition" SG_ 795 ESP_Off_Lampe 0;
BA_ "GenSigSendType" SG_ 795 ESP_QBit_Wegimp_VA 0;
BA_ "GenSigStartValue" SG_ 795 ESP_QBit_Wegimp_VA 1;
BA_ "GenSigSwitchedByIgnition" SG_ 795 ESP_QBit_Wegimp_VA 0;
BA_ "GenSigSendType" SG_ 795 ESP_Textanzeigen_03 0;
BA_ "GenSigSwitchedByIgnition" SG_ 795 ESP_Textanzeigen_03 0;
BA_ "GenSigSendType" SG_ 795 ESP_Wegimp_Ueberlauf 0;
BA_ "GenSigSwitchedByIgnition" SG_ 795 ESP_Wegimp_Ueberlauf 0;
BA_ "GenSigSendType" SG_ 795 ESP_Wegimp_VA 0;
BA_ "GenSigSwitchedByIgnition" SG_ 795 ESP_Wegimp_VA 0;
BA_ "GenSigSendType" SG_ 795 TC_Lampe 0;
BA_ "GenSigSwitchedByIgnition" SG_ 795 TC_Lampe 0;
BA_ "GenSigSendType" SG_ 508 ESC_Anforderung_Airbrake 0;
BA_ "GenSigSwitchedByIgnition" SG_ 508 ESC_Anforderung_Airbrake 0;
BA_ "GenSigSendType" SG_ 508 ESC_FBA_Meldungen 3;
BA_ "GenSigSwitchedByIgnition" SG_ 508 ESC_FBA_Meldungen 0;
BA_ "GenSigSendType" SG_ 508 ESC_MBK_Meldungen 3;
BA_ "GenSigSwitchedByIgnition" SG_ 508 ESC_MBK_Meldungen 0;
BA_ "GenSigSendType" SG_ 508 ESC_Motorstartverzoegerung 0;
BA_ "GenSigSwitchedByIgnition" SG_ 508 ESC_Motorstartverzoegerung 0;
BA_ "GenSigSendType" SG_ 508 ESP_32_BZ 0;
BA_ "GenSigFuncType" SG_ 508 ESP_32_BZ 1;
BA_ "GenSigSwitchedByIgnition" SG_ 508 ESP_32_BZ 0;
BA_ "GenSigSendType" SG_ 508 ESP_32_CRC 0;
BA_ "GenSigFuncType" SG_ 508 ESP_32_CRC 2;
BA_ "GenSigSwitchedByIgnition" SG_ 508 ESP_32_CRC 0;
BA_ "GenSigSendType" SG_ 508 ESP_Aggregataktivitaet 0;
BA_ "GenSigSwitchedByIgnition" SG_ 508 ESP_Aggregataktivitaet 0;
BA_ "GenSigSendType" SG_ 508 ESP_AVH_LED 0;
BA_ "GenSigStartValue" SG_ 508 ESP_AVH_LED 6;
BA_ "GenSigSwitchedByIgnition" SG_ 508 ESP_AVH_LED 0;
BA_ "GenSigSendType" SG_ 508 ESP_EDS_Anzeige 3;
BA_ "GenSigSwitchedByIgnition" SG_ 508 ESP_EDS_Anzeige 0;
BA_ "GenSigSendType" SG_ 508 ESP_HDC_LED 0;
BA_ "GenSigStartValue" SG_ 508 ESP_HDC_LED 6;
BA_ "GenSigSwitchedByIgnition" SG_ 508 ESP_HDC_LED 0;
BA_ "GenSigSendType" SG_ 508 ESP_HDC_Textanzeigen 3;
BA_ "GenSigSwitchedByIgnition" SG_ 508 ESP_HDC_Textanzeigen 0;
BA_ "GenSigSendType" SG_ 508 ESP_HOLD_verf 0;
BA_ "GenSigSwitchedByIgnition" SG_ 508 ESP_HOLD_verf 0;
BA_ "GenSigSendType" SG_ 508 ESP_Notbremsanzeige 0;
BA_ "GenSigSwitchedByIgnition" SG_ 508 ESP_Notbremsanzeige 0;
BA_ "GenSigSendType" SG_ 508 ESP_Off_LED 0;
BA_ "GenSigStartValue" SG_ 508 ESP_Off_LED 6;
BA_ "GenSigSwitchedByIgnition" SG_ 508 ESP_Off_LED 0;
BA_ "GenSigSendType" SG_ 508 ESP_Offroad_Lampe 0;
BA_ "GenSigSwitchedByIgnition" SG_ 508 ESP_Offroad_Lampe 0;
BA_ "GenSigSendType" SG_ 508 ESP_Rollover_Status_dyn 0;
BA_ "GenSigSwitchedByIgnition" SG_ 508 ESP_Rollover_Status_dyn 0;
BA_ "GenSigSendType" SG_ 508 ESP_Rollover_Status_stat 0;
BA_ "GenSigSwitchedByIgnition" SG_ 508 ESP_Rollover_Status_stat 0;
BA_ "GenSigSendType" SG_ 508 ESP_Status_Bremsentemp_02 0;
BA_ "GenSigSwitchedByIgnition" SG_ 508 ESP_Status_Bremsentemp_02 0;
BA_ "GenSigSendType" SG_ 508 ESP_Stillstandsflag 0;
BA_ "GenSigSwitchedByIgnition" SG_ 508 ESP_Stillstandsflag 0;
BA_ "GenSigSendType" SG_ 508 ESP_Wiederstart_Anz_Std 0;
BA_ "GenSigSwitchedByIgnition" SG_ 508 ESP_Wiederstart_Anz_Std 0;
BA_ "GenSigSendType" SG_ 508 RLE_Anzeigen 3;
BA_ "GenSigSwitchedByIgnition" SG_ 508 RLE_Anzeigen 0;
BA_ "GenSigSendType" SG_ 2589283470 ESC_Kilometer 0;
BA_ "GenSigStartValue" SG_ 2589283470 ESC_Kilometer 1048574;
BA_ "GenSigSwitchedByIgnition" SG_ 2589283470 ESC_Kilometer 0;
BA_ "Fehlerwert" SG_ 2589283470 ESC_Kilometer 1048575;
BA_ "GenSigSendType" SG_ 2589283470 ESC_Kilometer_MUX 0;
BA_ "GenSigSwitchedByIgnition" SG_ 2589283470 ESC_Kilometer_MUX 0;
BA_ "GenSigSwitchedByIgnition" SG_ 2589283470 ESC_Signatur_Kilometer_GFA_01 0;
BA_ "GenSigSwitchedByIgnition" SG_ 2589283470 ESC_Signatur_Kilometer_GFA_02 0;
BA_ "GenSigSwitchedByIgnition" SG_ 2589283470 ESC_Signatur_Kilometer_IKA_01 0;
BA_ "GenSigSwitchedByIgnition" SG_ 2589283470 ESC_Signatur_Kilometer_IKA_02 0;
BA_ "GenSigSendType" SG_ 2527679662 BRS_BFLS_Verbauzustand 0;
BA_ "GenSigSwitchedByIgnition" SG_ 2527679662 BRS_BFLS_Verbauzustand 0;
BA_ "GenSigSendType" SG_ 2527679662 BRS_Bremsfluessigkeit_Warnungen 0;
BA_ "GenSigSwitchedByIgnition" SG_ 2527679662 BRS_Bremsfluessigkeit_Warnungen 0;
BA_ "GenSigSendType" SG_ 2527679662 ESC_Anf_Bremsenkuehlung 0;
BA_ "GenSigSwitchedByIgnition" SG_ 2527679662 ESC_Anf_Bremsenkuehlung 0;
BA_ "GenSigSendType" SG_ 2527679662 ESC_Anf_LadeVorhalt 0;
BA_ "GenSigStartValue" SG_ 2527679662 ESC_Anf_LadeVorhalt 15;
BA_ "GenSigSwitchedByIgnition" SG_ 2527679662 ESC_Anf_LadeVorhalt 0;
BA_ "GenSigSendType" SG_ 2527679662 ESC_Anf_Luefternachlauf 0;
BA_ "GenSigSwitchedByIgnition" SG_ 2527679662 ESC_Anf_Luefternachlauf 0;
BA_ "GenSigSendType" SG_ 2527679662 ESC_Reku_Anzeige 0;
BA_ "GenSigSwitchedByIgnition" SG_ 2527679662 ESC_Reku_Anzeige 0;
BA_ "GenSigSendType" SG_ 2527679662 ESC_Rekueff_Bremsung 0;
BA_ "GenSigStartValue" SG_ 2527679662 ESC_Rekueff_Bremsung 126;
BA_ "Fehlerwert" SG_ 2527679662 ESC_Rekueff_Bremsung 127;
BA_ "GenSigSendType" SG_ 2527679662 ESC_Textanzeigen_SysSpez 0;
BA_ "GenSigSwitchedByIgnition" SG_ 2527679662 ESC_Textanzeigen_SysSpez 0;
BA_ "GenSigSendType" SG_ 2527679662 ESP_Off_Anf_KBI 3;
BA_ "GenSigSwitchedByIgnition" SG_ 2527679662 ESP_Off_Anf_KBI 0;
BA_ "GenSigSendType" SG_ 600 ESP_54_BZ 0;
BA_ "GenSigFuncType" SG_ 600 ESP_54_BZ 1;
BA_ "GenSigSwitchedByIgnition" SG_ 600 ESP_54_BZ 0;
BA_ "GenSigSendType" SG_ 600 ESP_54_CRC 0;
BA_ "GenSigFuncType" SG_ 600 ESP_54_CRC 2;
BA_ "GenSigSwitchedByIgnition" SG_ 600 ESP_54_CRC 0;
BA_ "GenSigSendType" SG_ 600 ESP_DriftGong 3;
BA_ "GenSigSwitchedByIgnition" SG_ 600 ESP_DriftGong 0;
BA_ "GenSigSendType" SG_ 600 ESP_DriftLevel 3;
BA_ "GenSigSendType" SG_ 600 ESP_DriftStatus 3;
BA_ "GenSigSendType" SG_ 600 ESP_DriftText 3;
BA_ "GenSigSendType" SG_ 600 ESP_Slider_Gong 3;
BA_ "GenSigSwitchedByIgnition" SG_ 600 ESP_Slider_Gong 0;
BA_ "GenSigSendType" SG_ 600 ESP_Slider_ist_01 3;
BA_ "GenSigStartValue" SG_ 600 ESP_Slider_ist_01 127;
BA_ "GenSigSendType" SG_ 600 ESP_Slider_ist_02 3;
BA_ "GenSigStartValue" SG_ 600 ESP_Slider_ist_02 127;
BA_ "GenSigSendType" SG_ 600 ESP_Slider_ist_03 3;
BA_ "GenSigStartValue" SG_ 600 ESP_Slider_ist_03 127;
BA_ "GenSigSendType" SG_ 600 ESP_Slider_Lamp 3;
BA_ "GenSigSendType" SG_ 600 ESP_Slider_Status 3;
BA_ "GenSigSendType" SG_ 600 ESP_Slider_Text 3;
BA_ "GenSigSendType" SG_ 303 ESP_Fahrbahnreibwert_dyn 0;
BA_ "GenSigStartValue" SG_ 303 ESP_Fahrbahnreibwert_dyn 62;
BA_ "Fehlerwert" SG_ 303 ESP_Fahrbahnreibwert_dyn 63;
BA_ "GenSigSendType" SG_ 303 ESP_Fahrbahnreibwert_dyn_Class 0;
BA_ "GenSigSendType" SG_ 303 ESP_Schwimmwinkel 0;
BA_ "GenSigStartValue" SG_ 303 ESP_Schwimmwinkel 4094;
BA_ "Fehlerwert" SG_ 303 ESP_Schwimmwinkel 4095;
BA_ "GenSigSendType" SG_ 303 ESP_vRef_abs 0;
BA_ "GenSigStartValue" SG_ 303 ESP_vRef_abs 4094;
BA_ "Fehlerwert" SG_ 303 ESP_vRef_abs 4095;
BA_ "GenSigSendType" SG_ 303 ESP_vRef_abs_classifier 0;
BA_ "GenSigSendType" SG_ 2527679824 EFP_WarnungAero 0;
BA_ "GenSigSwitchedByIgnition" SG_ 2527679824 EFP_WarnungAero 0;
BA_ "GenSigSendType" SG_ 2527679824 EFP_WarnungBauteilschutz 0;
BA_ "GenSigSwitchedByIgnition" SG_ 2527679824 EFP_WarnungBauteilschutz 0;
BA_ "GenSigSendType" SG_ 2527679824 Fahrwerk_14_BZ 0;
BA_ "GenSigFuncType" SG_ 2527679824 Fahrwerk_14_BZ 1;
BA_ "GenSigSwitchedByIgnition" SG_ 2527679824 Fahrwerk_14_BZ 0;
BA_ "GenSigSendType" SG_ 2527679824 Fahrwerk_14_CRC 0;
BA_ "GenSigFuncType" SG_ 2527679824 Fahrwerk_14_CRC 2;
BA_ "GenSigSwitchedByIgnition" SG_ 2527679824 Fahrwerk_14_CRC 0;
BA_ "GenSigSendType" SG_ 2527679824 PTLM_vLimit 0;
BA_ "GenSigStartValue" SG_ 2527679824 PTLM_vLimit 62;
BA_ "GenSigSwitchedByIgnition" SG_ 2527679824 PTLM_vLimit 0;
BA_ "Fehlerwert" SG_ 2527679824 PTLM_vLimit 63;
BA_ "GenSigSendType" SG_ 2527679824 PTLM_Warnung 0;
BA_ "GenSigSwitchedByIgnition" SG_ 2527679824 PTLM_Warnung 0;
BA_ "GenSigSendType" SG_ 2527679824 PTLM_Warnung_2 0;
BA_ "GenSigSwitchedByIgnition" SG_ 2527679824 PTLM_Warnung_2 0;
BA_ "GenSigSendType" SG_ 705 DR_Warnung 0;
BA_ "GenSigSendType" SG_ 705 eABC_Texte 0;
BA_ "GenSigSendType" SG_ 705 eABC_Warnung_Prio1 0;
BA_ "GenSigSendType" SG_ 705 eABC_Warnung_Prio2 0;
BA_ "GenSigSendType" SG_ 705 eAWS_Warnmeldung_Prio1 0;
BA_ "GenSigSendType" SG_ 705 eAWS_Warnmeldung_Prio2 0;
BA_ "GenSigSendType" SG_ 705 EFP_Status_Taster_Fahrwerk 0;
BA_ "GenSigSwitchedByIgnition" SG_ 705 EFP_Status_Taster_Fahrwerk 0;
BA_ "GenSigSendType" SG_ 705 EFP_Status_Taster_Lift 0;
BA_ "GenSigSwitchedByIgnition" SG_ 705 EFP_Status_Taster_Lift 0;
BA_ "GenSigSendType" SG_ 705 EFP_Verbau_DR 0;
BA_ "GenSigSendType" SG_ 705 EFP_Verbau_eABC 0;
BA_ "GenSigSendType" SG_ 705 EFP_Verbau_eAllrad 0;
BA_ "GenSigSendType" SG_ 705 EFP_Verbau_eAWS 0;
BA_ "GenSigSendType" SG_ 705 EFP_Verbau_LF 0;
BA_ "GenSigSendType" SG_ 705 EFP_Warnung_Naesse 0;
BA_ "GenSigSwitchedByIgnition" SG_ 705 EFP_Warnung_Naesse 0;
BA_ "GenSigSendType" SG_ 705 EFP_Warnung_Naesse_verf 0;
BA_ "GenSigSwitchedByIgnition" SG_ 705 EFP_Warnung_Naesse_verf 0;
BA_ "GenSigSendType" SG_ 705 Fahrwerk_Anzeige_01_BZ 0;
BA_ "GenSigFuncType" SG_ 705 Fahrwerk_Anzeige_01_BZ 1;
BA_ "GenSigSendType" SG_ 705 Fahrwerk_Anzeige_01_CRC 0;
BA_ "GenSigFuncType" SG_ 705 Fahrwerk_Anzeige_01_CRC 2;
BA_ "GenSigSendType" SG_ 705 FDR_Warnung_ALR 0;
BA_ "GenSigSwitchedByIgnition" SG_ 705 FDR_Warnung_ALR 0;
BA_ "GenSigSendType" SG_ 705 FDR_Warnung_TV 0;
BA_ "GenSigSwitchedByIgnition" SG_ 705 FDR_Warnung_TV 0;
BA_ "GenSigSendType" SG_ 705 LF_Texte 0;
BA_ "GenSigSendType" SG_ 705 LF_Texte_2 0;
BA_ "GenSigSwitchedByIgnition" SG_ 705 LF_Texte_2 0;
BA_ "GenSigSendType" SG_ 705 LF_Warnung_Prio1 0;
BA_ "GenSigSendType" SG_ 705 LF_Warnung_Prio1_02 0;
BA_ "GenSigSendType" SG_ 705 LF_Warnung_Prio2 0;
BA_ "GenSigSendType" SG_ 705 NR_LED_Ladelevel 0;
BA_ "GenSigStartValue" SG_ 705 NR_LED_Ladelevel 3;
BA_ "GenSigSwitchedByIgnition" SG_ 705 NR_LED_Ladelevel 0;
BA_ "GenSigSendType" SG_ 705 NR_LED_Offroadlevel 0;
BA_ "GenSigStartValue" SG_ 705 NR_LED_Offroadlevel 3;
BA_ "GenSigSwitchedByIgnition" SG_ 705 NR_LED_Offroadlevel 0;
BA_ "GenSigSendType" SG_ 705 NR_LED_Strassenlevel 0;
BA_ "GenSigStartValue" SG_ 705 NR_LED_Strassenlevel 3;
BA_ "GenSigSwitchedByIgnition" SG_ 705 NR_LED_Strassenlevel 0;
BA_ "GenSigSendType" SG_ 705 NR_LED_Sync 0;
BA_ "GenSigStartValue" SG_ 705 NR_LED_Sync 3;
BA_ "GenSigSwitchedByIgnition" SG_ 705 NR_LED_Sync 0;
BA_ "GenSigSendType" SG_ 705 NR_LED_XtraLevel 0;
BA_ "GenSigStartValue" SG_ 705 NR_LED_XtraLevel 3;
BA_ "GenSigSwitchedByIgnition" SG_ 705 NR_LED_XtraLevel 0;
BA_REL_ "GenSigTimeoutTime" BU_SG_REL_ CGS SG_ 1520 DI_KL_58xd 2000;
BA_REL_ "GenSigTimeoutTime" BU_SG_REL_ CGS SG_ 1520 DI_KL_58xt 2000;
BA_REL_ "GenSigTimeoutTime" BU_SG_REL_ CGS SG_ 253 ESP_21_CRC 1000;
BA_REL_ "GenSigTimeoutTime" BU_SG_REL_ CGS SG_ 253 ESP_21_BZ 1000;
BA_REL_ "GenSigTimeoutTime" BU_SG_REL_ CGS SG_ 253 ESC_v_Signal_Qualifier_High_Low 1000;
BA_REL_ "GenSigTimeoutTime" BU_SG_REL_ CGS SG_ 253 ESP_v_Signal 1000;
BA_REL_ "GenSigTimeoutTime" BU_SG_REL_ CGS SG_ 253 ESP_QBit_v_Signal 1000;
BA_REL_ "GenSigTimeoutTime" BU_SG_REL_ Gateway SG_ 1603 KBI_Einheit_Streckenanz 5000;
BA_REL_ "GenSigTimeoutTime" BU_SG_REL_ Gateway SG_ 1603 KBI_Einheit_Temp 5000;
BA_REL_ "GenSigTimeoutTime" BU_SG_REL_ Gateway SG_ 1603 KBI_Einheit_Volumen 5000;
BA_REL_ "GenSigTimeoutTime" BU_SG_REL_ Gateway SG_ 1603 KBI_Einheit_Sprache 5000;
BA_REL_ "GenSigTimeoutTime" BU_SG_REL_ Gateway_PAG SG_ 1603 KBI_Einheit_Streckenanz 5000;
BA_REL_ "GenSigTimeoutTime" BU_SG_REL_ Gateway_PAG SG_ 1603 KBI_Einheit_Temp 5000;
BA_REL_ "GenSigTimeoutTime" BU_SG_REL_ Gateway_PAG SG_ 1603 KBI_Einheit_Volumen 5000;
BA_REL_ "GenSigTimeoutTime" BU_SG_REL_ Gateway_PAG SG_ 1603 KBI_Einheit_Sprache 5000;
BA_REL_ "GenSigTimeoutTime" BU_SG_REL_ HUD SG_ 1520 DI_Display_Nachtdesign 2000;
BA_REL_ "GenSigTimeoutTime" BU_SG_REL_ HUD SG_ 496 EA_Texte 500;
BA_REL_ "GenSigTimeoutTime" BU_SG_REL_ HUD SG_ 496 ACF_Lampe_Hands_Off 500;
BA_REL_ "GenSigTimeoutTime" BU_SG_REL_ HUD SG_ 496 STP_Primaeranz 500;
BA_REL_ "GenSigTimeoutTime" BU_SG_REL_ HUD SG_ 1603 KBI_Einheit_Streckenanz 5000;
BA_REL_ "GenSigTimeoutTime" BU_SG_REL_ HUD SG_ 1603 KBI_Einheit_Temp 5000;
BA_REL_ "GenSigTimeoutTime" BU_SG_REL_ HUD SG_ 1603 KBI_Einheit_Sprache 5000;
BA_REL_ "GenSigTimeoutTime" BU_SG_REL_ HUD SG_ 503 EPB_Autoholdlampe_02 2000;
BA_REL_ "GenSigTimeoutTime" BU_SG_REL_ HUD SG_ 262 ESP_HDC_Standby 2000;
BA_REL_ "GenSigTimeoutTime" BU_SG_REL_ HUD SG_ 262 ESP_HDC_aktiv 2000;
BA_REL_ "GenSigTimeoutTime" BU_SG_REL_ HUD SG_ 795 ESP_HDC_Geschw_Farbe 500;
BA_REL_ "GenSigTimeoutTime" BU_SG_REL_ HUD SG_ 795 ESP_HDC_Regelgeschw 500;
BA_REL_ "GenSigTimeoutTime" BU_SG_REL_ Kombi SG_ 1520 DI_KL_58xd 2000;
BA_REL_ "GenSigTimeoutTime" BU_SG_REL_ Kombi SG_ 1520 DI_KL_58xs 2000;
BA_REL_ "GenSigTimeoutTime" BU_SG_REL_ Kombi SG_ 1520 DI_Display_Nachtdesign 2000;
BA_REL_ "GenSigTimeoutTime" BU_SG_REL_ Kombi SG_ 1520 DI_KL_58xt 2000;
BA_REL_ "GenSigTimeoutTime" BU_SG_REL_ Kombi SG_ 1520 DI_Fotosensor 2000;
BA_REL_ "GenSigTimeoutTime" BU_SG_REL_ Kombi SG_ 496 EA_02_CRC 500;
BA_REL_ "GenSigTimeoutTime" BU_SG_REL_ Kombi SG_ 496 EA_02_BZ 500;
BA_REL_ "GenSigTimeoutTime" BU_SG_REL_ Kombi SG_ 496 EA_Texte 500;
BA_REL_ "GenSigTimeoutTime" BU_SG_REL_ Kombi SG_ 496 ACF_Lampe_Hands_Off 500;
BA_REL_ "GenSigTimeoutTime" BU_SG_REL_ Kombi SG_ 496 STP_Primaeranz 500;
BA_REL_ "GenSigTimeoutTime" BU_SG_REL_ Kombi SG_ 496 EA_Status_HMI 500;
BA_REL_ "GenSigTimeoutTime" BU_SG_REL_ Kombi SG_ 2527679980 eCall_Funktionsstatus 5000;
BA_REL_ "GenSigTimeoutTime" BU_SG_REL_ Kombi SG_ 2527679980 eCall_Subscription 5000;
BA_REL_ "GenSigTimeoutTime" BU_SG_REL_ Kombi SG_ 2527679980 eCall_Mute_Anf 5000;
BA_REL_ "GenSigTimeoutTime" BU_SG_REL_ Kombi SG_ 996 EFF_Verbrauch_STH 5000;
BA_REL_ "GenSigTimeoutTime" BU_SG_REL_ Kombi SG_ 996 MKE_Texte 5000;
BA_REL_ "GenSigTimeoutTime" BU_SG_REL_ Kombi SG_ 996 MKE_Fehlercode 5000;
BA_REL_ "GenSigTimeoutTime" BU_SG_REL_ Kombi SG_ 1622 ELV_LED_Rot 5000;
BA_REL_ "GenSigTimeoutTime" BU_SG_REL_ Kombi SG_ 1622 ELV_Txt_Lkg_Bewegen 5000;
BA_REL_ "GenSigTimeoutTime" BU_SG_REL_ Kombi SG_ 1622 ELV_Txt_Werkstatt 5000;
BA_REL_ "GenSigTimeoutTime" BU_SG_REL_ Kombi SG_ 1622 ELV_Txt_Defekt 5000;
BA_REL_ "GenSigTimeoutTime" BU_SG_REL_ Kombi SG_ 2589283649 EML_ReifenKorrFaktorHL 5000;
BA_REL_ "GenSigTimeoutTime" BU_SG_REL_ Kombi SG_ 2589283649 EML_ReifenKorrFaktorHR 5000;
BA_REL_ "GenSigTimeoutTime" BU_SG_REL_ Kombi SG_ 2589283649 EML_ReifenKorrFaktorVL 5000;
BA_REL_ "GenSigTimeoutTime" BU_SG_REL_ Kombi SG_ 2589283649 EML_ReifenKorrFaktorVR 5000;
BA_REL_ "GenSigTimeoutTime" BU_SG_REL_ Kombi SG_ 260 EPB_Fehlerstatus_02 5000;
BA_REL_ "GenSigTimeoutTime" BU_SG_REL_ Kombi SG_ 260 EPB_Status_02 5000;
BA_REL_ "GenSigTimeoutTime" BU_SG_REL_ Kombi SG_ 781 EPB_Funktionslampe 2000;
BA_REL_ "GenSigTimeoutTime" BU_SG_REL_ Kombi SG_ 781 EPB_Texte 2000;
BA_REL_ "GenSigTimeoutTime" BU_SG_REL_ Kombi SG_ 781 EPB_Autoholdlampe 2000;
BA_REL_ "GenSigTimeoutTime" BU_SG_REL_ Kombi SG_ 781 EPB_Fehlermeldungen 2000;
BA_REL_ "GenSigTimeoutTime" BU_SG_REL_ Kombi SG_ 503 EPB_03_CRC 2000;
BA_REL_ "GenSigTimeoutTime" BU_SG_REL_ Kombi SG_ 503 EPB_03_BZ 2000;
BA_REL_ "GenSigTimeoutTime" BU_SG_REL_ Kombi SG_ 503 EPB_Texte_02 2000;
BA_REL_ "GenSigTimeoutTime" BU_SG_REL_ Kombi SG_ 503 EPB_Fehlermeldungen_02 2000;
BA_REL_ "GenSigTimeoutTime" BU_SG_REL_ Kombi SG_ 503 EPB_Funktionslampe_02 2000;
BA_REL_ "GenSigTimeoutTime" BU_SG_REL_ Kombi SG_ 503 EPB_Autoholdlampe_02 2000;
BA_REL_ "GenSigTimeoutTime" BU_SG_REL_ Kombi SG_ 262 ESP_HDC_Standby 2000;
BA_REL_ "GenSigTimeoutTime" BU_SG_REL_ Kombi SG_ 262 ESP_HDC_aktiv 2000;
BA_REL_ "GenSigTimeoutTime" BU_SG_REL_ Kombi SG_ 1629 ESP_Zaehnezahl 1600;
BA_REL_ "GenSigTimeoutTime" BU_SG_REL_ Kombi SG_ 1629 ESP_Stoppverbot_Anz_05 1600;
BA_REL_ "GenSigTimeoutTime" BU_SG_REL_ Kombi SG_ 253 ESP_Diagnose 1000;
BA_REL_ "GenSigTimeoutTime" BU_SG_REL_ Kombi SG_ 253 ESP_v_Signal 1000;
BA_REL_ "GenSigTimeoutTime" BU_SG_REL_ Kombi SG_ 253 ESP_QBit_v_Signal 1000;
BA_REL_ "GenSigTimeoutTime" BU_SG_REL_ Kombi SG_ 795 ESP_24_CRC 500;
BA_REL_ "GenSigTimeoutTime" BU_SG_REL_ Kombi SG_ 795 ESP_24_BZ 500;
BA_REL_ "GenSigTimeoutTime" BU_SG_REL_ Kombi SG_ 795 ESP_Lampe 500;
BA_REL_ "GenSigTimeoutTime" BU_SG_REL_ Kombi SG_ 795 ABS_Lampe 500;
BA_REL_ "GenSigTimeoutTime" BU_SG_REL_ Kombi SG_ 795 BK_Lampe_02 500;
BA_REL_ "GenSigTimeoutTime" BU_SG_REL_ Kombi SG_ 795 ESP_m_Raddrehz 500;
BA_REL_ "GenSigTimeoutTime" BU_SG_REL_ Kombi SG_ 795 ESP_Textanzeigen_03 500;
BA_REL_ "GenSigTimeoutTime" BU_SG_REL_ Kombi SG_ 795 ESP_Meldungen 500;
BA_REL_ "GenSigTimeoutTime" BU_SG_REL_ Kombi SG_ 795 ESP_Wegimp_VA 500;
BA_REL_ "GenSigTimeoutTime" BU_SG_REL_ Kombi SG_ 795 ESP_Fehlerstatus_Wegimp 500;
BA_REL_ "GenSigTimeoutTime" BU_SG_REL_ Kombi SG_ 795 ESP_Wegimp_Ueberlauf 500;
BA_REL_ "GenSigTimeoutTime" BU_SG_REL_ Kombi SG_ 795 ESP_HDC_Geschw_Farbe 500;
BA_REL_ "GenSigTimeoutTime" BU_SG_REL_ Kombi SG_ 795 ESP_Off_Lampe 500;
BA_REL_ "GenSigTimeoutTime" BU_SG_REL_ Kombi SG_ 795 ESP_HDC_Regelgeschw 500;
BA_REL_ "GenSigTimeoutTime" BU_SG_REL_ Kombi SG_ 795 ESP_BKV_Warnung 500;
BA_REL_ "GenSigTimeoutTime" BU_SG_REL_ Kombi SG_ 508 ESC_MBK_Meldungen 2000;
BA_REL_ "GenSigTimeoutTime" BU_SG_REL_ Kombi SG_ 508 ESP_EDS_Anzeige 2000;
BA_REL_ "GenSigTimeoutTime" BU_SG_REL_ Kombi SG_ 508 RLE_Anzeigen 2000;
BA_REL_ "GenSigTimeoutTime" BU_SG_REL_ Kombi SG_ 508 ESC_FBA_Meldungen 2000;
BA_REL_ "GenSigTimeoutTime" BU_SG_REL_ Kombi SG_ 508 ESP_Offroad_Lampe 2000;
BA_REL_ "GenSigTimeoutTime" BU_SG_REL_ Kombi SG_ 508 ESP_HDC_Textanzeigen 2000;
BA_REL_ "GenSigTimeoutTime" BU_SG_REL_ Kombi SG_ 2589283470 ESC_Kilometer 5000;
BA_REL_ "GenSigTimeoutTime" BU_SG_REL_ Kombi SG_ 2589283470 ESC_Kilometer_MUX 5000;
BA_REL_ "GenSigTimeoutTime" BU_SG_REL_ Kombi SG_ 2589283470 ESC_Signatur_Kilometer_GFA_01 5000;
BA_REL_ "GenSigTimeoutTime" BU_SG_REL_ Kombi SG_ 2589283470 ESC_Signatur_Kilometer_IKA_01 5000;
BA_REL_ "GenSigTimeoutTime" BU_SG_REL_ Kombi SG_ 2589283470 ESC_Signatur_Kilometer_GFA_02 5000;
BA_REL_ "GenSigTimeoutTime" BU_SG_REL_ Kombi SG_ 2589283470 ESC_Signatur_Kilometer_IKA_02 5000;
BA_REL_ "GenSigTimeoutTime" BU_SG_REL_ Kombi SG_ 2527679662 ESP_Off_Anf_KBI 1600;
BA_REL_ "GenSigTimeoutTime" BU_SG_REL_ Kombi SG_ 2527679662 ESC_Reku_Anzeige 1600;
BA_REL_ "GenSigTimeoutTime" BU_SG_REL_ Kombi SG_ 2527679662 ESC_Textanzeigen_SysSpez 1600;
BA_REL_ "GenSigTimeoutTime" BU_SG_REL_ Kombi SG_ 2527679662 BRS_BFLS_Verbauzustand 1600;
BA_REL_ "GenSigTimeoutTime" BU_SG_REL_ Kombi SG_ 2527679662 BRS_Bremsfluessigkeit_Warnungen 1600;
BA_REL_ "GenSigTimeoutTime" BU_SG_REL_ Kombi SG_ 2527679824 Fahrwerk_14_CRC 3200;
BA_REL_ "GenSigTimeoutTime" BU_SG_REL_ Kombi SG_ 2527679824 Fahrwerk_14_BZ 3200;
BA_REL_ "GenSigTimeoutTime" BU_SG_REL_ Kombi SG_ 2527679824 PTLM_Warnung_2 3200;
BA_REL_ "GenSigTimeoutTime" BU_SG_REL_ Kombi SG_ 2527679824 EFP_WarnungBauteilschutz 3200;
BA_REL_ "GenSigTimeoutTime" BU_SG_REL_ Kombi SG_ 2527679824 PTLM_vLimit 3200;
BA_REL_ "GenSigTimeoutTime" BU_SG_REL_ Kombi SG_ 2527679824 PTLM_Warnung 3200;
BA_REL_ "GenSigTimeoutTime" BU_SG_REL_ Kombi SG_ 705 Fahrwerk_Anzeige_01_CRC 800;
BA_REL_ "GenSigTimeoutTime" BU_SG_REL_ Kombi SG_ 705 Fahrwerk_Anzeige_01_BZ 800;
BA_REL_ "GenSigTimeoutTime" BU_SG_REL_ Kombi SG_ 705 EFP_Verbau_DR 800;
BA_REL_ "GenSigTimeoutTime" BU_SG_REL_ Kombi SG_ 705 EFP_Verbau_eAllrad 800;
BA_REL_ "GenSigTimeoutTime" BU_SG_REL_ Kombi SG_ 705 EFP_Verbau_LF 800;
BA_REL_ "GenSigTimeoutTime" BU_SG_REL_ Kombi SG_ 705 LF_Texte 800;
BA_REL_ "GenSigTimeoutTime" BU_SG_REL_ Kombi SG_ 705 EFP_Verbau_eAWS 800;
BA_REL_ "GenSigTimeoutTime" BU_SG_REL_ Kombi SG_ 705 eAWS_Warnmeldung_Prio1 800;
BA_REL_ "GenSigTimeoutTime" BU_SG_REL_ Kombi SG_ 705 eAWS_Warnmeldung_Prio2 800;
BA_REL_ "GenSigTimeoutTime" BU_SG_REL_ Kombi SG_ 705 LF_Texte_2 800;
BA_REL_ "GenSigTimeoutTime" BU_SG_REL_ Kombi SG_ 705 FDR_Warnung_ALR 800;
BA_REL_ "GenSigTimeoutTime" BU_SG_REL_ Kombi SG_ 705 FDR_Warnung_TV 800;
BA_REL_ "GenSigTimeoutTime" BU_SG_REL_ Kombi SG_ 705 EFP_Verbau_eABC 800;
BA_REL_ "GenSigTimeoutTime" BU_SG_REL_ Kombi SG_ 705 LF_Warnung_Prio1_02 800;
BA_REL_ "GenSigTimeoutTime" BU_SG_REL_ Kombi SG_ 705 LF_Warnung_Prio2 800;
BA_REL_ "GenSigTimeoutTime" BU_SG_REL_ Kombi SG_ 705 eABC_Warnung_Prio2 800;
BA_REL_ "GenSigTimeoutTime" BU_SG_REL_ Kombi SG_ 705 eABC_Warnung_Prio1 800;
BA_REL_ "GenSigTimeoutTime" BU_SG_REL_ Kombi SG_ 705 eABC_Texte 800;
BA_REL_ "GenSigTimeoutTime" BU_SG_REL_ Kombi SG_ 705 DR_Warnung 800;
BA_REL_ "GenSigTimeoutTime" BU_SG_REL_ Kombi_LB SG_ 1520 DI_KL_58xd 2000;
BA_REL_ "GenSigTimeoutTime" BU_SG_REL_ Kombi_LB SG_ 1520 DI_KL_58xs 2000;
BA_REL_ "GenSigTimeoutTime" BU_SG_REL_ Kombi_LB SG_ 1520 DI_Display_Nachtdesign 2000;
BA_REL_ "GenSigTimeoutTime" BU_SG_REL_ Kombi_LB SG_ 1520 DI_KL_58xt 2000;
BA_REL_ "GenSigTimeoutTime" BU_SG_REL_ Kombi_LB SG_ 1520 DI_Fotosensor 2000;
BA_REL_ "GenSigTimeoutTime" BU_SG_REL_ Kombi_LB SG_ 2527679773 DLM_BFS_GenericFail 5000;
BA_REL_ "GenSigTimeoutTime" BU_SG_REL_ Kombi_LB SG_ 2527679773 DLM_BFS_SystemError 5000;
BA_REL_ "GenSigTimeoutTime" BU_SG_REL_ Kombi_LB SG_ 2527679773 DLM_BFS_SwitchRequest 5000;
BA_REL_ "GenSigTimeoutTime" BU_SG_REL_ Kombi_LB SG_ 2527679773 DLM_BFS_WDSMStatus 5000;
BA_REL_ "GenSigTimeoutTime" BU_SG_REL_ Kombi_LB SG_ 2527679773 DLM_BFS_WDSMTrigger 5000;
BA_REL_ "GenSigTimeoutTime" BU_SG_REL_ Kombi_LB SG_ 2527679773 DLM_BFS_ProductionMode 5000;
BA_REL_ "GenSigTimeoutTime" BU_SG_REL_ Kombi_LB SG_ 2527679773 DLM_BFS_DoorStatus 5000;
BA_REL_ "GenSigTimeoutTime" BU_SG_REL_ Kombi_LB SG_ 2527679773 DLM_BFS_LatchStatusFeedbac 5000;
BA_REL_ "GenSigTimeoutTime" BU_SG_REL_ Kombi_LB SG_ 2527679773 DLM_BFS_SuperCapStatus 5000;
BA_REL_ "GenSigTimeoutTime" BU_SG_REL_ Kombi_LB SG_ 2527679772 DLM_FS_GenericFailure 5000;
BA_REL_ "GenSigTimeoutTime" BU_SG_REL_ Kombi_LB SG_ 2527679772 DLM_FS_SystemError 5000;
BA_REL_ "GenSigTimeoutTime" BU_SG_REL_ Kombi_LB SG_ 2527679772 DLM_FS_SwitchRequest 5000;
BA_REL_ "GenSigTimeoutTime" BU_SG_REL_ Kombi_LB SG_ 2527679772 DLM_FS_WDSMStatus 5000;
BA_REL_ "GenSigTimeoutTime" BU_SG_REL_ Kombi_LB SG_ 2527679772 DLM_FS_WDSMTrigger 5000;
BA_REL_ "GenSigTimeoutTime" BU_SG_REL_ Kombi_LB SG_ 2527679772 DLM_FS_ProductionMode 5000;
BA_REL_ "GenSigTimeoutTime" BU_SG_REL_ Kombi_LB SG_ 2527679772 DLM_FS_DoorStatus 5000;
BA_REL_ "GenSigTimeoutTime" BU_SG_REL_ Kombi_LB SG_ 2527679772 DLM_FS_LatchStatusFeedback 5000;
BA_REL_ "GenSigTimeoutTime" BU_SG_REL_ Kombi_LB SG_ 2527679772 DLM_FS_SuperCapStatus 5000;
BA_REL_ "GenSigTimeoutTime" BU_SG_REL_ Kombi_LB SG_ 496 EA_02_CRC 500;
BA_REL_ "GenSigTimeoutTime" BU_SG_REL_ Kombi_LB SG_ 496 EA_02_BZ 500;
BA_REL_ "GenSigTimeoutTime" BU_SG_REL_ Kombi_LB SG_ 496 EA_Texte 500;
BA_REL_ "GenSigTimeoutTime" BU_SG_REL_ Kombi_LB SG_ 496 ACF_Lampe_Hands_Off 500;
BA_REL_ "GenSigTimeoutTime" BU_SG_REL_ Kombi_LB SG_ 496 STP_Primaeranz 500;
BA_REL_ "GenSigTimeoutTime" BU_SG_REL_ Kombi_LB SG_ 2527679980 eCall_Funktionsstatus 5000;
BA_REL_ "GenSigTimeoutTime" BU_SG_REL_ Kombi_LB SG_ 2527679980 eCall_Subscription 5000;
BA_REL_ "GenSigTimeoutTime" BU_SG_REL_ Kombi_LB SG_ 2527679980 eCall_Mute_Anf 5000;
BA_REL_ "GenSigTimeoutTime" BU_SG_REL_ Kombi_LB SG_ 996 EFF_Verbrauch_STH 5000;
BA_REL_ "GenSigTimeoutTime" BU_SG_REL_ Kombi_LB SG_ 996 MKE_Texte 5000;
BA_REL_ "GenSigTimeoutTime" BU_SG_REL_ Kombi_LB SG_ 996 MKE_Fehlercode 5000;
BA_REL_ "GenSigTimeoutTime" BU_SG_REL_ Kombi_LB SG_ 1622 ELV_LED_Rot 5000;
BA_REL_ "GenSigTimeoutTime" BU_SG_REL_ Kombi_LB SG_ 1622 ELV_Txt_Lkg_Bewegen 5000;
BA_REL_ "GenSigTimeoutTime" BU_SG_REL_ Kombi_LB SG_ 1622 ELV_Txt_Werkstatt 5000;
BA_REL_ "GenSigTimeoutTime" BU_SG_REL_ Kombi_LB SG_ 1622 ELV_Txt_Defekt 5000;
BA_REL_ "GenSigTimeoutTime" BU_SG_REL_ Kombi_LB SG_ 2589283649 EML_ReifenKorrFaktorHL 5000;
BA_REL_ "GenSigTimeoutTime" BU_SG_REL_ Kombi_LB SG_ 2589283649 EML_ReifenKorrFaktorHR 5000;
BA_REL_ "GenSigTimeoutTime" BU_SG_REL_ Kombi_LB SG_ 2589283649 EML_ReifenKorrFaktorVL 5000;
BA_REL_ "GenSigTimeoutTime" BU_SG_REL_ Kombi_LB SG_ 2589283649 EML_ReifenKorrFaktorVR 5000;
BA_REL_ "GenSigTimeoutTime" BU_SG_REL_ Kombi_LB SG_ 260 EPB_Fehlerstatus_02 5000;
BA_REL_ "GenSigTimeoutTime" BU_SG_REL_ Kombi_LB SG_ 260 EPB_Status_02 5000;
BA_REL_ "GenSigTimeoutTime" BU_SG_REL_ Kombi_LB SG_ 781 EPB_Funktionslampe 2000;
BA_REL_ "GenSigTimeoutTime" BU_SG_REL_ Kombi_LB SG_ 781 EPB_Texte 2000;
BA_REL_ "GenSigTimeoutTime" BU_SG_REL_ Kombi_LB SG_ 781 EPB_Autoholdlampe 2000;
BA_REL_ "GenSigTimeoutTime" BU_SG_REL_ Kombi_LB SG_ 781 EPB_Fehlermeldungen 2000;
BA_REL_ "GenSigTimeoutTime" BU_SG_REL_ Kombi_LB SG_ 503 EPB_03_CRC 2000;
BA_REL_ "GenSigTimeoutTime" BU_SG_REL_ Kombi_LB SG_ 503 EPB_03_BZ 2000;
BA_REL_ "GenSigTimeoutTime" BU_SG_REL_ Kombi_LB SG_ 503 EPB_Texte_02 2000;
BA_REL_ "GenSigTimeoutTime" BU_SG_REL_ Kombi_LB SG_ 503 EPB_Fehlermeldungen_02 2000;
BA_REL_ "GenSigTimeoutTime" BU_SG_REL_ Kombi_LB SG_ 503 EPB_Funktionslampe_02 2000;
BA_REL_ "GenSigTimeoutTime" BU_SG_REL_ Kombi_LB SG_ 503 EPB_Autoholdlampe_02 2000;
BA_REL_ "GenSigTimeoutTime" BU_SG_REL_ Kombi_LB SG_ 262 ESP_HDC_Standby 2000;
BA_REL_ "GenSigTimeoutTime" BU_SG_REL_ Kombi_LB SG_ 262 ESP_HDC_aktiv 2000;
BA_REL_ "GenSigTimeoutTime" BU_SG_REL_ Kombi_LB SG_ 262 ESP_Eingr_HL 2000;
BA_REL_ "GenSigTimeoutTime" BU_SG_REL_ Kombi_LB SG_ 262 ESP_Eingr_HR 2000;
BA_REL_ "GenSigTimeoutTime" BU_SG_REL_ Kombi_LB SG_ 262 ESP_Eingr_VL 2000;
BA_REL_ "GenSigTimeoutTime" BU_SG_REL_ Kombi_LB SG_ 262 ESP_Eingr_VR 2000;
BA_REL_ "GenSigTimeoutTime" BU_SG_REL_ Kombi_LB SG_ 1629 ESP_20_CRC 1600;
BA_REL_ "GenSigTimeoutTime" BU_SG_REL_ Kombi_LB SG_ 1629 ESP_20_BZ 1600;
BA_REL_ "GenSigTimeoutTime" BU_SG_REL_ Kombi_LB SG_ 1629 ESP_Zaehnezahl 1600;
BA_REL_ "GenSigTimeoutTime" BU_SG_REL_ Kombi_LB SG_ 1629 ESP_Charisma_FahrPr 1600;
BA_REL_ "GenSigTimeoutTime" BU_SG_REL_ Kombi_LB SG_ 1629 ESP_Stoppverbot_Anz_05 1600;
BA_REL_ "GenSigTimeoutTime" BU_SG_REL_ Kombi_LB SG_ 1629 BR_Reifenumfang 1600;
BA_REL_ "GenSigTimeoutTime" BU_SG_REL_ Kombi_LB SG_ 253 ESP_Diagnose 1000;
BA_REL_ "GenSigTimeoutTime" BU_SG_REL_ Kombi_LB SG_ 253 ESP_v_Signal 1000;
BA_REL_ "GenSigTimeoutTime" BU_SG_REL_ Kombi_LB SG_ 253 ASR_Tastung_passiv 1000;
BA_REL_ "GenSigTimeoutTime" BU_SG_REL_ Kombi_LB SG_ 253 ESP_Tastung_passiv 1000;
BA_REL_ "GenSigTimeoutTime" BU_SG_REL_ Kombi_LB SG_ 253 ESP_QBit_v_Signal 1000;
BA_REL_ "GenSigTimeoutTime" BU_SG_REL_ Kombi_LB SG_ 253 ASR_Anf 1000;
BA_REL_ "GenSigTimeoutTime" BU_SG_REL_ Kombi_LB SG_ 1470 BR_Reifenumfang_sekundaer 3200;
BA_REL_ "GenSigTimeoutTime" BU_SG_REL_ Kombi_LB SG_ 795 ESP_24_CRC 500;
BA_REL_ "GenSigTimeoutTime" BU_SG_REL_ Kombi_LB SG_ 795 ESP_24_BZ 500;
BA_REL_ "GenSigTimeoutTime" BU_SG_REL_ Kombi_LB SG_ 795 ESP_Lampe 500;
BA_REL_ "GenSigTimeoutTime" BU_SG_REL_ Kombi_LB SG_ 795 ABS_Lampe 500;
BA_REL_ "GenSigTimeoutTime" BU_SG_REL_ Kombi_LB SG_ 795 BK_Lampe_02 500;
BA_REL_ "GenSigTimeoutTime" BU_SG_REL_ Kombi_LB SG_ 795 ESP_m_Raddrehz 500;
BA_REL_ "GenSigTimeoutTime" BU_SG_REL_ Kombi_LB SG_ 795 ESP_Textanzeigen_03 500;
BA_REL_ "GenSigTimeoutTime" BU_SG_REL_ Kombi_LB SG_ 795 ESP_Meldungen 500;
BA_REL_ "GenSigTimeoutTime" BU_SG_REL_ Kombi_LB SG_ 795 ESP_Wegimp_VA 500;
BA_REL_ "GenSigTimeoutTime" BU_SG_REL_ Kombi_LB SG_ 795 ESP_Fehlerstatus_Wegimp 500;
BA_REL_ "GenSigTimeoutTime" BU_SG_REL_ Kombi_LB SG_ 795 ESP_Wegimp_Ueberlauf 500;
BA_REL_ "GenSigTimeoutTime" BU_SG_REL_ Kombi_LB SG_ 795 ESP_HDC_Geschw_Farbe 500;
BA_REL_ "GenSigTimeoutTime" BU_SG_REL_ Kombi_LB SG_ 795 ESP_Off_Lampe 500;
BA_REL_ "GenSigTimeoutTime" BU_SG_REL_ Kombi_LB SG_ 795 ESP_HDC_Regelgeschw 500;
BA_REL_ "GenSigTimeoutTime" BU_SG_REL_ Kombi_LB SG_ 795 ESP_BKV_Warnung 500;
BA_REL_ "GenSigTimeoutTime" BU_SG_REL_ Kombi_LB SG_ 508 ESP_32_CRC 2000;
BA_REL_ "GenSigTimeoutTime" BU_SG_REL_ Kombi_LB SG_ 508 ESP_32_BZ 2000;
BA_REL_ "GenSigTimeoutTime" BU_SG_REL_ Kombi_LB SG_ 508 ESC_MBK_Meldungen 2000;
BA_REL_ "GenSigTimeoutTime" BU_SG_REL_ Kombi_LB SG_ 508 ESP_EDS_Anzeige 2000;
BA_REL_ "GenSigTimeoutTime" BU_SG_REL_ Kombi_LB SG_ 508 RLE_Anzeigen 2000;
BA_REL_ "GenSigTimeoutTime" BU_SG_REL_ Kombi_LB SG_ 508 ESC_FBA_Meldungen 2000;
BA_REL_ "GenSigTimeoutTime" BU_SG_REL_ Kombi_LB SG_ 508 ESP_HDC_LED 2000;
BA_REL_ "GenSigTimeoutTime" BU_SG_REL_ Kombi_LB SG_ 508 ESP_Off_LED 2000;
BA_REL_ "GenSigTimeoutTime" BU_SG_REL_ Kombi_LB SG_ 508 ESP_Offroad_Lampe 2000;
BA_REL_ "GenSigTimeoutTime" BU_SG_REL_ Kombi_LB SG_ 508 ESP_HDC_Textanzeigen 2000;
BA_REL_ "GenSigTimeoutTime" BU_SG_REL_ Kombi_LB SG_ 2589283470 ESC_Kilometer 5000;
BA_REL_ "GenSigTimeoutTime" BU_SG_REL_ Kombi_LB SG_ 2589283470 ESC_Kilometer_MUX 5000;
BA_REL_ "GenSigTimeoutTime" BU_SG_REL_ Kombi_LB SG_ 2589283470 ESC_Signatur_Kilometer_GFA_01 5000;
BA_REL_ "GenSigTimeoutTime" BU_SG_REL_ Kombi_LB SG_ 2589283470 ESC_Signatur_Kilometer_IKA_01 5000;
BA_REL_ "GenSigTimeoutTime" BU_SG_REL_ Kombi_LB SG_ 2589283470 ESC_Signatur_Kilometer_GFA_02 5000;
BA_REL_ "GenSigTimeoutTime" BU_SG_REL_ Kombi_LB SG_ 2589283470 ESC_Signatur_Kilometer_IKA_02 5000;
BA_REL_ "GenSigTimeoutTime" BU_SG_REL_ Kombi_LB SG_ 2527679662 ESC_Reku_Anzeige 1600;
BA_REL_ "GenSigTimeoutTime" BU_SG_REL_ Kombi_LB SG_ 2527679662 ESC_Textanzeigen_SysSpez 1600;
BA_REL_ "GenSigTimeoutTime" BU_SG_REL_ Kombi_LB SG_ 2527679662 BRS_BFLS_Verbauzustand 1600;
BA_REL_ "GenSigTimeoutTime" BU_SG_REL_ Kombi_LB SG_ 2527679662 BRS_Bremsfluessigkeit_Warnungen 1600;
BA_REL_ "GenSigTimeoutTime" BU_SG_REL_ Kombi_LB SG_ 600 ESP_54_CRC 4000;
BA_REL_ "GenSigTimeoutTime" BU_SG_REL_ Kombi_LB SG_ 600 ESP_54_BZ 4000;
BA_REL_ "GenSigTimeoutTime" BU_SG_REL_ Kombi_LB SG_ 600 ESP_DriftLevel 4000;
BA_REL_ "GenSigTimeoutTime" BU_SG_REL_ Kombi_LB SG_ 600 ESP_DriftText 4000;
BA_REL_ "GenSigTimeoutTime" BU_SG_REL_ Kombi_LB SG_ 600 ESP_DriftStatus 4000;
BA_REL_ "GenSigTimeoutTime" BU_SG_REL_ Kombi_LB SG_ 600 ESP_DriftGong 4000;
BA_REL_ "GenSigTimeoutTime" BU_SG_REL_ Kombi_LB SG_ 600 ESP_Slider_Text 4000;
BA_REL_ "GenSigTimeoutTime" BU_SG_REL_ Kombi_LB SG_ 600 ESP_Slider_Lamp 4000;
BA_REL_ "GenSigTimeoutTime" BU_SG_REL_ Kombi_LB SG_ 600 ESP_Slider_Gong 4000;
BA_REL_ "GenSigTimeoutTime" BU_SG_REL_ Kombi_LB SG_ 600 ESP_Slider_Status 4000;
BA_REL_ "GenSigTimeoutTime" BU_SG_REL_ Kombi_LB SG_ 600 ESP_Slider_ist_01 4000;
BA_REL_ "GenSigTimeoutTime" BU_SG_REL_ Kombi_LB SG_ 600 ESP_Slider_ist_02 4000;
BA_REL_ "GenSigTimeoutTime" BU_SG_REL_ Kombi_LB SG_ 600 ESP_Slider_ist_03 4000;
BA_REL_ "GenSigTimeoutTime" BU_SG_REL_ Kombi_LB SG_ 303 ESP_Fahrbahnreibwert_dyn_Class 500;
BA_REL_ "GenSigTimeoutTime" BU_SG_REL_ Kombi_LB SG_ 303 ESP_Fahrbahnreibwert_dyn 500;
BA_REL_ "GenSigTimeoutTime" BU_SG_REL_ Kombi_LB SG_ 303 ESP_Schwimmwinkel 500;
BA_REL_ "GenSigTimeoutTime" BU_SG_REL_ Kombi_LB SG_ 705 Fahrwerk_Anzeige_01_CRC 800;
BA_REL_ "GenSigTimeoutTime" BU_SG_REL_ Kombi_LB SG_ 705 Fahrwerk_Anzeige_01_BZ 800;
BA_REL_ "GenSigTimeoutTime" BU_SG_REL_ Kombi_LB SG_ 705 EFP_Verbau_DR 800;
BA_REL_ "GenSigTimeoutTime" BU_SG_REL_ Kombi_LB SG_ 705 EFP_Verbau_eAllrad 800;
BA_REL_ "GenSigTimeoutTime" BU_SG_REL_ Kombi_LB SG_ 705 EFP_Verbau_LF 800;
BA_REL_ "GenSigTimeoutTime" BU_SG_REL_ Kombi_LB SG_ 705 LF_Texte 800;
BA_REL_ "GenSigTimeoutTime" BU_SG_REL_ Kombi_LB SG_ 705 EFP_Verbau_eAWS 800;
BA_REL_ "GenSigTimeoutTime" BU_SG_REL_ Kombi_LB SG_ 705 LF_Texte_2 800;
BA_REL_ "GenSigTimeoutTime" BU_SG_REL_ Kombi_LB SG_ 705 FDR_Warnung_ALR 800;
BA_REL_ "GenSigTimeoutTime" BU_SG_REL_ Kombi_LB SG_ 705 FDR_Warnung_TV 800;
BA_REL_ "GenSigTimeoutTime" BU_SG_REL_ Kombi_LB SG_ 705 EFP_Verbau_eABC 800;
BA_REL_ "GenSigTimeoutTime" BU_SG_REL_ Kombi_LB SG_ 705 LF_Warnung_Prio1_02 800;
BA_REL_ "GenSigTimeoutTime" BU_SG_REL_ Kombi_LB SG_ 705 LF_Warnung_Prio2 800;
BA_REL_ "GenSigTimeoutTime" BU_SG_REL_ Kombi_LB SG_ 705 DR_Warnung 800;
BA_REL_ "GenSigTimeoutTime" BU_SG_REL_ Kombi_PAG SG_ 1520 DI_KL_58xd 2000;
BA_REL_ "GenSigTimeoutTime" BU_SG_REL_ Kombi_PAG SG_ 1520 DI_KL_58xs 2000;
BA_REL_ "GenSigTimeoutTime" BU_SG_REL_ Kombi_PAG SG_ 1520 DI_KL_58xt 2000;
BA_REL_ "GenSigTimeoutTime" BU_SG_REL_ Kombi_PAG SG_ 1520 DI_Fotosensor 2000;
BA_REL_ "GenSigTimeoutTime" BU_SG_REL_ Kombi_PAG SG_ 496 EA_02_CRC 500;
BA_REL_ "GenSigTimeoutTime" BU_SG_REL_ Kombi_PAG SG_ 496 EA_02_BZ 500;
BA_REL_ "GenSigTimeoutTime" BU_SG_REL_ Kombi_PAG SG_ 496 EA_Texte 500;
BA_REL_ "GenSigTimeoutTime" BU_SG_REL_ Kombi_PAG SG_ 496 ACF_Lampe_Hands_Off 500;
BA_REL_ "GenSigTimeoutTime" BU_SG_REL_ Kombi_PAG SG_ 496 STP_Primaeranz 500;
BA_REL_ "GenSigTimeoutTime" BU_SG_REL_ Kombi_PAG SG_ 2527679980 eCall_Funktionsstatus 5000;
BA_REL_ "GenSigTimeoutTime" BU_SG_REL_ Kombi_PAG SG_ 2527679980 eCall_Subscription 5000;
BA_REL_ "GenSigTimeoutTime" BU_SG_REL_ Kombi_PAG SG_ 2527679980 eCall_Funktionsstatus_02 5000;
BA_REL_ "GenSigTimeoutTime" BU_SG_REL_ Kombi_PAG SG_ 996 EFF_Verbrauch_STH 5000;
BA_REL_ "GenSigTimeoutTime" BU_SG_REL_ Kombi_PAG SG_ 996 MKE_Texte 5000;
BA_REL_ "GenSigTimeoutTime" BU_SG_REL_ Kombi_PAG SG_ 996 MKE_Fehlercode 5000;
BA_REL_ "GenSigTimeoutTime" BU_SG_REL_ Kombi_PAG SG_ 1622 ELV_LED_Rot 5000;
BA_REL_ "GenSigTimeoutTime" BU_SG_REL_ Kombi_PAG SG_ 1622 ELV_Txt_Lkg_Bewegen 5000;
BA_REL_ "GenSigTimeoutTime" BU_SG_REL_ Kombi_PAG SG_ 1622 ELV_Txt_Werkstatt 5000;
BA_REL_ "GenSigTimeoutTime" BU_SG_REL_ Kombi_PAG SG_ 1622 ELV_Txt_Defekt 5000;
BA_REL_ "GenSigTimeoutTime" BU_SG_REL_ Kombi_PAG SG_ 2589283649 EML_ReifenKorrFaktorHL 5000;
BA_REL_ "GenSigTimeoutTime" BU_SG_REL_ Kombi_PAG SG_ 2589283649 EML_ReifenKorrFaktorHR 5000;
BA_REL_ "GenSigTimeoutTime" BU_SG_REL_ Kombi_PAG SG_ 2589283649 EML_ReifenKorrFaktorVL 5000;
BA_REL_ "GenSigTimeoutTime" BU_SG_REL_ Kombi_PAG SG_ 2589283649 EML_ReifenKorrFaktorVR 5000;
BA_REL_ "GenSigTimeoutTime" BU_SG_REL_ Kombi_PAG SG_ 260 EPB_Fehlerstatus_02 5000;
BA_REL_ "GenSigTimeoutTime" BU_SG_REL_ Kombi_PAG SG_ 260 EPB_Status_02 5000;
BA_REL_ "GenSigTimeoutTime" BU_SG_REL_ Kombi_PAG SG_ 781 EPB_Funktionslampe 2000;
BA_REL_ "GenSigTimeoutTime" BU_SG_REL_ Kombi_PAG SG_ 781 EPB_Texte 2000;
BA_REL_ "GenSigTimeoutTime" BU_SG_REL_ Kombi_PAG SG_ 781 EPB_Autoholdlampe 2000;
BA_REL_ "GenSigTimeoutTime" BU_SG_REL_ Kombi_PAG SG_ 781 EPB_Fehlermeldungen 2000;
BA_REL_ "GenSigTimeoutTime" BU_SG_REL_ Kombi_PAG SG_ 503 EPB_03_CRC 2000;
BA_REL_ "GenSigTimeoutTime" BU_SG_REL_ Kombi_PAG SG_ 503 EPB_03_BZ 2000;
BA_REL_ "GenSigTimeoutTime" BU_SG_REL_ Kombi_PAG SG_ 503 EPB_Texte_02 2000;
BA_REL_ "GenSigTimeoutTime" BU_SG_REL_ Kombi_PAG SG_ 503 EPB_Fehlermeldungen_02 2000;
BA_REL_ "GenSigTimeoutTime" BU_SG_REL_ Kombi_PAG SG_ 503 EPB_Funktionslampe_02 2000;
BA_REL_ "GenSigTimeoutTime" BU_SG_REL_ Kombi_PAG SG_ 503 EPB_Autoholdlampe_02 2000;
BA_REL_ "GenSigTimeoutTime" BU_SG_REL_ Kombi_PAG SG_ 262 ESP_HDC_Standby 2000;
BA_REL_ "GenSigTimeoutTime" BU_SG_REL_ Kombi_PAG SG_ 262 ESP_HDC_aktiv 2000;
BA_REL_ "GenSigTimeoutTime" BU_SG_REL_ Kombi_PAG SG_ 1629 ESP_Zaehnezahl 1600;
BA_REL_ "GenSigTimeoutTime" BU_SG_REL_ Kombi_PAG SG_ 253 ESP_21_CRC 1000;
BA_REL_ "GenSigTimeoutTime" BU_SG_REL_ Kombi_PAG SG_ 253 ESP_21_BZ 1000;
BA_REL_ "GenSigTimeoutTime" BU_SG_REL_ Kombi_PAG SG_ 253 ESP_Diagnose 1000;
BA_REL_ "GenSigTimeoutTime" BU_SG_REL_ Kombi_PAG SG_ 253 ESC_v_Signal_Qualifier_High_Low 1000;
BA_REL_ "GenSigTimeoutTime" BU_SG_REL_ Kombi_PAG SG_ 253 ESP_v_Signal 1000;
BA_REL_ "GenSigTimeoutTime" BU_SG_REL_ Kombi_PAG SG_ 253 ASR_Tastung_passiv 1000;
BA_REL_ "GenSigTimeoutTime" BU_SG_REL_ Kombi_PAG SG_ 253 ESP_Tastung_passiv 1000;
BA_REL_ "GenSigTimeoutTime" BU_SG_REL_ Kombi_PAG SG_ 253 ESP_QBit_v_Signal 1000;
BA_REL_ "GenSigTimeoutTime" BU_SG_REL_ Kombi_PAG SG_ 795 ESP_24_CRC 500;
BA_REL_ "GenSigTimeoutTime" BU_SG_REL_ Kombi_PAG SG_ 795 ESP_24_BZ 500;
BA_REL_ "GenSigTimeoutTime" BU_SG_REL_ Kombi_PAG SG_ 795 ESP_Lampe 500;
BA_REL_ "GenSigTimeoutTime" BU_SG_REL_ Kombi_PAG SG_ 795 ABS_Lampe 500;
BA_REL_ "GenSigTimeoutTime" BU_SG_REL_ Kombi_PAG SG_ 795 BK_Lampe_02 500;
BA_REL_ "GenSigTimeoutTime" BU_SG_REL_ Kombi_PAG SG_ 795 ESP_m_Raddrehz 500;
BA_REL_ "GenSigTimeoutTime" BU_SG_REL_ Kombi_PAG SG_ 795 ESP_Textanzeigen_03 500;
BA_REL_ "GenSigTimeoutTime" BU_SG_REL_ Kombi_PAG SG_ 795 ESP_Meldungen 500;
BA_REL_ "GenSigTimeoutTime" BU_SG_REL_ Kombi_PAG SG_ 795 ESP_Wegimp_VA 500;
BA_REL_ "GenSigTimeoutTime" BU_SG_REL_ Kombi_PAG SG_ 795 ESP_Fehlerstatus_Wegimp 500;
BA_REL_ "GenSigTimeoutTime" BU_SG_REL_ Kombi_PAG SG_ 795 ESP_Wegimp_Ueberlauf 500;
BA_REL_ "GenSigTimeoutTime" BU_SG_REL_ Kombi_PAG SG_ 795 ESP_HDC_Geschw_Farbe 500;
BA_REL_ "GenSigTimeoutTime" BU_SG_REL_ Kombi_PAG SG_ 795 ESP_Off_Lampe 500;
BA_REL_ "GenSigTimeoutTime" BU_SG_REL_ Kombi_PAG SG_ 795 ESP_HDC_Regelgeschw 500;
BA_REL_ "GenSigTimeoutTime" BU_SG_REL_ Kombi_PAG SG_ 795 ESP_BKV_Warnung 500;
BA_REL_ "GenSigTimeoutTime" BU_SG_REL_ Kombi_PAG SG_ 508 ESP_32_CRC 2000;
BA_REL_ "GenSigTimeoutTime" BU_SG_REL_ Kombi_PAG SG_ 508 ESP_32_BZ 2000;
BA_REL_ "GenSigTimeoutTime" BU_SG_REL_ Kombi_PAG SG_ 508 ESP_EDS_Anzeige 2000;
BA_REL_ "GenSigTimeoutTime" BU_SG_REL_ Kombi_PAG SG_ 508 RLE_Anzeigen 2000;
BA_REL_ "GenSigTimeoutTime" BU_SG_REL_ Kombi_PAG SG_ 508 ESC_FBA_Meldungen 2000;
BA_REL_ "GenSigTimeoutTime" BU_SG_REL_ Kombi_PAG SG_ 508 ESP_HDC_LED 2000;
BA_REL_ "GenSigTimeoutTime" BU_SG_REL_ Kombi_PAG SG_ 508 ESP_Offroad_Lampe 2000;
BA_REL_ "GenSigTimeoutTime" BU_SG_REL_ Kombi_PAG SG_ 508 ESP_HDC_Textanzeigen 2000;
BA_REL_ "GenSigTimeoutTime" BU_SG_REL_ Kombi_PAG SG_ 2589283470 ESC_Kilometer 5000;
BA_REL_ "GenSigTimeoutTime" BU_SG_REL_ Kombi_PAG SG_ 2589283470 ESC_Kilometer_MUX 5000;
BA_REL_ "GenSigTimeoutTime" BU_SG_REL_ Kombi_PAG SG_ 2589283470 ESC_Signatur_Kilometer_GFA_01 5000;
BA_REL_ "GenSigTimeoutTime" BU_SG_REL_ Kombi_PAG SG_ 2589283470 ESC_Signatur_Kilometer_IKA_01 5000;
BA_REL_ "GenSigTimeoutTime" BU_SG_REL_ Kombi_PAG SG_ 2589283470 ESC_Signatur_Kilometer_GFA_02 5000;
BA_REL_ "GenSigTimeoutTime" BU_SG_REL_ Kombi_PAG SG_ 2589283470 ESC_Signatur_Kilometer_IKA_02 5000;
BA_REL_ "GenSigTimeoutTime" BU_SG_REL_ Kombi_PAG SG_ 2527679662 ESC_Reku_Anzeige 1600;
BA_REL_ "GenSigTimeoutTime" BU_SG_REL_ Kombi_PAG SG_ 2527679662 ESC_Textanzeigen_SysSpez 1600;
BA_REL_ "GenSigTimeoutTime" BU_SG_REL_ Kombi_PAG SG_ 2527679824 Fahrwerk_14_CRC 3200;
BA_REL_ "GenSigTimeoutTime" BU_SG_REL_ Kombi_PAG SG_ 2527679824 Fahrwerk_14_BZ 3200;
BA_REL_ "GenSigTimeoutTime" BU_SG_REL_ Kombi_PAG SG_ 2527679824 PTLM_Warnung_2 3200;
BA_REL_ "GenSigTimeoutTime" BU_SG_REL_ Kombi_PAG SG_ 2527679824 EFP_WarnungBauteilschutz 3200;
BA_REL_ "GenSigTimeoutTime" BU_SG_REL_ Kombi_PAG SG_ 2527679824 EFP_WarnungAero 3200;
BA_REL_ "GenSigTimeoutTime" BU_SG_REL_ Kombi_PAG SG_ 2527679824 PTLM_vLimit 3200;
BA_REL_ "GenSigTimeoutTime" BU_SG_REL_ Kombi_PAG SG_ 2527679824 PTLM_Warnung 3200;
BA_REL_ "GenSigTimeoutTime" BU_SG_REL_ Kombi_PAG SG_ 705 Fahrwerk_Anzeige_01_CRC 800;
BA_REL_ "GenSigTimeoutTime" BU_SG_REL_ Kombi_PAG SG_ 705 Fahrwerk_Anzeige_01_BZ 800;
BA_REL_ "GenSigTimeoutTime" BU_SG_REL_ Kombi_PAG SG_ 705 EFP_Verbau_DR 800;
BA_REL_ "GenSigTimeoutTime" BU_SG_REL_ Kombi_PAG SG_ 705 EFP_Verbau_eAllrad 800;
BA_REL_ "GenSigTimeoutTime" BU_SG_REL_ Kombi_PAG SG_ 705 EFP_Verbau_LF 800;
BA_REL_ "GenSigTimeoutTime" BU_SG_REL_ Kombi_PAG SG_ 705 LF_Texte 800;
BA_REL_ "GenSigTimeoutTime" BU_SG_REL_ Kombi_PAG SG_ 705 EFP_Verbau_eAWS 800;
BA_REL_ "GenSigTimeoutTime" BU_SG_REL_ Kombi_PAG SG_ 705 eAWS_Warnmeldung_Prio1 800;
BA_REL_ "GenSigTimeoutTime" BU_SG_REL_ Kombi_PAG SG_ 705 eAWS_Warnmeldung_Prio2 800;
BA_REL_ "GenSigTimeoutTime" BU_SG_REL_ Kombi_PAG SG_ 705 LF_Texte_2 800;
BA_REL_ "GenSigTimeoutTime" BU_SG_REL_ Kombi_PAG SG_ 705 EFP_Status_Taster_Lift 800;
BA_REL_ "GenSigTimeoutTime" BU_SG_REL_ Kombi_PAG SG_ 705 EFP_Status_Taster_Fahrwerk 800;
BA_REL_ "GenSigTimeoutTime" BU_SG_REL_ Kombi_PAG SG_ 705 FDR_Warnung_ALR 800;
BA_REL_ "GenSigTimeoutTime" BU_SG_REL_ Kombi_PAG SG_ 705 LF_Warnung_Prio1_02 800;
BA_REL_ "GenSigTimeoutTime" BU_SG_REL_ Kombi_PAG SG_ 705 LF_Warnung_Prio2 800;
BA_REL_ "GenSigTimeoutTime" BU_SG_REL_ Kombi_PAG SG_ 705 DR_Warnung 800;
BA_REL_ "GenSigTimeoutTime" BU_SG_REL_ Kombi_PAG SG_ 705 EFP_Warnung_Naesse 800;
BA_REL_ "GenSigTimeoutTime" BU_SG_REL_ Kombi_PAG SG_ 705 EFP_Warnung_Naesse_verf 800;
BA_REL_ "GenSigTimeoutTime" BU_SG_REL_ Waehlhebel_SB SG_ 1520 DI_KL_58xd 2000;
BA_REL_ "GenSigTimeoutTime" BU_SG_REL_ Waehlhebel_SB SG_ 1520 DI_KL_58xt 2000;
BA_REL_ "GenSigTimeoutTime" BU_SG_REL_ Waehlhebel_SB SG_ 253 ESP_21_CRC 1000;
BA_REL_ "GenSigTimeoutTime" BU_SG_REL_ Waehlhebel_SB SG_ 253 ESP_21_BZ 1000;
BA_REL_ "GenSigTimeoutTime" BU_SG_REL_ Waehlhebel_SB SG_ 253 ESP_v_Signal 1000;
BA_REL_ "GenSigTimeoutTime" BU_SG_REL_ Waehlhebel_SB SG_ 253 ESP_QBit_v_Signal 1000;
VAL_ 1520 DI_KL_58xd 254 "Init" 255 "Fehler" ;
VAL_ 1520 DI_KL_58xs 126 "Init" 127 "Fehler" ;
VAL_ 1520 DI_KL_58xt 126 "Init" 127 "Fehler" ;
VAL_ 1520 BCM1_Stellgroesse_Kl_58s 125 "Nicht_verbaut" 126 "Init" 127 "Fehler" ;
VAL_ 2527679773 DLM_BFS_GenericFail 0 "No_fault" 1 "Fault" ;
VAL_ 2527679773 DLM_BFS_SystemError 0 "Init" 1 "No_fault" 2 "Peripheral_fail" 3 "SuperCap_supply" 4 "Internal_fail" 7 "Fehler" ;
VAL_ 2527679773 DLM_BFS_SwitchRequest 0 "None" 1 "No_unlatch" 2 "Single_pull" 3 "Wait_for_second_press" 4 "Aborted_double_pull" 5 "Double_pull" 7 "Fehler" ;
VAL_ 2527679773 DLM_BFS_WDSMStatus 0 "Nominal" 1 "Discharged" 2 "Life_cycle_expired" 3 "Fehler" ;
VAL_ 2527679773 DLM_BFS_WDSMTrigger 0 "Not_active" 1 "Active" ;
VAL_ 2527679773 DLM_BFS_ProductionMode 0 "Not_active" 1 "Active" ;
VAL_ 2527679773 DLM_BFS_DoorStatus 0 "Init" 1 "Invalid" 2 "Door_open" 3 "Door_ajar" 4 "Door_closed" 7 "Fehler" ;
VAL_ 2527679773 DLM_BFS_LatchStatusFeedbac 0 "Init" 1 "Invalid" 2 "Unlock" 3 "Lock" 4 "Safe" 7 "Fehler" ;
VAL_ 2527679773 DLM_BFS_SuperCapStatus 0 "No_fault" 1 "Limited_performances" 2 "Discharge_level" 3 "Fehler" ;
VAL_ 2527679773 DLM_BFS_WDSMActuationsBFS 511 "init" ;
VAL_ 2527679773 DLM_BFS_WDSMActuationsResetTrig 0 "init" 1 "reset" ;
VAL_ 2527679773 DLM_BFS_HeartbeatCnt 0 "Init" ;
VAL_ 2527679772 DLM_FS_GenericFailure 0 "No_fault" 1 "Fault" ;
VAL_ 2527679772 DLM_FS_SystemError 0 "Init" 1 "No_fault" 2 "Peripheral_fail" 3 "SuperCap_supply" 4 "Internal_fail" 7 "Fehler" ;
VAL_ 2527679772 DLM_FS_SwitchRequest 0 "None" 1 "No_unlatch" 2 "Single_pull" 3 "Wait_for_second_press" 4 "Aborted_double_pull" 5 "Double_pull" 7 "Fehler" ;
VAL_ 2527679772 DLM_FS_WDSMStatus 0 "Nominal" 1 "Discharged" 2 "Life_cycle_expired" 3 "Fehler" ;
VAL_ 2527679772 DLM_FS_WDSMTrigger 0 "Not_active" 1 "Active" ;
VAL_ 2527679772 DLM_FS_ProductionMode 0 "Not_active" 1 "Active" ;
VAL_ 2527679772 DLM_FS_DoorStatus 0 "Init" 1 "Invalid" 2 "Door_open" 3 "Door_ajar" 4 "Door_closed" 7 "Fehler" ;
VAL_ 2527679772 DLM_FS_LatchStatusFeedback 0 "Init" 1 "Invalid" 2 "Unlock" 3 "Lock" 4 "Safe" 7 "Fehler" ;
VAL_ 2527679772 DLM_FS_SuperCapStatus 0 "No_fault" 1 "Limited_performances" 2 "Discharge_level" 3 "Fehler" ;
VAL_ 2527679772 DLM_FS_WDSMActuationsFS 511 "init" ;
VAL_ 2527679772 DLM_FS_WDSMActuationsResetTrig 0 "init" 1 "Reset" ;
VAL_ 496 EA_Texte 0 "keine_Anzeige" 1 "Nothalteassistent_fehlende_Fahreraktivitaet" 2 "Nothalteassistent_aktiv_Fahrzeugfuehrung_uebernehmen" 3 "Nothalteassistent_automatischer_Nothalt_wird_durchgefuehrt" 4 "Nothalteassistent_automatischer_Nothalt_durchgefuehrt" 5 "Nothalteassistent_Verbindung_zum_Notruf_wird_aufgebaut" 6 "Nothalteassistent_deaktiviert" 7 "Nothalteassistent_Eingriff_abgebrochen" 8 "Nothalteassistent_fehlende_Fahreraktivitaet_2" 9 "Sekundenschlaf_erkannt" 10 "LaneAssist_Lenkung_uebernehmen" 11 "ACA_Fahrzeugfuehrung_uebernehmen" 12 "EA_Fahr_Standstreifenwechsel" 14 "Nothalteassistent_nicht_verfuegbar_reversibel" 15 "Nothalteassistent_Stoerung_irreversibel" ;
VAL_ 496 ACF_Lampe_Hands_Off 0 "keine_Anzeige" 1 "Hands_Off_erkannt" ;
VAL_ 496 EA_Infotainment_Anf 0 "Init" 1 "Keine_Absenkung" 2 "Absenkung" 3 "Mute" ;
VAL_ 496 EA_Tueren_Anf 0 "Keine_Anforderung" 1 "Tueren_entriegeln" ;
VAL_ 496 EA_Innenraumlicht_Anf 0 "Innenraumbeleuchtung_ausschalten" 1 "Innenraumbeleuchtung_einschalten" ;
VAL_ 496 zFAS_Warnblinken 0 "Aus" 1 "Statisch" 2 "Taster" 3 "Statisch_ohne_WBT" ;
VAL_ 496 STP_Primaeranz 0 "keine_Anzeige" 1 "Verfuegbar" 2 "Aktiv" 3 "Uebernahme" 4 "Aktiv_Warnung" 5 "Nicht_Verfuegbar" ;
VAL_ 496 EA_Bremslichtblinken 0 "kein_Blinken" 1 "Anforderung_Bremslichtblinken" ;
VAL_ 496 EA_Blinken 0 "Kein_Blinken" 1 "Wechselblinken_links" 2 "Wechselblinken_rechts" 3 "Warnblinken" 4 "Warnblinken_Taster" ;
VAL_ 496 EA_Status_HMI 0 "Keine_Anzeige" 1 "Aktiv_quer_laengs" 2 "Aktiv_laengs" ;
VAL_ 2527679980 eCall_Statuslicht_Farbe2 0 "Aus" 1 "Blinken_1" 2 "Blinken_2" 3 "An" ;
VAL_ 2527679980 eCall_Statuslicht_Farbe1 0 "Aus" 1 "Blinken_1" 2 "Blinken_2" 3 "An" ;
VAL_ 2527679980 bCall_active 0 "bcall_inactive" 1 "bcall_active" ;
VAL_ 2527679980 eCall_Funktionsstatus 0 "kein_Fehler" 1 "Fkt_eingeschraenkt" 2 "Fkt_eingeschraenkt_service" 3 "Fkt_nicht_verfuegbar" 4 "Fkt_Service" 5 "Fkt_deaktiviert" 6 "Fkt_aktiviert" 7 "init" ;
VAL_ 2527679980 eCall_Subscription 0 "Init" 1 "unsubscribed" 2 "subscribed" ;
VAL_ 2527679980 eCall_Funktionsstatus_02 0 "kein_Fehler" 1 "Manueller_Notruf_aktiv" 2 "Automatischer_Notruf_aktiv" 7 "Init" ;
VAL_ 2527679980 eCall_Mute_Anf 0 "kein_mute" 1 "mute" ;
VAL_ 996 EFF_Verbraucher_Balken 510 "Init" 511 "Fehler" ;
VAL_ 996 EFF_Verbraucher_Pos_1 0 "keine_Anzeige" 1 "Klimaautomatik" 2 "Standheizung" 3 "Heckscheibe" 4 "Sitzheizung_links" 5 "Sitzheizung_rechts" 6 "Sitzlueftung_links" 7 "Sitzlueftung_rechts" 8 "Nackenheizung_links" 9 "Nackenheizung_rechts" 10 "Nebellicht_vorne" 11 "Nebelschlussleuchte" 12 "Frontscheibenheizung" 13 "Lenkradheizung" 14 "Spiegelheizung" 15 "Sitzheizung_hinten" 16 "Sitzlueftung_hinten" ;
VAL_ 996 EFF_Verbraucher_Pos_2 0 "keine_Anzeige" 1 "Klimaautomatik" 2 "Standheizung" 3 "Heckscheibe" 4 "Sitzheizung_links" 5 "Sitzheizung_rechts" 6 "Sitzlueftung_links" 7 "Sitzlueftung_rechts" 8 "Nackenheizung_links" 9 "Nackenheizung_rechts" 10 "Nebellicht_vorne" 11 "Nebelschlussleuchte" 12 "Frontscheibenheizung" 13 "Lenkradheizung" 14 "Spiegelheizung" 15 "Sitzheizung_hinten" 16 "Sitzlueftung_hinten" ;
VAL_ 996 EFF_Verbraucher_Pos_3 0 "keine_Anzeige" 1 "Klimaautomatik" 2 "Standheizung" 3 "Heckscheibe" 4 "Sitzheizung_links" 5 "Sitzheizung_rechts" 6 "Sitzlueftung_links" 7 "Sitzlueftung_rechts" 8 "Nackenheizung_links" 9 "Nackenheizung_rechts" 10 "Nebellicht_vorne" 11 "Nebelschlussleuchte" 12 "Frontscheibenheizung" 13 "Lenkradheizung" 14 "Spiegelheizung" 15 "Sitzheizung_hinten" 16 "Sitzlueftung_hinten" ;
VAL_ 996 EFF_Einsparhinweis 0 "Init" 1 "Erhoehter_Luftwiderst_Fenster" 2 "Erhoehter_Luftwiderst_Schiebedach" 3 "Erhoehter_Luftwiderst_Fenst_Schiebed" 4 "Nutzung_Motorbremse" 5 "Gaspedal_bei_Motorstart" 6 "Schaltanzeige_beachten" 7 "StartStop_nutzen" 8 "StartStop_einschalten" 9 "Ineff_Betrieb_Klima_Fenster" 10 "Ineff_Betrieb_Klima_Schiebedach" 11 "Ineff_Betrieb_Klima_Fenst_Schiebed" 12 "Fahrstufe_D_verwenden" 13 "Gaspedal_im_Stand" ;
VAL_ 996 EFF_Verbrauch_STH 127 "Fehler" ;
VAL_ 996 MKE_Texte 0 "keine_Anzeige" 1 "Warnstufe_1" 2 "Warnstufe_2" ;
VAL_ 996 MKE_FAS 0 "keine_Anzeige" 1 "Warnstufe_1" 2 "Warnstufe_2" ;
VAL_ 996 MKE_Stufe 0 "deaktiviert" 1 "nicht_verfügbar" 2 "Stufe_1" 3 "Stufe_2" 4 "Stufe_3" 5 "Stufe_4" 6 "reserviert" 7 "reserviert" ;
VAL_ 996 MKE_FAS_Fkt_Status 0 "Init" 1 "Funktion_Ist_Ein" 2 "Funktion_Ist_Aus" 3 "Fehler" ;
VAL_ 996 MKE_Fehlercode 0 "Init" 1 "gueltig" 2 "eingeschraenkt_gueltig" 3 "ungueltig" 4 "nicht_verbaut" ;
VAL_ 1603 KBI_Einheit_Datum 0 "Tag/Monat/Jahr" 1 "Monat/Tag/Jahr" 2 "Jahr/Monat/Tag" 3 "reserviert" ;
VAL_ 1603 KBI_Einheit_Druck 0 "Druckangabe in bar" 1 "Druckangabe in psi" 2 "Druckangabe in kPa" 3 "tbd." ;
VAL_ 1603 KBI_Einheit_Streckenanz 0 "Kilometer" 1 "Meilen" ;
VAL_ 1603 KBI_MFA_v_Einheit_02 0 "kmh" 1 "mph" ;
VAL_ 1603 KBI_Einheit_Temp 0 "Grad Celsius °C" 1 "Grad Fahrenheit °F" ;
VAL_ 1603 KBI_Einheit_Uhrzeit 0 "24h" 1 " 12h AM/PM" ;
VAL_ 1603 KBI_Einheit_Verbrauch 0 "mpg UK" 1 "mpg USA" 2 "Liter/100km" 3 "km/Liter" ;
VAL_ 1603 KBI_Einheit_Volumen 0 "Liter" 1 "Gallonen UK" 2 "Gallonen USA" 3 "reserviert" ;
VAL_ 1603 KBI_Einheit_Verbrauch_elektr 0 "kWh_pro_100km" 1 "km_pro_kWh" 2 "kWh_pro_100mls" 3 "mls_pro_kWh" 4 "MPGe" ;
VAL_ 1603 KBI_Einheit_Verbrauch_Gas 0 "kg_per_100km" 1 "km_per_kg" 2 "m3_per_100km" 3 "km_per_m3" 4 "miles_per_lbs" 5 "miles_per_yard3" 6 "miles_per_kg" 7 "miles_per_m3" 8 "miles_per_gallon_equivalent_US" ;
VAL_ 1603 KBI_Einheit_Masse 0 "kg" 1 "lbs" 2 "reserviert" ;
VAL_ 1622 ELV_Anf_Klemme_S 0 "Aus" 1 "Ein" ;
VAL_ 1622 ELV_Anf_Klemme_15 0 "Aus" 1 "Ein" ;
VAL_ 1622 ELV_Anf_Klemme_50 0 "Aus" 1 "Ein" ;
VAL_ 1622 ELV_01_Sendestatus 0 "ELV_sendet_mit_1000ms" 1 "ELV_sendet_mit_50ms" ;
VAL_ 1622 ELV_Verriegelt 0 "nicht_verriegelt" 1 "verriegelt" ;
VAL_ 1622 ELV_Entriegelt 0 "ELV_nicht_entriegelt" 1 "ELV_entriegelt" ;
VAL_ 1622 ELV_ZAT_betaetigt 0 "nicht_betaetigt" 1 "betaetigt" ;
VAL_ 1622 ELV_Lebenszustand 0 "Lebenszustand_0" 1 "Lebenszustand_4" ;
VAL_ 1622 ELV_Anlernmodus 0 "Normalbetrieb" 1 "Anlernmodus" ;
VAL_ 1622 ELV_Klemmenfreigabe 0 "keine_Freigabe" 1 "Freigabe" ;
VAL_ 1622 ELV_Abbruch_Anf_Klemmenfreigabe 0 "kein_Abbruch" 1 "Abbruch" ;
VAL_ 1622 ELV_LED_Rot 0 "Aus" 1 "Ein" ;
VAL_ 1622 ELV_LED_Gelb 0 "Aus" 1 "Ein" ;
VAL_ 1622 ELV_Txt_Panikabschaltung 0 "Aus" 1 "Ein" ;
VAL_ 1622 ELV_Txt_Lkg_Bewegen 0 "Aus" 1 "Ein" ;
VAL_ 1622 ELV_Txt_Werkstatt 0 "Aus" 1 "Ein" ;
VAL_ 1622 ELV_Txt_Defekt 0 "Aus" 1 "Ein" ;
VAL_ 1622 ELV_Txt_P_Gang 0 "Aus" 1 "Ein" ;
VAL_ 1622 ELV_Txt_PN_Gang 0 "Aus" 1 "Ein" ;
VAL_ 1622 ELV_Txt_Kupplung 0 "Aus" 1 "Ein" ;
VAL_ 1622 ELV_Txt_Bremse 0 "Aus" 1 "Ein" ;
VAL_ 1622 ELV_P_verriegelt 0 "nicht_verriegelt" 1 "verriegelt" ;
VAL_ 2589283649 EML_ReifenKorrFaktorHL 510 "Init" 511 "Fehler" ;
VAL_ 2589283649 EML_ReifenKorrFaktorHR 510 "Init" 511 "Fehler" ;
VAL_ 2589283649 EML_ReifenKorrFaktorVL 510 "Init" 511 "Fehler" ;
VAL_ 2589283649 EML_ReifenKorrFaktorVR 510 "Init" 511 "Fehler" ;
VAL_ 260 EPB_QBit_Pedalweg_Kuppl 0 "gültiger Wert" 1 "Ersatz-, Init- oder Fehlerwert" ;
VAL_ 260 EPB_Freig_Verzoeg_Anf 0 "nicht freigegeben" 1 "freigegeben" ;
VAL_ 260 EPB_Pedalweg_Kuppl 0 "Init" 255 "Fehler" ;
VAL_ 260 EPB_DAA_Randbed_erf 0 "Randbed_nicht_erfuellt" 1 "Randbed_erfuellt" ;
VAL_ 260 EPB_Fehlerstatus_02 0 "kein_Fehler" 1 "Fehler_ausserhalb_apply_release" 2 "Fehler_einseitig_apply_release" 3 "Fehler_beidseitig_apply_release" ;
VAL_ 260 EPB_Schalterposition 0 "keine Fahreranforderung" 1 "Fahreranforderung Öffnen" 2 "Fahreranforderung Schließen" 3 "Fehler" ;
VAL_ 260 EPB_QBit_Schalterpos 0 "gültiger Wert (volle Funktion)" 1 " Ersatz-, Init- oder Fehlerwert (Schalter ausser Funktion)" ;
VAL_ 260 EPB_Spannkraft 30 "Init" 31 "Fehler" ;
VAL_ 260 EPB_Status_02 0 "offen" 1 "geschlossen_Parken" 2 "teilgespannt_Halten" 3 "im_Lauf_oeffnen" 4 "im_Lauf_schliessen" 5 "tbd" 6 "Init" 7 "unbekannt" ;
VAL_ 781 EPB_Fehlerlampe_Gelb 0 "Aus" 1 "Ein" ;
VAL_ 781 EPB_Fehlerlampe_BKL 0 "BKL aus" 1 "BKL an" ;
VAL_ 781 EPB_Funktionslampe 0 "Aus" 1 "Ein" ;
VAL_ 781 EPB_Texte 0 "keine_Anzeige" 1 "Neigungswinkel_zu_gross" 2 "Parkbremse_von_Hand_oeffnen" 3 "HU_Modus_oder_EPB_in_Diagnose" 4 "Bremspedal_betaetigen" 5 "tbd" 6 "tbd" 7 "Stoerung_Anfahrassistent" 8 "Motor_starten" 9 "Feststellbremse_nicht_automatisch_geschlossen" 10 "Parkbremse_loesen_nicht_moeglich_Ladekabel_gesteckt" 11 "Notbremsung_ueber_EPB_Taster" 12 "Parkbremse_angezogen" 13 "Parkbremse_loesen_nicht_moeglich_ParkPilot_aktiv" ;
VAL_ 781 EPB_Akustik 0 "Warnton aus" 1 "Warnton an" ;
VAL_ 781 EPB_Autoholdlampe 0 "Lampe aus (Autohold inaktiv)" 1 "Lampe ein (Autohold aktiv)" ;
VAL_ 781 EPB_Bremsbelag_Warn 0 "Bremsbelag_ok" 1 "Bremsbelag_unter_Minimum" ;
VAL_ 781 EPB_Fehlermeldungen 0 "keine_Anzeige" 1 "Systemstoerung_Kl15an" 2 "Systemstoerung_Kl15aus" 3 "Parkbremse_betaetigen" 4 "Systemstoerung_Hanghaltefaehigkeit" 5 "Funktionseinschraenkung_Kl15an" 6 "Funktionseinschraenkung_Kl15aus" 7 "HU_Modus_aktiv" 8 "Transportmodus" 9 "Produktionsmodus" 10 "FktEinschr_Taster_defekt" ;
VAL_ 503 EPB_Texte_02 0 "keine_Anzeige" 1 "Neigungswinkel_zu_gross" 2 "Parkbremse_von_Hand_oeffnen" 3 "HU_Modus_oder_EPB_in_Diagnose" 4 "Bremspedal_betaetigen" 5 "EPB_durch_Fahrstufe_loesen" 6 "tbd" 7 "Stoerung_Anfahrassistent" 8 "Motor_starten" 9 "Feststellbremse_nicht_automatisch_geschlossen" 10 "Parkbremse_loesen_nicht_moeglich_Ladekabel_gesteckt" 11 "Notbremsung_ueber_EPB_Taster" 12 "Parkbremse_angezogen" 13 "Parkbremse_loesen_nicht_moeglich_ParkPilot_aktiv" ;
VAL_ 503 EPB_Fehlermeldungen_02 0 "keine_Anzeige" 1 "Systemstoerung_Kl15an" 2 "Systemstoerung_Kl15aus" 3 "Parkbremse_betaetigen" 4 "Systemstoerung_Hanghaltefaehigkeit" 5 "Funktionseinschraenkung_Kl15an" 6 "Funktionseinschraenkung_Kl15aus" 7 "HU_Modus_aktiv" 8 "Transportmodus" 9 "Produktionsmodus" 10 "FktEinschr_Taster_defekt" 11 "Funktionseinschraenkung_Hanghalt" ;
VAL_ 503 EPB_Funktionslampe_02 0 "Aus" 1 "Ein" ;
VAL_ 503 EPB_Autoholdlampe_02 0 "Lampe aus (Autohold inaktiv)" 1 "Lampe ein (Autohold aktiv)" ;
VAL_ 262 ESP_QBit_Bremsdruck 0 "gueltiger_Wert" 1 "Ersatz_Init_oder_Fehlerwert" ;
VAL_ 262 ESP_QBit_Fahrer_bremst 0 "gueltiger_Wert" 1 "Ersatz_Init_oder_Fehlerwert" ;
VAL_ 262 ESP_Schwelle_Unterdruck 0 "kein_Signal" 1 "Unterdruck_kleiner_gleich_450_mbar" 2 "Unterdruck_groesser_450_mbar" 3 "Fehler_Unterdrucksensor" ;
VAL_ 262 ESP_Bremsdruck 1023 "Fehler" ;
VAL_ 262 ESP_Fahrer_bremst 0 "Bremsdruckschwelle_nicht_ueberschritten" 1 "Bremsdruckschwelle_ueberschritten" ;
VAL_ 262 ESP_Lenkeingriff_ADS 0 "kein_Lenkeingriff" 1 "stabilisierender_Lenkeingriff" ;
VAL_ 262 ECD_Fehler 0 "ECD_iO" 1 "ECD_Fehler" ;
VAL_ 262 ECD_nicht_verfuegbar 0 "ECD_Funktion_verfuegbar" 1 "ECD_Funktion_nicht_verfuegbar" ;
VAL_ 262 ESP_Status_Bremsentemp 0 "Bremse_nicht_ueberhitzt" 1 "Bremse_ueberhitzt" ;
VAL_ 262 ESP_Autohold_Standby 0 "Autohold_nicht_im_Standby" 1 "Autohold_im_Standby" ;
VAL_ 262 ESP_HDC_Standby 0 "HDC_Funktion_nicht_im_Standby" 1 "HDC_Funktion_im_Standby" ;
VAL_ 262 ESP_HBA_aktiv 0 "HBA_nicht_aktiv" 1 "HBA_aktiv" ;
VAL_ 262 ESP_Prefill_ausgeloest 0 "nicht_ausgeloest" 1 "Prefill_ausgeloest" ;
VAL_ 262 ESP_Rueckwaertsfahrt_erkannt 0 "keine_Rueckwaetsfahrt" 1 "Rueckwaertsfahrt_sicher_erkannt" ;
VAL_ 262 ESP_Status_Anfahrhilfe 0 "Aus" 1 "Ein" ;
VAL_ 262 ESP_HDC_aktiv 0 "inaktiv" 1 "aktiv" ;
VAL_ 262 ESP_StartStopp_Info 0 "Motorlauf_nicht_notwendig_(Stoppfreigabe)" 1 "Motoranlauf_nicht_zwingend_notwendig_(Stoppverbot,keine_Startanforderung)" 2 "Motoranlauf_zwingend_notwendig_(Startanforderung)" 3 "Systemfehler" ;
VAL_ 262 ESP_Eingr_HL 0 "kein_Eingriff" 1 "ESP_Eingriff_HL" ;
VAL_ 262 ESP_Eingr_HR 0 "kein_Eingriff" 1 "ESP_Eingriff_HR" ;
VAL_ 262 ESP_Eingr_VL 0 "kein_Eingriff" 1 "ESP_Eingriff_VL" ;
VAL_ 262 ESP_Eingr_VR 0 "kein_Eingriff" 1 "ESP_Eingriff_VR" ;
VAL_ 262 ESP_BKV_Unterdruck 0 "nicht_verbaut_oder_nicht_kodiert" 254 "Init" 255 "Fehler" ;
VAL_ 262 ESP_Autohold_aktiv 0 "Autohold_inaktiv" 1 "Autohold_aktiv" ;
VAL_ 262 ESP_FStatus_Anfahrhilfe 0 "kein_Fehler" 1 "Fehler" ;
VAL_ 262 ESP_Verz_EPB_aktiv 0 "nicht_aktiviert" 1 "aktiviert" ;
VAL_ 262 ESC_Bremslicht 0 "Aus" 1 "Ein" ;
VAL_ 262 ESP_Verzoeg_EPB_verf 0 "nicht_verfuegbar" 1 "System_verfuegbar" ;
VAL_ 262 ESP_Status_Bremsdruck 0 "Bremse_drucklos" 1 "mit_Bremsdruck" ;
VAL_ 262 ESP_Anforderung_EPB 0 "keine_Anforderung" 1 "Anforderung_Oeffnen" 2 "Anforderung_Schliessen" 3 "reserviert" ;
VAL_ 1629 BR_Systemart 0 "ABS" 1 "ABS_ASR" 2 "ESP" 3 "ESP_mit_integrierter_EPB" ;
VAL_ 1629 ESP_SpannungsAnf_02 0 "keine_Anforderung" 1 "Anforderung_Stufe1" 2 "Anforderung_Stufe2" 3 "Anforderung_Stufe3" ;
VAL_ 1629 ESP_Charisma_FahrPr 0 "keine_Funktion" 1 "Programm_1" 2 "Programm_2" 3 "Programm_3" 4 "Programm_4" 5 "Programm_5" 6 "Programm_6" 7 "Programm_7" 8 "Programm_8" 9 "Programm_9" 10 "Programm_10" 11 "Programm_11" 12 "Programm_12" 13 "Programm_13" 14 "Programm_14" 15 "Programm_15" ;
VAL_ 1629 ESP_Charisma_Status 0 "Init" 1 "verfuegbar" 2 "nicht_verfuegbar" 3 "asynchron_durch_Fahrerwunsch" ;
VAL_ 1629 ESP_Wiederstart_Anz_01 0 "keine_Anzeige" 1 "Rueckwaertsrollen" ;
VAL_ 1629 ESP_Wiederstart_Anz_02 0 "keine_Anzeige" 1 "Autohold_Rutschen" ;
VAL_ 1629 ESP_Wiederstart_Anz_03 0 "keine_Anzeige" 1 "Offroad_HDC" ;
VAL_ 1629 ESP_Wiederstart_Anz_04 0 "keine_Anzeige" 1 "ESC_Off" ;
VAL_ 1629 ESP_Stoppverbot_Anz_01 0 "keine_Anzeige" 1 "Notbremsung_aktiv" ;
VAL_ 1629 ESP_Stoppverbot_Anz_02 0 "keine_Anzeige" 1 "Autohold_AVH_Rutschen" ;
VAL_ 1629 ESP_Stoppverbot_Anz_03 0 "keine_Anzeige" 1 "Rueckwaertsrollen" ;
VAL_ 1629 ESP_Stoppverbot_Anz_04 0 "keine_Anzeige" 1 "ESP_Pumpenlauf" ;
VAL_ 1629 ESP_Stoppverbot_Anz_05 0 "keine_Anzeige" 1 "ESP_OFF" ;
VAL_ 1629 ESP_Stoppverbot_Anz_06 0 "keine_Anzeige" 1 "Offroad_HDC" ;
VAL_ 1629 ESP_Stoppverbot_Anz_07 0 "keine_Anzeige" 1 "ESP_Haltefunktion_nicht_verfuegbar" ;
VAL_ 1629 ESP_Stoppverbot_Anz_Std 0 "keine_Anzeige" 1 "Standard_Stoppvetogrund" ;
VAL_ 1629 ESP_Dachrelingsensor 0 "Sensor_nicht_verbaut" 1 "Quertraeger_montiert" 2 "Quertraeger_nicht_montiert" 3 "Fehler" ;
VAL_ 1629 ESP_Stoppverbot_Anz_08 0 "keine_Anzeige" 1 "Neigungsbegrenzung" ;
VAL_ 1629 HDC_Charisma_FahrPr 0 "keine_Funktion" 1 "Programm_1" 2 "Programm_2" 3 "Programm_3" 4 "Programm_4" 5 "Programm_5" 6 "Programm_6" 7 "Programm_7" 8 "Programm_8" 9 "Programm_9" 10 "Programm_10" 11 "Programm_11" 12 "Programm_12" 13 "Programm_13" 14 "Programm_14" 15 "Programm_15" ;
VAL_ 1629 HDC_Charisma_Status 0 "Init" 1 "verfuegbar" 2 "nicht_verfuegbar" 3 "asynchron_durch_Fahrerwunsch" ;
VAL_ 1629 BR_QBit_Reifenumfang 0 "gueltiger_Wert" 1 "Ersatz_Init_oder_Fehlerwert" ;
VAL_ 253 BR_Eingriffsmoment 1022 "Init" 1023 "Fehler" ;
VAL_ 253 MSR_verfuegbar 0 "verfuegbar" 1 "nicht_verfuegbar" ;
VAL_ 253 ESP_Diagnose 0 "ESP_nicht_in_Diagnose" 1 "ESP_in_Diagnose" ;
VAL_ 253 ESC_v_Signal_Qualifier_High_Low 0 "Gueteschwelle_kleiner_1kmh" 1 "Gueteschwelle_kleiner_3kmh" 2 "Gueteschwelle_kleiner_5kmh" 3 "Gueteschwelle_kleiner_10kmh" 4 "Gueteschwelle_kleiner_20kmh" 5 "Gueteschwelle_groessergleich_20kmh" 6 "Init" 7 "Fehler" ;
VAL_ 253 ESP_Vorsteuerung 0 "keine_Vorsteuerung_aktiv" 1 "Vorsteuerung_aktiv" ;
VAL_ 253 OBD_Schlechtweg 0 "kein_Schlechtweg_erkannt" 1 "Schlechtweg_erkannt" ;
VAL_ 253 OBD_QBit_Schlechtweg 0 "gueltiger_Wert" 1 "Ersatz_Init_oder_Fehlerwert" ;
VAL_ 253 ESP_v_Signal 65533 "Unterspannung" 65534 "Init" 65535 "Fehler" ;
VAL_ 253 ASR_Tastung_passiv 0 "ASR_aktiviert" 1 "ASR_passiv_getastet_oder_Schwellen_geaendert" ;
VAL_ 253 ESP_Tastung_passiv 0 "ESP_aktiviert" 1 "ESP_passiv_getastet_oder_Schwellen_geaendert" ;
VAL_ 253 ESP_Systemstatus 0 "iO" 1 "Fehler" ;
VAL_ 253 ASR_Schalteingriff 0 "keine_Anforderung" 1 "ASR_Schaltkennfeld" 2 "Rueckschaltung" 3 "Schaltverbot" ;
VAL_ 253 ESP_QBit_v_Signal 0 "gueltiger_Wert" 1 "Ersatz_Init_oder_Fehlerwert" ;
VAL_ 253 ABS_Bremsung 0 "keine_ABS_Regelung" 1 "ABS_Regelung_aktiv" ;
VAL_ 253 ASR_Anf 0 "keine_Anforderung" 1 "ASR_Anforderung" ;
VAL_ 253 MSR_Anf 0 "keine Anfoderung" 1 "MSR-Anforderung" ;
VAL_ 253 EBV_Eingriff 0 "kein_EBV_Eingriff" 1 "EBV_Eingriff" ;
VAL_ 253 EDS_Eingriff 0 "kein_EDS_Eingriff" 1 "EDS_Eingriff" ;
VAL_ 253 ESP_Eingriff 0 "kein_ESP_Eingriff" 1 "ESP_Eingriff_aktiv" ;
VAL_ 253 ESP_ASP 0 "inaktiv" 1 "aktiv" ;
VAL_ 253 ESC_Neutralschaltung 0 "keine_Anforderung" 1 "Neutralschaltung_angefordert" ;
VAL_ 1470 ESP_Gierrate_Offset_2 2046 "Init" 2047 "Fehler" ;
VAL_ 1470 ESP_Lenkwinkel_Offset 510 "Init" 511 "Fehler" ;
VAL_ 1470 BR_QBit_Reifenumfang_sekundaer 0 "gueltiger_Wert" 1 "Ersatz_Init_oder_Fehlerwert" ;
VAL_ 1470 ESP_Status_Bremsentemp_Anz 0 "Init" 1 "kalt" 2 "warm" 3 "heiss" 4 "ueberhitzt" 5 "nass" 7 "Fehler" ;
VAL_ 1470 ESP_Querbeschleunigung_Offset 62 "Init" 63 "Fehler" ;
VAL_ 1470 ESP_Laengsbeschleunigung_Offset 254 "Init" 255 "Fehler" ;
VAL_ 795 ESP_Lampe 0 "Aus" 1 "Ein" ;
VAL_ 795 ABS_Lampe 0 "Aus" 1 "Ein" ;
VAL_ 795 BK_Lampe_02 0 "aus" 1 "Typ1_ein_statisch" 2 "Typ2_ein_statisch" 3 "Warnung" ;
VAL_ 795 TC_Lampe 0 "Aus" 1 "Ein" ;
VAL_ 795 ESP_m_Raddrehz 32765 "Unterspannung" 32766 "Init" 32767 "Fehler" ;
VAL_ 795 ESP_Textanzeigen_03 0 "kein_Text" 1 "ESP_Stoerung" 2 "ABS_Stoerung" 3 "ESP_ABS_Stoerung" 4 "Werkstatt_Bremse" 5 "ASR_Stoerung" 6 "ESP_switched_off" 7 "ASR_off" 8 "ESP_ASR_on" 10 "keine_Bremskraftverstaerkung" 11 "ASR_aktiviert" 12 "ABS_ASR_Stoerung" 15 "ESP_offroad" 17 "ESP_sport" 18 "ESP_Zwangsaktivierung" 19 "ESP_Taster_Info" 20 "TC_aktiv" 21 "reserviert_fuer_Verlwarn" 22 "TC_switched_off" 23 "Verlwarn_akt_Rollsicher_inakt" 24 "ESP_SuperSport" 25 "ESP_Offroad_nicht_verfuegbar" ;
VAL_ 795 ESP_Meldungen 0 "keine_Anzeige" 1 "Autohold_Hinweis_1" 2 "Stoerung_Autohold" 3 "Stoerung_Hillholder" 4 "Uebernehmen" 5 "Autohold_aus" 6 "Autohold_Hinweis_2" ;
VAL_ 795 ESP_Fehlerstatus_Wegimp 0 "Wegimpulse_iO" 1 "Fehler" ;
VAL_ 795 ESP_Wegimp_Ueberlauf 0 "Reset_und_kein_Ueberlauf" 1 "mindestens_1x_Ueberlauf" ;
VAL_ 795 ESP_QBit_Wegimp_VA 0 "gueltiger_Wert" 1 "Ersatz_Init_oder_Fehlerwert" ;
VAL_ 795 ESP_HDC_Geschw_Farbe 0 "Standard_Farbe" 1 "abweichende_Farbe" ;
VAL_ 795 ESP_Off_Lampe 0 "Lampe_aus" 1 "Lampe_ein" ;
VAL_ 795 ESP_HDC_Regelgeschw 0 "nicht_verbaut" 125 "HDC_Standby" 126 "Init" 127 "Fehler" ;
VAL_ 795 ESP_BKV_Warnung 0 "keine_Anzeige" 1 "keine_Bremskraftverstaerkung" ;
VAL_ 508 ESP_Status_Bremsentemp_02 0 "nicht_erhoeht" 1 "Schwelle_1" 2 "Schwelle_2" ;
VAL_ 508 ESP_Aggregataktivitaet 0 "inaktiv" 1 "aktiv" ;
VAL_ 508 ESP_Stillstandsflag 0 "kein_Stillstand_erkannt" 1 "Stillstand_erkannt" ;
VAL_ 508 ESC_MBK_Meldungen 0 "kein_Text" 1 "MBK_Hinweis_aktiv" 2 "MBK_Eskalation1_aktiv" ;
VAL_ 508 ESP_EDS_Anzeige 0 "Keine_Anzeige_aktiv" 1 "EDS_nicht_aktiv" 2 "EDS_aktiv_an_VA" 3 "EDS_aktiv_an_HA" 4 "EDS_aktiv_an_VA_und_HA" 5 "EDS_Uebertemperatur" 6 "EDS_Fehler" ;
VAL_ 508 RLE_Anzeigen 0 "keine_Anzeige" 1 "Rad_lose_allgemein" 2 "Rad_VL_lose" 3 "Rad_VR_lose" 4 "Rad_HL_lose" 5 "Rad_HR_lose" 6 "RLE_Pruefphase" 7 "RLE_Systemstoerung" ;
VAL_ 508 ESP_Wiederstart_Anz_Std 0 "keine_Anzeige" 1 "Standard_Wiederstartgrund" ;
VAL_ 508 ESC_Anforderung_Airbrake 0 "keine_Anforderung" 1 "Anf_Bremsperformancestellung" ;
VAL_ 508 ESC_FBA_Meldungen 0 "kein_Text" 1 "FBA_Warnung_aktiv_MT" 2 "FBA_Warnung_aktiv_AT" ;
VAL_ 508 ESP_Rollover_Status_dyn 0 "Auspraegung1" 1 "Auspraegung2" 2 "Auspraegung3" 3 "Auspraegung4" ;
VAL_ 508 ESP_Rollover_Status_stat 0 "Auspraegung1" 1 "Auspraegung2" 2 "Auspraegung3" 3 "Auspraegung4" ;
VAL_ 508 ESP_AVH_LED 0 "LED_aus" 1 "LED_ein" 2 "LED_blinken" 3 "Funktion_gesperrt__LED_aus" 6 "Init" ;
VAL_ 508 ESP_HDC_LED 0 "LED_aus" 1 "LED_ein" 2 "LED_blinken" 3 "Funktion_gesperrt__LED_aus" 6 "Init" ;
VAL_ 508 ESP_Off_LED 0 "LED_aus" 1 "LED_ein" 2 "LED_blinken" 3 "Funktion_gesperrt__LED_aus" 6 "Init" ;
VAL_ 508 ESP_Notbremsanzeige 0 "keine_Notbremsung_erkannt" 1 "Notbremsung_erkannt" ;
VAL_ 508 ESC_Motorstartverzoegerung 0 "Startfreigabe" 1 "Anforderung_Startverzoegerung" ;
VAL_ 508 ESP_Offroad_Lampe 0 "Aus" 1 "Ein" ;
VAL_ 508 ESP_HDC_Textanzeigen 0 "kein_Text" 1 "HDC_ein" 2 "HDC_aus" 3 "HDC_nicht_verfuegbar_in_FahrPr" 4 "HDC_nicht_verfuegbar_Uebertemp" 5 "HDC_verfuegbar_keine_Uebertemp" 6 "HDC_nicht_verfuegbar_ACC_aktiv" 7 "HDC_nicht_verfuegbar_GRA_aktiv" 8 "HDC_nicht_verfuegbar_LIM_aktiv" 9 "HDC_nicht_verfuegbar_IPA_aktiv" 10 "HDC_nicht_verfuegbar_PLA_aktiv" 11 "HDC_nicht_verf_anderes_Syst_akt" 12 "HDC_nicht_verfuegbar_Fehler" 13 "GRA_Hebel_einschalten" 14 "Funk_nicht_verfuegbar_bei_HDC" 15 "Funk_verfuegbar_wenn_HDC_aktiv" 16 "Deaktivierung_ESP_Eingriff" 17 "HDC_nicht_verfuegbar_ABS_solo" 18 "HDC_nicht_verfuegbar_Gaspedal" ;
VAL_ 508 ESP_HOLD_verf 0 "nicht_verfuegbar" 1 "verfuegbar" ;
VAL_ 2589283470 ESC_Kilometer 1048574 "Init" 1048575 "Fehler" ;
VAL_ 2589283470 ESC_Kilometer_MUX 0 "GFA_Signierung" 1 "IKA_Signierung" ;
VAL_ 2589283470 ESC_Signatur_Kilometer_GFA_01 0 "Init" ;
VAL_ 2589283470 ESC_Signatur_Kilometer_IKA_01 0 "Init" ;
VAL_ 2589283470 ESC_Signatur_Kilometer_GFA_02 0 "Init" ;
VAL_ 2589283470 ESC_Signatur_Kilometer_IKA_02 0 "Init" ;
VAL_ 2527679662 ESP_Off_Anf_KBI 0 "keine_Anzeige" 1 "Anzeige_ESP_off_Popup" ;
VAL_ 2527679662 ESC_Rekueff_Bremsung 126 "Init" 127 "Fehler" ;
VAL_ 2527679662 ESC_Reku_Anzeige 0 "keine_Anzeige" 1 "Reku_Anzeige_aktiv" ;
VAL_ 2527679662 ESC_Anf_LadeVorhalt 0 "keine_Anforderung" 1 "SOC_Vorhalt_1_Prozent" 2 "SOC_Vorhalt_2_Prozent" 3 "SOC_Vorhalt_3_Prozent" 4 "SOC_Vorhalt_4_Prozent" 5 "SOC_Vorhalt_5_Prozent" 6 "SOC_Vorhalt_6_Prozent" 7 "SOC_Vorhalt_7_Prozent" 8 "SOC_Vorhalt_8_Prozent" 9 "SOC_Vorhalt_9_Prozent" 10 "SOC_Vorhalt_10_Prozent" 11 "SOC_Vorhalt_11_Prozent" 12 "SOC_Vorhalt_12_Prozent" 13 "SOC_Vorhalt_13_Prozent" 14 "SOC_Vorhalt_14_Prozent" 15 "Init" ;
VAL_ 2527679662 ESC_Textanzeigen_SysSpez 0 "kein_Text" 1 "Schiebedach_offen_Zwangsakt" 2 "Schiebedach_Stoerung_Zwangsakt" 3 "WETaktiv_ESCoff_nicht_verfuegbar" 4 "RANGEaktiv_ESCoff_nicht_verfuegb" ;
VAL_ 2527679662 BRS_BFLS_Verbauzustand 0 "Init" 1 "nicht_verbaut" 2 "verbaut" ;
VAL_ 2527679662 BRS_Bremsfluessigkeit_Warnungen 0 "Init" 1 "iO_keine_Anzeige" 2 "Warnstufe_1" 3 "Warnstufe_2" ;
VAL_ 2527679662 ESC_Anf_Bremsenkuehlung 0 "keine_Anforderung" 1 "SKE_oeffnen" 2 "SKE_oeffnen_Luefter_ansteuern" ;
VAL_ 600 ESP_DriftLevel 0 "Init" 1 "Level_1" 2 "Level_2" 3 "Level_3" 4 "Level_4" 5 "Level_5" 6 "Not_Available" ;
VAL_ 600 ESP_DriftText 0 "Text_1" 1 "Text_2" 2 "Text_3" 3 "Text_4" 4 "Text_5" 5 "Text_6" 6 "Text_7" 7 "Text_8" 8 "Text_9" 9 "Text_10" ;
VAL_ 600 ESP_DriftStatus 0 "Not_active" 1 "Active" ;
VAL_ 600 ESP_DriftGong 0 "Not_Active" 1 "Active" ;
VAL_ 600 ESP_Slider_Text 0 "Text_1" 1 "Text_2" 2 "Text_3" 3 "Text_4" 4 "Text_5" 5 "Text_6" 6 "Text_7" 7 "Text_8" 8 "Text_9" 9 "Text_10" ;
VAL_ 600 ESP_Slider_Lamp 0 "Lamp_off" 1 "Lamp_on" ;
VAL_ 600 ESP_Slider_Gong 0 "Not_Active" 1 "Active" ;
VAL_ 600 ESP_Slider_Status 0 "Not_active" 1 "Active" 2 "Disabled" ;
VAL_ 600 ESP_Slider_ist_01 127 "invalid" ;
VAL_ 600 ESP_Slider_ist_02 127 "invalid" ;
VAL_ 600 ESP_Slider_ist_03 127 "invalid" ;
VAL_ 303 ESP_vRef_abs 4094 "Init" 4095 "Fehler" ;
VAL_ 303 ESP_vRef_abs_classifier 0 "Level_1" 1 "Level_2" 2 "Level_3" 3 "Level_4" 4 "Level_5" 5 "Level_6" 6 "Level_7" 7 "Level_8" ;
VAL_ 303 ESP_Fahrbahnreibwert_dyn_Class 0 "Level_1" 1 "Level_2" 2 "Level_3" 3 "Level_4" 4 "Level_5" 5 "Level_6" 6 "Level_7" 7 "Level_8" ;
VAL_ 303 ESP_Fahrbahnreibwert_dyn 62 "Init" 63 "Fehler" ;
VAL_ 303 ESP_Schwimmwinkel 4094 "Init" 4095 "Fehler" ;
VAL_ 2527679824 PTLM_Warnung_2 0 "keine_Warnung" 1 "Warnmeldung_1_nicht_quittierbar" 2 "Warnmeldung_1_quittierbar" 3 "Warnmeldung_2_nicht_quittierbar" 4 "Warnmeldung_2_quittierbar" 5 "Hinweismeldung_TopSpeedMode_akti" ;
VAL_ 2527679824 EFP_WarnungBauteilschutz 0 "keine_Warnung" 1 "Hinweismeldung1" 2 "Hinweismeldung2" 3 "Warnmeldung1" 4 "Warnmeldung2" 5 "Reserve" 6 "Reserve" 7 "Reserve" ;
VAL_ 2527679824 EFP_WarnungAero 0 "keine_Warnung" 1 "Warnmeldung_1" 2 "Reserve" ;
VAL_ 2527679824 PTLM_vLimit 62 "Init" 63 "Fehler" ;
VAL_ 2527679824 PTLM_Warnung 0 "keine_Anzeige" 1 "Icon_TopSpeedMode" 2 "Meldung_2" ;
VAL_ 705 EFP_Verbau_DR 0 "nicht_verbaut" 1 "verbaut" ;
VAL_ 705 EFP_Verbau_eAllrad 0 "nicht_verbaut" 1 "verbaut" ;
VAL_ 705 EFP_Verbau_LF 0 "nicht_verbaut" 1 "verbaut" ;
VAL_ 705 LF_Texte 0 "keine_Anzeige" 1 "Text_Fahrzeug_momentan_zu_tief_Regelung_laeuft" 2 "Text_Fahrzeug_momentan_zu_hoch_Regelung_laeuft" 3 "Text_Niveauregelung_abgeschaltet" ;
VAL_ 705 EFP_Verbau_eAWS 0 "nicht_verbaut" 1 "verbaut" ;
VAL_ 705 eAWS_Warnmeldung_Prio1 0 "keine_Anzeige" 1 "kritische_Fehlermeldung" ;
VAL_ 705 eAWS_Warnmeldung_Prio2 0 "keine_Anzeige" 1 "milde_Fehlermeldung" ;
VAL_ 705 LF_Texte_2 0 "Init" 1 "keine_Anzeige" 2 "Text_Fahrzeug_Anheben_angeforder" 3 "Text_Fahrzeug_Absenken_angeforde" 4 "reserviert" 5 "reserviert" 6 "reserviert" 7 "reserviert" 8 "reserviert" 9 "reserviert" 10 "reserviert" 11 "reserviert" 12 "reserviert" 13 "reserviert" 14 "reserviert" 15 "reserviert" ;
VAL_ 705 EFP_Status_Taster_Lift 0 "Keine_Anzeige" 1 "Status1" 2 "Status2" 3 "Status3" ;
VAL_ 705 EFP_Status_Taster_Fahrwerk 0 "Keine_Anzeige" 1 "Status1" 2 "Status2" 3 "Status3" ;
VAL_ 705 FDR_Warnung_ALR 0 "keine_Anzeige" 1 "Text_Stoerung_Allradverteilung" 2 "Text_Ausfall_Allradverteilung" 3 "reserved" ;
VAL_ 705 FDR_Warnung_TV 0 "keine_Anzeige" 1 "Text_Stoerung_TorqueVectoring" 2 "Text_Ausfall_TorqueVectoring" 3 "reserviert" ;
VAL_ 705 EFP_Verbau_eABC 0 "nicht_verbaut" 1 "verbaut" ;
VAL_ 705 LF_Warnung_Prio1_02 0 "keine_Anzeige" 1 "Text_Servicemodus" 2 "Text_Fehler_Luftfeder_Geschwindigkeit_1" 3 "Text_Fehler_Luftfeder_Geschwindigkeit_2" 4 "Text_Fehler_Luftfeder_Begrenzung_v_1" 5 "Text_Fehler_Luftfeder_Begrenzung_v_2" 6 "Text_Fehler_LuFe_Fzg_abstellen" ;
VAL_ 705 LF_Warnung_Prio1 0 "keine_Anzeige" 1 "Text_Servicemodus" 2 "Text_Fehler_Luftfeder_Geschwindigkeit_1" 3 "Text_Fehler_Luftfeder_Geschwindigkeit_2" ;
VAL_ 705 LF_Warnung_Prio2 0 "keine_Anzeige" 1 "Text_Fahrzeug_zu_tief_Bodenfreiheit_eingeschraenkt" 2 "Text_Fehler_Luftfeder" 3 "tbd" ;
VAL_ 705 eABC_Warnung_Prio2 0 "keine_Anzeige" 1 "Text_Stoerung_eABC_service_aufsuchen" 2 "Text_Stoerung_eABC_Bodenfreiheit_eingeschraenkt" 3 "Text_eABC_nicht_verfuegbar" ;
VAL_ 705 eABC_Warnung_Prio1 0 "keine_Anzeige" 1 "Text_Servicemodus" 2 "Text_Fehler_eABC_eingeschraenkte_Lenkbarkeit" 3 "Text_Fehler_eABC_eingeschraenkte_Fahrstabilitaet" 4 "Text_Fehler_eABC_eingeschraenkte_Geschwindigkeit" ;
VAL_ 705 eABC_Texte 0 "keine_Anzeige" 1 "Text_eABC_Vorausschau_nicht_verf" 2 "Text_eABC_Radwechselmodus" 3 "Text_eABC_Standfunktion_nicht_verfuegbar" 4 "Text_eABC_zur_Zeit_nicht_verfueg" 5 "Text_eABC_zur_Zeit_eingeschraenk" ;
VAL_ 705 DR_Warnung 0 "keine_Anzeige" 1 "Text_Fehler_Daempfer" ;
VAL_ 705 NR_LED_Offroadlevel 0 "LED_aus_und_Blinken_aus" 1 "LED_ein_und_Blinken_aus" 2 "LED_ein_und_Blinken_ein" 3 "Init" ;
VAL_ 705 NR_LED_Ladelevel 0 "LED_aus_und_Blinken_aus" 1 "LED_ein_und_Blinken_aus" 2 "LED_ein_und_Blinken_ein" 3 "Init" ;
VAL_ 705 NR_LED_Sync 0 "LED_aus_und_Blinken_aus" 1 "LED_ein_und_Blinken_aus" 2 "LED_ein_und_Blinken_ein" 3 "Init" ;
VAL_ 705 NR_LED_XtraLevel 0 "LED_aus_und_Blinken_aus" 1 "LED_ein_und_Blinken_aus" 2 "LED_ein_und_Blinken_ein" 3 "Init" ;
VAL_ 705 NR_LED_Strassenlevel 0 "LED_aus_und_Blinken_aus" 1 "LED_ein_und_Blinken_aus" 2 "LED_ein_und_Blinken_ein" 3 "Init" ;
VAL_ 705 EFP_Warnung_Naesse 0 "keine_Anzeige" 1 "Naesse_Meldung1" 2 "Naesse_Meldung2" 3 "Naesse_Meldung3" 4 "Naesse_Meldung4" 5 "Naesse_Meldung5" 6 "Naesse_Meldung6" 7 "Naesse_Meldung7" ;
VAL_ 705 EFP_Warnung_Naesse_verf 0 "verfuegbar" 1 "nicht_verfuegbar" ;
